// *************************************************************************** *
// *                                                                           *
// *                      Mentor Graphics Corporation                          *
// *                          All rights reserved                              *
// *                                                                           *
// *************************************************************************** *
// *                                                                           *
// * Description:         Partial CANDB File (for BMS Node)                    *
// * Generated at:        2025-09-16 19:54                                     *
// * Node                 BMS                                                  *
// *                                                                           *
// *************************************************************************** *
// *                                                                           *
// *             THIS CONFIGURATION MIGHT CONTAIN SOME ERRORS                  *
// *              IF THE INPUT MODEL WAS NOT PROPERLY FORMED!                  *
// *                    Do Not Use this File directly!                         *
// *                                                                           *
// *************************************************************************** *
VERSION "BMS"

NS_ :

BS_ :

BU_ : BMS

BO_ 1021 BMS_PTCANFD_0x3FD : 32 BMS
 SG_ HvBattTempRSMS65 : 7|9@0+ (0.5,-40.0) [-40.0|215.5] "℃" Vector__XXX
 SG_ HvBattTempRSMS66 : 23|9@0+ (0.5,-40.0) [-40.0|215.5] "℃" Vector__XXX
 SG_ HvBattTempRSMS67 : 39|9@0+ (0.5,-40.0) [-40.0|215.5] "℃" Vector__XXX
 SG_ HvBattTempRSMS68 : 55|9@0+ (0.5,-40.0) [-40.0|215.5] "℃" Vector__XXX
 SG_ HvBattTempRSMS69 : 71|9@0+ (0.5,-40.0) [-40.0|215.5] "℃" Vector__XXX
 SG_ HvBattTempRSMS70 : 87|9@0+ (0.5,-40.0) [-40.0|215.5] "℃" Vector__XXX
 SG_ HvBattTempRSMS71 : 103|9@0+ (0.5,-40.0) [-40.0|215.5] "℃" Vector__XXX
 SG_ HvBattTempRSMS72 : 119|9@0+ (0.5,-40.0) [-40.0|215.5] "℃" Vector__XXX
 SG_ HvBattTempRSMS73 : 135|9@0+ (0.5,-40.0) [-40.0|215.5] "℃" Vector__XXX
 SG_ HvBattTempRSMS74 : 151|9@0+ (0.5,-40.0) [-40.0|215.5] "℃" Vector__XXX
 SG_ HvBattTempRSMS75 : 167|9@0+ (0.5,-40.0) [-40.0|215.5] "℃" Vector__XXX
 SG_ HvBattTempRSMS76 : 183|9@0+ (0.5,-40.0) [-40.0|215.5] "℃" Vector__XXX
 SG_ HvBattTempRSMS77 : 199|9@0+ (0.5,-40.0) [-40.0|215.5] "℃" Vector__XXX
 SG_ HvBattTempRSMS78 : 215|9@0+ (0.5,-40.0) [-40.0|215.5] "℃" Vector__XXX
 SG_ HvBattTempRSMS79 : 231|9@0+ (0.5,-40.0) [-40.0|215.5] "℃" Vector__XXX
 SG_ HvBattTempRSMS80 : 247|9@0+ (0.5,-40.0) [-40.0|215.5] "℃" Vector__XXX

BO_ 1022 BMS_PTCANFD_0x3FE : 32 BMS
 SG_ HvBattTempRSMS81 : 7|9@0+ (0.5,-40.0) [-40.0|215.5] "℃" Vector__XXX
 SG_ HvBattTempRSMS82 : 23|9@0+ (0.5,-40.0) [-40.0|215.5] "℃" Vector__XXX
 SG_ HvBattTempRSMS83 : 39|9@0+ (0.5,-40.0) [-40.0|215.5] "℃" Vector__XXX
 SG_ HvBattTempRSMS84 : 55|9@0+ (0.5,-40.0) [-40.0|215.5] "℃" Vector__XXX
 SG_ HvBattTempRSMS85 : 71|9@0+ (0.5,-40.0) [-40.0|215.5] "℃" Vector__XXX
 SG_ HvBattTempRSMS86 : 87|9@0+ (0.5,-40.0) [-40.0|215.5] "℃" Vector__XXX
 SG_ HvBattTempRSMS87 : 103|9@0+ (0.5,-40.0) [-40.0|215.5] "℃" Vector__XXX
 SG_ HvBattTempRSMS88 : 119|9@0+ (0.5,-40.0) [-40.0|215.5] "℃" Vector__XXX
 SG_ HvBattTempRSMS89 : 135|9@0+ (0.5,-40.0) [-40.0|215.5] "℃" Vector__XXX
 SG_ HvBattTempRSMS90 : 151|9@0+ (0.5,-40.0) [-40.0|215.5] "℃" Vector__XXX
 SG_ HvBattTempRSMS91 : 167|9@0+ (0.5,-40.0) [-40.0|215.5] "℃" Vector__XXX
 SG_ HvBattTempRSMS92 : 183|9@0+ (0.5,-40.0) [-40.0|215.5] "℃" Vector__XXX
 SG_ HvBattTempRSMS93 : 199|9@0+ (0.5,-40.0) [-40.0|215.5] "℃" Vector__XXX
 SG_ HvBattTempRSMS94 : 215|9@0+ (0.5,-40.0) [-40.0|215.5] "℃" Vector__XXX
 SG_ HvBattTempRSMS95 : 231|9@0+ (0.5,-40.0) [-40.0|215.5] "℃" Vector__XXX
 SG_ HvBattTempRSMS96 : 247|9@0+ (0.5,-40.0) [-40.0|215.5] "℃" Vector__XXX

BO_ 137 BMS_PTCANFD_0x89 : 8 BMS
 SG_ HvBattChargerNumber : 7|32@0+ (1.0,0.0) [0.0|268435455.0] "" Vector__XXX
 SG_ HvBattChargerRegionalCode : 39|24@0+ (1.0,0.0) [0.0|16777215.0] "" Vector__XXX

BO_ 145 BMS_PTCANFD_0x91 : 48 BMS
 SG_ BMSChrgrCntctSts : 191|3@0+ (1,0) [0|7] "" Vector__XXX
 SG_ BoostChrgnOutpCurReq : 271|14@0+ (0.1,0.0) [0.0|1000.0] "A" Vector__XXX
 SG_ BoostChrgnOutpReqSigGrpChks : 255|8@0+ (1.0,0.0) [0.0|255.0] "" Vector__XXX
 SG_ BoostChrgnOutpReqSigGrpCntr : 259|4@0+ (1.0,0.0) [0.0|15.0] "" Vector__XXX
 SG_ BoostChrgnOutpUReq : 287|14@0+ (0.1,0.0) [0.0|1638.3000000000002] "V" Vector__XXX
 SG_ ChrgnNotAvlForFault : 143|2@0+ (1,0) [0|3] "" Vector__XXX
 SG_ ChrgnNotAvlForT : 132|2@0+ (1,0) [0|3] "" Vector__XXX
 SG_ DCChrgrConnectnSts : 135|3@0+ (1,0) [0|7] "" Vector__XXX
 SG_ DCChrgrSigGrpChks : 119|8@0+ (1,0) [0|255] "" Vector__XXX
 SG_ DCChrgrSigGrpCntr : 123|4@0+ (1,0) [0|15] "" Vector__XXX
 SG_ DchaNotAvlForFlt : 129|2@0+ (1,0) [0|3] "" Vector__XXX
 SG_ HvBattActBusU : 71|14@0+ (0.1,0.0) [0.0|1638.2] "V" Vector__XXX
 SG_ HvBattActCur : 87|16@0+ (0.1,-3276.7) [-3276.7|3276.7000000000007] "A" Vector__XXX
 SG_ HvBattActPackU : 47|14@0+ (0.1,0.0) [0.0|1638.2] "V" Vector__XXX
 SG_ HvBattActPwr : 159|13@0+ (0.25,-1000.0) [-1000.0|1047.75] "Kw" Vector__XXX
 SG_ HvBattaftcoolgReq : 243|1@0+ (1,0) [0|1] "" Vector__XXX
 SG_ HvBattBkdheatgReq : 245|1@0+ (1,0) [0|1] "" Vector__XXX
 SG_ HvBattDrtSts : 247|1@0+ (1,0) [0|1] "" Vector__XXX
 SG_ HvBattFltLvlIndcn : 63|3@0+ (1,0) [0|7] "" Vector__XXX
 SG_ HvBattMaxPwrChrgn : 27|12@0+ (0.25,0.0) [0.0|1000.0] "kW" Vector__XXX
 SG_ HvBattMaxPwrDchrgn : 103|13@0+ (0.25,0.0) [0.0|2047.75] "kW" Vector__XXX
 SG_ HvBattMaxPwrDchrgnContns : 175|12@0+ (0.25,0.0) [0.0|1000.0] "kW" Vector__XXX
 SG_ HvBattModSts : 147|4@0+ (1,0) [0|15] "" Vector__XXX
 SG_ HvBattOverHeatWarn : 73|1@0+ (1,0) [0|1] "" Vector__XXX
 SG_ HvBattSigGrpChks : 7|8@0+ (1,0) [0|255] "" Vector__XXX
 SG_ HvBattSigGrpCntr : 11|4@0+ (1,0) [0|15] "" Vector__XXX
 SG_ HvBattThermModReq : 151|4@0+ (1,0) [0|15] "" Vector__XXX
 SG_ HvBattUkl30LowWarn : 244|1@0+ (1,0) [0|1] "" Vector__XXX
 SG_ HvBattWrmgReq : 246|1@0+ (1,0) [0|1] "" Vector__XXX
 SG_ HVOffReq : 49|2@0+ (1,0) [0|3] "" Vector__XXX
 SG_ MainCntctCtrlFlg : 223|1@0+ (1,0) [0|1] "" Vector__XXX
 SG_ MainCntctInhbn : 161|1@0+ (1,0) [0|1] "" Vector__XXX
 SG_ MainCntctSts : 222|2@0+ (1,0) [0|3] "" Vector__XXX
 SG_ MainCntctStsSigGrpChks : 207|8@0+ (1,0) [0|255] "" Vector__XXX
 SG_ MainCntctStsSigGrpCntr : 211|4@0+ (1,0) [0|15] "" Vector__XXX
 SG_ MainNegCntctSts : 15|2@0+ (1,0) [0|3] "" Vector__XXX
 SG_ MainPosCntctSts : 13|2@0+ (1,0) [0|3] "" Vector__XXX
 SG_ OverChargeCurrFatalFault : 179|1@0+ (1,0) [0|1] "" Vector__XXX
 SG_ OverDischargeCurrFatalFault : 178|1@0+ (1,0) [0|1] "" Vector__XXX
 SG_ PrechrgnCntctSts : 242|2@0+ (1,0) [0|3] "" Vector__XXX

BO_ 148 BMS_PTCANFD_0x94 : 48 BMS
 SG_ CrsPwmSts : 255|2@0+ (1,0) [0|3] "" Vector__XXX
 SG_ GaCMDAfeComErrFault : 22|1@0+ (1,0) [0|1] "" Vector__XXX
 SG_ GaCMDCellVoltOpenWireLv1F : 41|1@0+ (1,0) [0|1] "" Vector__XXX
 SG_ GaCMDCellVoltOpenWireLv2F : 83|1@0+ (1,0) [0|1] "" Vector__XXX
 SG_ GaCMDCellVoltSamplingChipFault : 19|1@0+ (1,0) [0|1] "" Vector__XXX
 SG_ GaCMDModltempOpenWireLv1F : 20|1@0+ (1,0) [0|1] "" Vector__XXX
 SG_ GaCMDModltempOpenWireLv2F : 82|1@0+ (1,0) [0|1] "" Vector__XXX
 SG_ GaCMDModlTempSamplingChipFault : 43|1@0+ (1,0) [0|1] "" Vector__XXX
 SG_ GaCVTAfeCellVoltOORFault : 64|1@0+ (1,0) [0|1] "" Vector__XXX
 SG_ GeBCVBatteryOverVoltageFault : 12|1@0+ (1,0) [0|1] "" Vector__XXX
 SG_ GeBCVBatteryUnderVoltageFault : 79|1@0+ (1,0) [0|1] "" Vector__XXX
 SG_ GeBCVBatteryVoltageOoRFault : 5|1@0+ (1,0) [0|1] "" Vector__XXX
 SG_ GeBCVDCFuseOLFault : 34|1@0+ (1,0) [0|1] "" Vector__XXX
 SG_ GeBCVDCFuseOoRFault : 33|1@0+ (1,0) [0|1] "" Vector__XXX
 SG_ GeBCVHVADCComDiagFault : 78|1@0+ (1,0) [0|1] "" Vector__XXX
 SG_ GeBCVMainDriveFuseOLFault : 77|1@0+ (1,0) [0|1] "" Vector__XXX
 SG_ GeBCVMainDriveFuseOoRFault : 6|1@0+ (1,0) [0|1] "" Vector__XXX
 SG_ GeBCVPackVoltageMismatchFault : 32|1@0+ (1,0) [0|1] "" Vector__XXX
 SG_ GeBCVShuntADCSpiComFault : 76|1@0+ (1,0) [0|1] "" Vector__XXX
 SG_ GeBCVShunttempHighFault : 75|1@0+ (1,0) [0|1] "" Vector__XXX
 SG_ GeBCVShunttempLowFault : 74|1@0+ (1,0) [0|1] "" Vector__XXX
 SG_ GeBCVVdncGpknOoRFault : 73|1@0+ (1,0) [0|1] "" Vector__XXX
 SG_ GeBCVVdpcGpknOoRFault : 47|1@0+ (1,0) [0|1] "" Vector__XXX
 SG_ GeBCVVmncGpknOoRFault : 7|1@0+ (1,0) [0|1] "" Vector__XXX
 SG_ GeBCVVmpcGpknOoRFault : 72|1@0+ (1,0) [0|1] "" Vector__XXX
 SG_ GeBMMKL30CLowVoltageFault : 87|1@0+ (1,0) [0|1] "" Vector__XXX
 SG_ GeBMMKL30CUnderVoltageFault : 8|1@0+ (1,0) [0|1] "" Vector__XXX
 SG_ GeBMMKL30CVoltSrcMaxFault : 9|1@0+ (1,0) [0|1] "" Vector__XXX
 SG_ GeBMMKL30CVoltSrcMinFault : 10|1@0+ (1,0) [0|1] "" Vector__XXX
 SG_ GeBMMKL30VoltSrcMaxFault : 11|1@0+ (1,0) [0|1] "" Vector__XXX
 SG_ GeBMMKL30VoltSrcMinFault : 86|1@0+ (1,0) [0|1] "" Vector__XXX
 SG_ GeCMDAfeDietempMsgCheckFailFault : 85|1@0+ (1,0) [0|1] "" Vector__XXX
 SG_ GeCMDAfeDietempMsgTimeoutFault : 84|1@0+ (1,0) [0|1] "" Vector__XXX
 SG_ GeCMDCellBaltempMsgCheckFailF : 40|1@0+ (1,0) [0|1] "" Vector__XXX
 SG_ GeCMDDaisyChainComSuspendFault : 3|1@0+ (1,0) [0|1] "" Vector__XXX
 SG_ GeCRSVehicleCrashFault : 80|1@0+ (1,0) [0|1] "" Vector__XXX
 SG_ GeCTDDCFuseBlownFault : 2|1@0+ (1,0) [0|1] "" Vector__XXX
 SG_ GeCTDDNCStuckcloseFault : 95|1@0+ (1,0) [0|1] "" Vector__XXX
 SG_ GeCTDDNCStuckopenFault : 55|1@0+ (1,0) [0|1] "" Vector__XXX
 SG_ GeCTDDPCStuckcloseFault : 13|1@0+ (1,0) [0|1] "" Vector__XXX
 SG_ GeCTDDPCStuckopenFault : 54|1@0+ (1,0) [0|1] "" Vector__XXX
 SG_ GeCTDMDFuseBlownFault : 53|1@0+ (1,0) [0|1] "" Vector__XXX
 SG_ GeCTDMNCStuckcloseFault : 94|1@0+ (1,0) [0|1] "" Vector__XXX
 SG_ GeCTDMNCStuckopenFault : 52|1@0+ (1,0) [0|1] "" Vector__XXX
 SG_ GeCTDMPCStuckcloseFault : 93|1@0+ (1,0) [0|1] "" Vector__XXX
 SG_ GeCTDMPCStuckopenFault : 92|1@0+ (1,0) [0|1] "" Vector__XXX
 SG_ GeCTDMPRStuckopenFault : 14|1@0+ (1,0) [0|1] "" Vector__XXX
 SG_ GeCTDPrechargeBusShortFault : 51|1@0+ (1,0) [0|1] "" Vector__XXX
 SG_ GeCTDPrechargeTimeoutFault : 50|1@0+ (1,0) [0|1] "" Vector__XXX
 SG_ GeCTSPrechargeOverTimesFault : 49|1@0+ (1,0) [0|1] "" Vector__XXX
 SG_ GeCVTCellOverVoltL1Fault : 15|1@0+ (1,0) [0|1] "" Vector__XXX
 SG_ GeCVTCellOverVoltL2Fault : 91|1@0+ (1,0) [0|1] "" Vector__XXX
 SG_ GeCVTCellOverVoltL3Fault : 48|1@0+ (1,0) [0|1] "" Vector__XXX
 SG_ GeCVTCellOverVoltL4Fault : 16|1@0+ (1,0) [0|1] "" Vector__XXX
 SG_ GeCVTCellUnderVoltL1Fault : 90|1@0+ (1,0) [0|1] "" Vector__XXX
 SG_ GeCVTCellUnderVoltL2Fault : 63|1@0+ (1,0) [0|1] "" Vector__XXX
 SG_ GeCVTCellUnderVoltL3Fault : 89|1@0+ (1,0) [0|1] "" Vector__XXX
 SG_ GeCVTCellUnderVoltL4Fault : 88|1@0+ (1,0) [0|1] "" Vector__XXX
 SG_ GeCVTCellVoltOverDeviationL1F : 62|1@0+ (1,0) [0|1] "" Vector__XXX
 SG_ GeCVTCellVoltOverDeviationL2F : 61|1@0+ (1,0) [0|1] "" Vector__XXX
 SG_ GeDCCAPlusVoltageOoRFault : 60|1@0+ (1,0) [0|1] "" Vector__XXX
 SG_ GeDCCCC2VoltageAbnormalFault : 103|1@0+ (1,0) [0|1] "" Vector__XXX
 SG_ GeDCCConnectortempHighFault : 101|1@0+ (1,0) [0|1] "" Vector__XXX
 SG_ GeDCCConnectortempHighWarningF : 100|1@0+ (1,0) [0|1] "" Vector__XXX
 SG_ GeHVILVIL2CircuitOpenFault : 58|1@0+ (1,0) [0|1] "" Vector__XXX
 SG_ GePFCPyroFuseCloseFault : 57|1@0+ (1,0) [0|1] "" Vector__XXX
 SG_ GePFCPyroFuseOpenFault : 56|1@0+ (1,0) [0|1] "" Vector__XXX
 SG_ GePRXPrivateCANBusOffFault : 99|1@0+ (1.0,0.0) [0.0|1.0] "" Vector__XXX
 SG_ GeSOFDischargeOverCurrentLv1F : 17|1@0+ (1,0) [0|1] "" Vector__XXX
 SG_ GeSOFDischargeOverCurrentLv2F : 18|1@0+ (1,0) [0|1] "" Vector__XXX
 SG_ GeSOFDischargeOverCurrentLv3F : 46|1@0+ (1,0) [0|1] "" Vector__XXX
 SG_ GeSOFDischargeOverCurrentLv4F : 45|1@0+ (1,0) [0|1] "" Vector__XXX
 SG_ GeSOFDischargeOverCurrentLv5F : 44|1@0+ (1,0) [0|1] "" Vector__XXX
 SG_ GeSOFRegenChargeOverCurrentLv1F : 71|1@0+ (1,0) [0|1] "" Vector__XXX
 SG_ GeSOFRegenChargeOverCurrentLv2F : 70|1@0+ (1,0) [0|1] "" Vector__XXX
 SG_ GeSOFRegenChargeOverCurrentLv3F : 21|1@0+ (1,0) [0|1] "" Vector__XXX
 SG_ GeSOFRegenChargeOverCurrentLv4F : 81|1@0+ (1,0) [0|1] "" Vector__XXX
 SG_ GeSOFRegenChargeOverCurrentLv5F : 42|1@0+ (1,0) [0|1] "" Vector__XXX
 SG_ GeTHMCoolFlowMismatchFault : 69|1@0+ (1,0) [0|1] "" Vector__XXX
 SG_ GeTHMCoolSysFault : 68|1@0+ (1,0) [0|1] "" Vector__XXX
 SG_ GeTHMHeatFlowMismatchFault : 67|1@0+ (1,0) [0|1] "" Vector__XXX
 SG_ GeTHMInlettempHighFault : 98|1@0+ (1,0) [0|1] "" Vector__XXX
 SG_ GeTHMInlettempLowFault : 66|1@0+ (1,0) [0|1] "" Vector__XXX
 SG_ GeTHRThermalRunAwayFault : 97|1@0+ (1,0) [0|1] "" Vector__XXX
 SG_ GeVRXPTCANBusOffFault : 65|1@0+ (1,0) [0|1] "" Vector__XXX
 SG_ GeVRXVCCD090TimeOutFault : 96|1@0+ (1,0) [0|1] "" Vector__XXX
 SG_ GeVRXVCCD271TimeOutFault : 111|1@0+ (1,0) [0|1] "" Vector__XXX
 SG_ HvBattCntctCtrlSt : 183|8@0+ (1.0,0.0) [0.0|255.0] "" Vector__XXX
 SG_ HvbattCrsPwmStsSigGrpChks : 239|8@0+ (1.0,0.0) [0.0|255.0] "" Vector__XXX
 SG_ HvbattCrsPwmStsSigGrpCntr : 243|4@0+ (1.0,0.0) [0.0|15.0] "" Vector__XXX
 SG_ HvBattCurLimMax : 135|16@0+ (1.0,-32767.0) [-32767.0|32768.0] "A" Vector__XXX
 SG_ HvBattCurLimMin : 151|16@0+ (1.0,-32767.0) [-32767.0|32768.0] "A" Vector__XXX
 SG_ HvBattDevmtGrp01 : 263|32@0+ (1.0,0.0) [0.0|0.0] "" Vector__XXX
 SG_ HvBattDevmtGrp02 : 295|32@0+ (1.0,0.0) [0.0|0.0] "" Vector__XXX
 SG_ HvBattDevmtGrp03 : 327|32@0+ (1.0,0.0) [0.0|0.0] "" Vector__XXX
 SG_ HvBattDevmtGrp04 : 359|32@0+ (1.0,0.0) [0.0|0.0] "" Vector__XXX
 SG_ HvBattDNCHSDEna : 173|1@0+ (1,0) [0|1] "" Vector__XXX
 SG_ HvBattDNCLSDEna : 172|1@0+ (1,0) [0|1] "" Vector__XXX
 SG_ HvBattDPCHSDEna : 171|1@0+ (1,0) [0|1] "" Vector__XXX
 SG_ HvBattDPCLSDEna : 169|1@0+ (1,0) [0|1] "" Vector__XXX
 SG_ HvBattInsulGndSwtSt : 168|1@0+ (1,0) [0|1] "" Vector__XXX
 SG_ HvBattInsulNegSwtSt : 167|1@0+ (1,0) [0|1] "" Vector__XXX
 SG_ HvBattInsulPosSwtSt : 166|1@0+ (1,0) [0|1] "" Vector__XXX
 SG_ HvBattMNCHSDEna : 165|1@0+ (1,0) [0|1] "" Vector__XXX
 SG_ HvBattMNCLSDEna : 164|1@0+ (1,0) [0|1] "" Vector__XXX
 SG_ HvBattMPCHSDEna : 163|1@0+ (1,0) [0|1] "" Vector__XXX
 SG_ HvBattMPCLSDEna : 162|1@0+ (1,0) [0|1] "" Vector__XXX
 SG_ HvBattMPRHSDEna : 161|1@0+ (1,0) [0|1] "" Vector__XXX
 SG_ HvBattMPRLSDEna : 160|1@0+ (1,0) [0|1] "" Vector__XXX
 SG_ HvBattUkl30 : 119|9@0+ (0.1,0.0) [0.0|51.1] "V" Vector__XXX
 SG_ HvBattWorkSts : 191|8@0+ (1.0,0.0) [0.0|255.0] "" Vector__XXX
 SG_ HVISOMeasState : 37|3@0+ (1.0,0.0) [0.0|7.0] "" Vector__XXX
 SG_ HVIsoNegVolt : 199|15@0+ (0.1,-1638.4) [-1638.4|1638.3000000000002] "" Vector__XXX
 SG_ HVIsoPosVolt : 215|15@0+ (0.1,-1638.4) [-1638.4|1638.3000000000002] "" Vector__XXX
 SG_ IsoGndMosDiagVolt : 31|8@0+ (0.1,0.0) [0.0|25.5] "V" Vector__XXX
 SG_ PyroFuseSts : 1|1@0+ (1,0) [0|1] "" Vector__XXX

BO_ 159 BMS_PTCANFD_0x9F : 16 BMS
 SG_ HvBattCSR21 : 7|32@0+ (1,0) [0|4294967295] "" Vector__XXX
 SG_ HvBattCSR22 : 39|32@0+ (1,0) [0|4294967295] "" Vector__XXX
 SG_ HvBattCSR23 : 71|32@0+ (1,0) [0|4294967295] "" Vector__XXX
 SG_ HvBattCSR24 : 103|32@0+ (1,0) [0|4294967295] "" Vector__XXX

BO_ 1305 BMSPtCanfdNMFr : 8 BMS
 SG_ BMSPtCanfdActiveWakeup : 12|1@0+ (1,0) [0|1] "" Vector__XXX
 SG_ BMSPtCanfdNodeAddress : 7|8@0+ (1.0,0.0) [0.0|255.0] "" Vector__XXX
 SG_ BMSPtCanfdRepeatMsgReq : 8|1@0+ (1,0) [0|1] "" Vector__XXX
 SG_ BMSPtCanfdRepeatMsgSt : 16|1@0+ (1,0) [0|1] "" Vector__XXX
 SG_ NMKeepAwkRsnBMS : 48|9@0+ (1.0,0.0) [0.0|511.0] "" Vector__XXX
 SG_ PNC55BMS : 55|1@0+ (1,0) [0|1] "" Vector__XXX
 SG_ UDB17BMS : 17|1@0+ (1,0) [0|1] "" Vector__XXX
 SG_ UDB18BMS : 18|1@0+ (1,0) [0|1] "" Vector__XXX
 SG_ UDB19BMS : 19|1@0+ (1,0) [0|1] "" Vector__XXX
 SG_ UDB20BMS : 20|1@0+ (1,0) [0|1] "" Vector__XXX
 SG_ UDB21BMS : 21|1@0+ (1,0) [0|1] "" Vector__XXX
 SG_ UDB22BMS : 22|1@0+ (1,0) [0|1] "" Vector__XXX
 SG_ UDB23BMS : 23|1@0+ (1,0) [0|1] "" Vector__XXX
 SG_ UDB24BMS : 24|1@0+ (1,0) [0|1] "" Vector__XXX
 SG_ UDB25BMS : 25|1@0+ (1,0) [0|1] "" Vector__XXX
 SG_ UDB26BMS : 26|1@0+ (1,0) [0|1] "" Vector__XXX
 SG_ UDB27BMS : 27|1@0+ (1,0) [0|1] "" Vector__XXX
 SG_ UDB28BMS : 28|1@0+ (1,0) [0|1] "" Vector__XXX
 SG_ UDB29BMS : 29|1@0+ (1,0) [0|1] "" Vector__XXX
 SG_ UDB30BMS : 30|1@0+ (1,0) [0|1] "" Vector__XXX
 SG_ UDB31BMS : 31|1@0+ (1,0) [0|1] "" Vector__XXX
 SG_ UDB32BMS : 32|1@0+ (1,0) [0|1] "" Vector__XXX
 SG_ UDB33BMS : 33|1@0+ (1,0) [0|1] "" Vector__XXX
 SG_ UDB34BMS : 34|1@0+ (1,0) [0|1] "" Vector__XXX
 SG_ UDB35BMS : 35|1@0+ (1,0) [0|1] "" Vector__XXX
 SG_ UDB36BMS : 36|1@0+ (1,0) [0|1] "" Vector__XXX
 SG_ UDB37BMS : 37|1@0+ (1,0) [0|1] "" Vector__XXX
 SG_ UDB38BMS : 38|1@0+ (1,0) [0|1] "" Vector__XXX
 SG_ UDB39BMS : 39|1@0+ (1,0) [0|1] "" Vector__XXX
 SG_ UDB40BMS : 40|1@0+ (1.0,0.0) [0.0|1.0] "" Vector__XXX
 SG_ UDB41BMS : 41|1@0+ (1,0) [0|1] "" Vector__XXX
 SG_ UDB42BMS : 42|1@0+ (1,0) [0|1] "" Vector__XXX
 SG_ UDB43BMS : 43|1@0+ (1,0) [0|1] "" Vector__XXX
 SG_ UDB44BMS : 44|1@0+ (1,0) [0|1] "" Vector__XXX
 SG_ UDB45BMS : 45|1@0+ (1,0) [0|1] "" Vector__XXX
 SG_ UDB46BMS : 46|1@0+ (1,0) [0|1] "" Vector__XXX
 SG_ UDB47BMS : 47|1@0+ (1.0,0.0) [0.0|1.0] "" Vector__XXX

BO_ 1588 BMSToXCDPtDiagRespFr : 64 BMS
 SG_ BMSToVCCDDiagResp : 7|512@0+ (1,0) [0|0] "" Vector__XXX

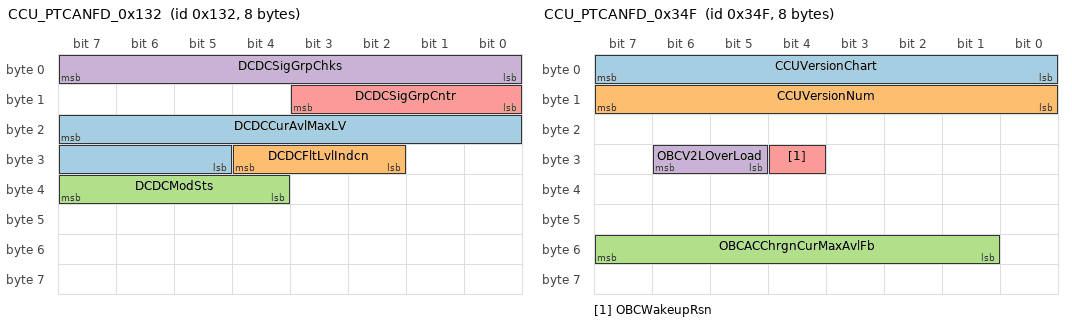
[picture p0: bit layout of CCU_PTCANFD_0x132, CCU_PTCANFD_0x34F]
BO_ 306 CCU_PTCANFD_0x132 : 8 BMS
 SG_ DCDCCurAvlMaxLV : 23|11@0+ (0.5,0.0) [0.0|1023.0] "A" Vector__XXX
 SG_ DCDCFltLvlIndcn : 28|3@0+ (1,0) [0|7] "" Vector__XXX
 SG_ DCDCModSts : 39|4@0+ (1,0) [0|15] "" Vector__XXX
 SG_ DCDCSigGrpChks : 7|8@0+ (1.0,0.0) [0.0|255.0] "" Vector__XXX
 SG_ DCDCSigGrpCntr : 11|4@0+ (1.0,0.0) [0.0|15.0] "" Vector__XXX

BO_ 320 CCU_PTCANFD_0x140 : 48 BMS
 SG_ CCUSensKL30U : 279|9@0+ (0.1,0.0) [0.0|51.1] "V" Vector__XXX
 SG_ DCDCPrechrgLvUVPFstVal : 343|9@0+ (0.1,0.0) [0.0|51.1] "V" Vector__XXX
 SG_ OBCAcCurActL1 : 138|11@0+ (0.1,-102.4) [-102.4|102.20000000000002] "A" Vector__XXX
 SG_ OBCAcCurActL2 : 162|11@0+ (0.1,-102.4) [-102.4|102.20000000000002] "A" Vector__XXX
 SG_ OBCAcCurActL3 : 186|11@0+ (0.1,-102.4) [-102.4|102.20000000000002] "A" Vector__XXX
 SG_ OBCAcU1Frq : 222|7@0+ (1.0,0.0) [0.0|127.0] "Hz" Vector__XXX
 SG_ OBCAcU2Frq : 134|7@0+ (1.0,0.0) [0.0|127.0] "Hz" Vector__XXX
 SG_ OBCAcU3Frq : 255|7@0+ (1.0,0.0) [0.0|127.0] "Hz" Vector__XXX
 SG_ OBCAcUActL1 : 159|10@0+ (1.0,0.0) [0.0|1022.0] "V" Vector__XXX
 SG_ OBCAcUActL2 : 183|10@0+ (1.0,0.0) [0.0|1022.0] "V" Vector__XXX
 SG_ OBCAcUActL3 : 207|10@0+ (1.0,0.0) [0.0|1022.0] "V" Vector__XXX
 SG_ OBCCcConnectnSts : 14|3@0+ (1,0) [0|7] "" Vector__XXX
 SG_ OBCCcR : 105|10@0+ (10.0,0.0) [0.0|10220.0] "Ω" Vector__XXX
 SG_ OBCChrgnPwrMax : 71|8@0+ (50.0,0.0) [0.0|12750.0] "W" Vector__XXX
 SG_ OBCCpDutyCyc : 263|10@0+ (0.1,0.0) [0.0|100.0] "%" Vector__XXX
 SG_ OBCCpDutyFrq : 31|14@0+ (0.1,0.0) [0.0|1638.3000000000002] "Hz" Vector__XXX
 SG_ OBCCpSts : 23|1@0+ (1,0) [0|1] "" Vector__XXX
 SG_ OBCCpU : 22|7@0+ (0.1,0.0) [0.0|12.600000000000001] "V" Vector__XXX
 SG_ OBCElockDrvU : 127|9@0+ (0.1,-25.5) [-25.5|25.5] "V" Vector__XXX
 SG_ OBCELockSts : 33|2@0+ (1,0) [0|3] "" Vector__XXX
 SG_ OBCFltLvlIndcn : 47|3@0+ (1,0) [0|7] "" Vector__XXX
 SG_ OBCHeatgStrtCmplFlg : 106|1@0+ (1,0) [0|1] "" Vector__XXX
 SG_ OBCHvDcCurAct : 79|11@0+ (0.1,-102.4) [-102.4|102.20000000000002] "A" Vector__XXX
 SG_ OBCHvDcSigGrpChks : 55|8@0+ (1,0) [0|255] "" Vector__XXX
 SG_ OBCHvDcSigGrpCntr : 59|4@0+ (1,0) [0|15] "" Vector__XXX
 SG_ OBCHvDcUAct : 81|10@0+ (1.0,0.0) [0.0|1022.0] "V" Vector__XXX
 SG_ OBCModSts : 110|3@0+ (1,0) [0|7] "" Vector__XXX
 SG_ OBCPFCoutCurAct : 231|11@0+ (0.1,-102.4) [-102.4|102.20000000000002] "A" Vector__XXX
 SG_ OBCPFCoutVoltAct : 233|10@0+ (1.0,0.0) [0.0|1022.0] "V" Vector__XXX
 SG_ OBCS2Sts : 15|1@0+ (1,0) [0|1] "" Vector__XXX
 SG_ OBCSigGrpChks : 7|8@0+ (1,0) [0|255] "" Vector__XXX
 SG_ OBCSigGrpCntr : 11|4@0+ (1,0) [0|15] "" Vector__XXX
 SG_ OBCV2xCurAvl : 103|9@0+ (0.1,0.0) [0.0|51.1] "A" Vector__XXX
 SG_ OBCV2xS1Sts : 286|1@0+ (1,0) [0|1] "" Vector__XXX
 SG_ OBCV2xS4Sts : 285|1@0+ (1,0) [0|1] "" Vector__XXX
 SG_ OBCWakeupU : 335|8@0+ (0.1,0.0) [0.0|25.5] "V" Vector__XXX

BO_ 655 CCU_PTCANFD_0x28F : 32 BMS
 SG_ CCUCooltFlowReq : 47|6@0+ (0.25,0.0) [0.0|15.75] "L/min" Vector__XXX
 SG_ CCUTCooltInlet : 55|8@0+ (1.0,-40.0) [-40.0|214.0] "℃" Vector__XXX
 SG_ DCDCActHVSigGrpChks : 63|8@0+ (1.0,0.0) [0.0|255.0] "" Vector__XXX
 SG_ DCDCActHVSigGrpCntr : 67|4@0+ (1.0,0.0) [0.0|15.0] "" Vector__XXX
 SG_ DCDCActT : 103|8@0+ (1.0,-40.0) [-40.0|214.0] "℃" Vector__XXX
 SG_ DCDCCurActHV : 79|9@0+ (0.1,-20.0) [-20.0|31.0] "A" Vector__XXX
 SG_ DCDCCurActLV : 111|12@0+ (0.5,-1000.0) [-1000.0|1047.0] "A" Vector__XXX
 SG_ DCDCDrtSts : 40|1@0+ (1,0) [0|1] "" Vector__XXX
 SG_ DCDCFltFlg : 31|1@0+ (1,0) [0|1] "" Vector__XXX
 SG_ DCDCFltQntyRSMS : 115|4@0+ (1.0,0.0) [0.0|15.0] "" Vector__XXX
 SG_ DCDCModFltRSMS : 1|2@0+ (1,0) [0|3] "" Vector__XXX
 SG_ DCDCSRMosT : 127|8@0+ (1.0,-40.0) [-40.0|214.0] "℃" Vector__XXX
 SG_ DCDCTOverFltRSMS : 3|2@0+ (1,0) [0|3] "" Vector__XXX
 SG_ DCDCUActHV : 83|12@0+ (0.25,0.0) [0.0|1023.5] "V" Vector__XXX
 SG_ DCDCUActLV : 135|15@0+ (0.001,0.0) [0.0|32.767] "V" Vector__XXX
 SG_ FltDCDCCTSampleWarn : 239|1@0+ (1,0) [0|1] "" Vector__XXX
 SG_ FltDCDCFSFlipFlopSlfChkErr : 238|1@0+ (1,0) [0|1] "" Vector__XXX
 SG_ FltDCDCFSOringLockSlfChkErr : 237|1@0+ (1,0) [0|1] "" Vector__XXX
 SG_ FltDCDCFSOringSlfChkErr : 236|1@0+ (1,0) [0|1] "" Vector__XXX
 SG_ FltDCDCFSOVPCircuitSlfChkErr : 11|1@0+ (1,0) [0|1] "" Vector__XXX
 SG_ FltDCDCHvdcUSelfChkErr : 18|1@0+ (1,0) [0|1] "" Vector__XXX
 SG_ FltDCDCLvCurSelfChkErr : 20|1@0+ (1,0) [0|1] "" Vector__XXX
 SG_ OBCActT : 151|8@0+ (1.0,-40.0) [-40.0|214.0] "℃" Vector__XXX
 SG_ OBCACVoltSts : 14|3@0+ (1,0) [0|7] "" Vector__XXX
 SG_ OBCChrgnPortSigGrpChks : 191|8@0+ (1,0) [0|255] "" Vector__XXX
 SG_ OBCChrgnPortSigGrpCntr : 195|4@0+ (1,0) [0|15] "" Vector__XXX
 SG_ OBCChrgnPortTL1 : 207|8@0+ (1.0,-40.0) [-40.0|214.0] "℃" Vector__XXX
 SG_ OBCChrgnPortTL2 : 215|8@0+ (1.0,-40.0) [-40.0|214.0] "℃" Vector__XXX
 SG_ OBCChrgnPortTL3 : 223|8@0+ (1.0,-40.0) [-40.0|214.0] "℃" Vector__XXX
 SG_ OBCChrgnPortTN : 231|8@0+ (1.0,-40.0) [-40.0|214.0] "℃" Vector__XXX
 SG_ OBCDrtSts : 32|1@0+ (1,0) [0|1] "" Vector__XXX
 SG_ OBCInsulR : 235|20@0+ (1.0,0.0) [0.0|1048575.0] "" Vector__XXX
 SG_ OBCMagMaxT : 159|8@0+ (1.0,-40.0) [-40.0|214.0] "℃" Vector__XXX
 SG_ OBCMaxAvlDchrgnPwr : 167|14@0+ (0.001,0.0) [0.0|16.383] "kW" Vector__XXX
 SG_ OBCPFCMosT : 183|8@0+ (1.0,-40.0) [-40.0|214.0] "℃" Vector__XXX

BO_ 677 CCU_PTCANFD_0x2A5 : 16 BMS
 SG_ CCUReserved1 : 63|8@0+ (1.0,0.0) [0.0|255.0] "" Vector__XXX
 SG_ CCUReserved2 : 79|8@0+ (1.0,0.0) [0.0|255.0] "" Vector__XXX
 SG_ CCUReserved3 : 87|8@0+ (1.0,0.0) [0.0|255.0] "" Vector__XXX
 SG_ CCUReserved4 : 103|8@0+ (1.0,0.0) [0.0|255.0] "" Vector__XXX
 SG_ CCUtype : 51|4@0+ (1.0,0.0) [0.0|15.0] "" Vector__XXX
 SG_ DCDCFaultCode : 23|8@0+ (1.0,0.0) [0.0|1.0] "" Vector__XXX
 SG_ EVSEFltFlg : 7|1@0+ (1,0) [0|1] "" Vector__XXX
 SG_ FltEVSECpDutyAbnorm : 15|1@0+ (1,0) [0|1] "" Vector__XXX
 SG_ FltOBCRealTiSelfChkAcAglLockErr : 33|1@0+ (1,0) [0|1] "" Vector__XXX
 SG_ FltOBCRealTiSelfChkAcCurErr : 34|1@0+ (1,0) [0|1] "" Vector__XXX
 SG_ FltOBCRealTiSelfChkAcUCurBiasErr : 36|1@0+ (1,0) [0|1] "" Vector__XXX
 SG_ FltOBCRealTiSelfChkAcUErr : 37|1@0+ (1,0) [0|1] "" Vector__XXX
 SG_ FltOBCRealTiSelfChkDcCurErr : 38|1@0+ (1,0) [0|1] "" Vector__XXX
 SG_ FltOBCRealTiSelfChkDcUErr : 39|1@0+ (1,0) [0|1] "" Vector__XXX
 SG_ FltOBCRealTiSelfChkLcCurBiasErr : 64|1@0+ (1,0) [0|1] "" Vector__XXX
 SG_ FltOBCRealTiSelfChkLcUErr : 92|1@0+ (1,0) [0|1] "" Vector__XXX
 SG_ FltOBCRealTiSelfChkPfcDrvErr : 91|1@0+ (1,0) [0|1] "" Vector__XXX
 SG_ FltOBCRealTiSelfChkV2LAcUErr : 40|1@0+ (1,0) [0|1] "" Vector__XXX
 SG_ FltOBCRealTiSelfChkV2LDcUErr : 41|1@0+ (1,0) [0|1] "" Vector__XXX
 SG_ OBCFaultCode : 31|8@0+ (1.0,0.0) [0.0|1.0] "" Vector__XXX
 SG_ OBCFltFlg : 52|1@0+ (1,0) [0|1] "" Vector__XXX

BO_ 847 CCU_PTCANFD_0x34F : 8 BMS
 SG_ CCUVersionChart : 7|8@0+ (1.0,0.0) [0.0|255.0] "" Vector__XXX
 SG_ CCUVersionNum : 15|8@0+ (1.0,0.0) [0.0|255.0] "" Vector__XXX
 SG_ OBCACChrgnCurMaxAvlFb : 55|7@0+ (1.0,0.0) [0.0|100.0] "A" Vector__XXX
 SG_ OBCV2LOverLoad : 30|2@0+ (1,0) [0|3] "" Vector__XXX
 SG_ OBCWakeupRsn : 28|1@0+ (1,0) [0|1] "" Vector__XXX

BO_ 943 CCU_PTCANFD_0x3AF : 16 BMS
 SG_ DrtDCDCCooltAbnorm : 7|1@0+ (1,0) [0|1] "" Vector__XXX
 SG_ DrtDCDCHvdcAbnorm : 6|1@0+ (1,0) [0|1] "" Vector__XXX
 SG_ DrtElockUnlck : 5|1@0+ (1,0) [0|1] "" Vector__XXX
 SG_ DrtEVSEAcPhaLoss : 4|1@0+ (1,0) [0|1] "" Vector__XXX
 SG_ DrtEVSEAcUAbnorm : 3|1@0+ (1,0) [0|1] "" Vector__XXX
 SG_ DrtInletOverT : 2|1@0+ (1,0) [0|1] "" Vector__XXX
 SG_ DrtInletSnsrErr : 1|1@0+ (1,0) [0|1] "" Vector__XXX
 SG_ DrtOBCCooltTAbnorm : 0|1@0+ (1,0) [0|1] "" Vector__XXX
 SG_ DrtOBCHvdcUAbnorm : 15|1@0+ (1,0) [0|1] "" Vector__XXX
 SG_ FltActvDchaTiOut : 14|1@0+ (1,0) [0|1] "" Vector__XXX
 SG_ FltBattSocRawCrcChkFail : 13|1@0+ (1,0) [0|1] "" Vector__XXX
 SG_ FltBattSocRawRolCntChkFail : 12|1@0+ (1,0) [0|1] "" Vector__XXX
 SG_ FltBattURawCrcChkFail : 11|1@0+ (1,0) [0|1] "" Vector__XXX
 SG_ FltBattURawRolCntChkFail : 10|1@0+ (1,0) [0|1] "" Vector__XXX
 SG_ FltCCUMcuErr : 9|1@0+ (1,0) [0|1] "" Vector__XXX
 SG_ FltCrashFail : 8|1@0+ (1,0) [0|1] "" Vector__XXX
 SG_ FltDCChrgrCrcChkFail : 23|1@0+ (1,0) [0|1] "" Vector__XXX
 SG_ FltDCChrgrRolCntChkFail : 22|1@0+ (1,0) [0|1] "" Vector__XXX
 SG_ FltDCDCAmbTAbnorm : 21|1@0+ (1,0) [0|1] "" Vector__XXX
 SG_ FltDCDCBoostCurAbnorm : 20|1@0+ (1,0) [0|1] "" Vector__XXX
 SG_ fltDCDCCooltAbnorm : 19|1@0+ (1,0) [0|1] "" Vector__XXX
 SG_ FltDCDCDspErr : 18|1@0+ (1,0) [0|1] "" Vector__XXX
 SG_ fltDCDCEcapError : 17|1@0+ (1,0) [0|1] "" Vector__XXX
 SG_ FltDCDCHvdcCurAbnorm : 16|1@0+ (1,0) [0|1] "" Vector__XXX
 SG_ FltDCDCHvdcOVP : 31|1@0+ (1,0) [0|1] "" Vector__XXX
 SG_ FltDCDCHvdcUVP : 30|1@0+ (1,0) [0|1] "" Vector__XXX
 SG_ FltDCDCInnerCANAbnorm : 29|1@0+ (1,0) [0|1] "" Vector__XXX
 SG_ FltDCDCLvccOVP : 28|1@0+ (1,0) [0|1] "" Vector__XXX
 SG_ FltDCDCLvccUVP : 27|1@0+ (1,0) [0|1] "" Vector__XXX
 SG_ FltDCDCLvCurReverse : 26|1@0+ (1,0) [0|1] "" Vector__XXX
 SG_ FltDCDCLvdcCurAbnorm : 25|1@0+ (1,0) [0|1] "" Vector__XXX
 SG_ FltDCDCLvdcOVP : 24|1@0+ (1,0) [0|1] "" Vector__XXX
 SG_ FltDCDCLvdcShort : 39|1@0+ (1,0) [0|1] "" Vector__XXX
 SG_ FltDCDCLvdcSrMosTAbnorm : 38|1@0+ (1,0) [0|1] "" Vector__XXX
 SG_ FltDCDCLvdcUoverHW : 37|1@0+ (1,0) [0|1] "" Vector__XXX
 SG_ FltDCDCLvdcUVP : 36|1@0+ (1,0) [0|1] "" Vector__XXX
 SG_ fltDCDCLvTerminalOpen : 35|1@0+ (1,0) [0|1] "" Vector__XXX
 SG_ FltDCDCLvUSelfChkErr : 34|1@0+ (1,0) [0|1] "" Vector__XXX
 SG_ FltDCDCOringMosTAbnorm : 33|1@0+ (1,0) [0|1] "" Vector__XXX
 SG_ FltDCDCPrechrgFail : 32|1@0+ (1,0) [0|1] "" Vector__XXX
 SG_ FltDCDCSigReqCrcChkFail : 47|1@0+ (1,0) [0|1] "" Vector__XXX
 SG_ FltDCDCSigReqRolCntChkFail : 46|1@0+ (1,0) [0|1] "" Vector__XXX
 SG_ FltDCDCStartFail : 45|1@0+ (1,0) [0|1] "" Vector__XXX
 SG_ FltElockDrvErr : 44|1@0+ (1,0) [0|1] "" Vector__XXX
 SG_ FltElockFbErr : 43|1@0+ (1,0) [0|1] "" Vector__XXX
 SG_ FltEVSEAcCurAbnorm : 42|1@0+ (1,0) [0|1] "" Vector__XXX
 SG_ FltEVSEAcFrqAbnorm : 41|1@0+ (1,0) [0|1] "" Vector__XXX
 SG_ FltEVSEAcOverU : 40|1@0+ (1,0) [0|1] "" Vector__XXX
 SG_ FltEVSEAcPhaAglUnbal : 55|1@0+ (1,0) [0|1] "" Vector__XXX
 SG_ FltEVSEAcPhaUUnbal : 54|1@0+ (1,0) [0|1] "" Vector__XXX
 SG_ FltEVSEAcUnderU : 53|1@0+ (1,0) [0|1] "" Vector__XXX
 SG_ FltEVSECpFrqAbnorm : 52|1@0+ (1,0) [0|1] "" Vector__XXX
 SG_ FltEVSECpUAbnorm : 51|1@0+ (1,0) [0|1] "" Vector__XXX
 SG_ FltEVSEUkwnCcR : 50|1@0+ (1,0) [0|1] "" Vector__XXX
 SG_ FltinletOverT : 49|1@0+ (1,0) [0|1] "" Vector__XXX
 SG_ FltLcMosTAbnorm : 48|1@0+ (1,0) [0|1] "" Vector__XXX
 SG_ FltMainCntctStsCrcChkFail : 63|1@0+ (1,0) [0|1] "" Vector__XXX
 SG_ FltMainCntctStsRolCntChkFail : 62|1@0+ (1,0) [0|1] "" Vector__XXX
 SG_ FltOBCCooltAbnorm : 61|1@0+ (1,0) [0|1] "" Vector__XXX
 SG_ FltOBCCooltSensAbnorm : 60|1@0+ (1,0) [0|1] "" Vector__XXX
 SG_ FltOBCDrivSupOVP : 59|1@0+ (1,0) [0|1] "" Vector__XXX
 SG_ FltOBCDrivSupUVP : 58|1@0+ (1,0) [0|1] "" Vector__XXX
 SG_ FltOBCDspErr : 57|1@0+ (1,0) [0|1] "" Vector__XXX
 SG_ FltOBCHvdcCurAbnorm : 56|1@0+ (1,0) [0|1] "" Vector__XXX
 SG_ FltOBCHvdcEcapComErr : 71|1@0+ (1,0) [0|1] "" Vector__XXX
 SG_ FltOBCHvdcOVP : 70|1@0+ (1,0) [0|1] "" Vector__XXX
 SG_ FltOBCHvdcShoCirc : 69|1@0+ (1,0) [0|1] "" Vector__XXX
 SG_ FltOBCHvdcUVP : 68|1@0+ (1,0) [0|1] "" Vector__XXX
 SG_ FltOBCInnerCanLos : 67|1@0+ (1,0) [0|1] "" Vector__XXX
 SG_ FltOBCKL30Ovp : 66|1@0+ (1,0) [0|1] "" Vector__XXX
 SG_ FltOBCKL30Uvp : 65|1@0+ (1,0) [0|1] "" Vector__XXX
 SG_ FltOBCLcDrvErr : 64|1@0+ (1,0) [0|1] "" Vector__XXX
 SG_ FltOBCLcOverCur : 79|1@0+ (1,0) [0|1] "" Vector__XXX
 SG_ FltOBCModRespTiOut : 78|1@0+ (1,0) [0|1] "" Vector__XXX
 SG_ FltOBCMosTsensErr : 77|1@0+ (1,0) [0|1] "" Vector__XXX
 SG_ FltOBCPcbTAbnorm : 76|1@0+ (1,0) [0|1] "" Vector__XXX
 SG_ FltOBCPfcBusPreChrgFaild : 75|1@0+ (1,0) [0|1] "" Vector__XXX
 SG_ FltOBCPfcHwErr : 74|1@0+ (1,0) [0|1] "" Vector__XXX
 SG_ FltOBCPfcOVP : 73|1@0+ (1,0) [0|1] "" Vector__XXX
 SG_ FltOBCPfcUVP : 72|1@0+ (1,0) [0|1] "" Vector__XXX
 SG_ FltOBCPtCanAcuLos : 87|1@0+ (1,0) [0|1] "" Vector__XXX
 SG_ FltOBCPtCanBcsLos : 86|1@0+ (1,0) [0|1] "" Vector__XXX
 SG_ FltOBCPtCanBmdmLos : 85|1@0+ (1,0) [0|1] "" Vector__XXX
 SG_ FltOBCPtCanBmsLos : 84|1@0+ (1,0) [0|1] "" Vector__XXX
 SG_ FltOBCPtCanBusOff : 83|1@0+ (1,0) [0|1] "" Vector__XXX
 SG_ FltOBCPtCanTboxLos : 82|1@0+ (1,0) [0|1] "" Vector__XXX
 SG_ FltOBCPtCanTDcdLos : 81|1@0+ (1,0) [0|1] "" Vector__XXX
 SG_ FltOBCPtCanVcuLos : 80|1@0+ (1,0) [0|1] "" Vector__XXX
 SG_ FltOBCPvccOVP : 95|1@0+ (1,0) [0|1] "" Vector__XXX
 SG_ FltOBCPvccUVP : 94|1@0+ (1,0) [0|1] "" Vector__XXX
 SG_ FltOBCRealTiSelfChkAcFrqErr : 93|1@0+ (1,0) [0|1] "" Vector__XXX
 SG_ FltOBCSigAcuCrcChkFail : 92|1@0+ (1,0) [0|1] "" Vector__XXX
 SG_ FltOBCSigAcuRolCntChkFail : 91|1@0+ (1,0) [0|1] "" Vector__XXX
 SG_ FltOBCSigChrgnCrcChkFail : 90|1@0+ (1,0) [0|1] "" Vector__XXX
 SG_ FltOBCSigChrgnRolCntChkFail : 89|1@0+ (1,0) [0|1] "" Vector__XXX
 SG_ FltOBCSigReqCrcChkFail : 88|1@0+ (1,0) [0|1] "" Vector__XXX
 SG_ FltOBCSigReqRolCntChkFail : 103|1@0+ (1,0) [0|1] "" Vector__XXX
 SG_ FltOBCSvccOVP : 102|1@0+ (1,0) [0|1] "" Vector__XXX
 SG_ FltOBCSvccUVP : 101|1@0+ (1,0) [0|1] "" Vector__XXX
 SG_ FltOBCV2xCpoutAbnorm : 100|1@0+ (1,0) [0|1] "" Vector__XXX
 SG_ FltOBCV2xHwErrOutpNoResp : 99|1@0+ (1,0) [0|1] "" Vector__XXX
 SG_ FltOBCV2xInpCurAbnorm : 98|1@0+ (1,0) [0|1] "" Vector__XXX
 SG_ FltOBCV2xInpOVP : 97|1@0+ (1,0) [0|1] "" Vector__XXX
 SG_ FltOBCV2xInpUVP : 96|1@0+ (1,0) [0|1] "" Vector__XXX
 SG_ FltOBCV2xOutpCurAbnorm : 111|1@0+ (1,0) [0|1] "" Vector__XXX
 SG_ FltOBCV2xOutpFrqAbnorm : 110|1@0+ (1,0) [0|1] "" Vector__XXX
 SG_ FltOBCV2xOutpIsolnErr : 109|1@0+ (1,0) [0|1] "" Vector__XXX
 SG_ FltOBCV2xOutpOVP : 108|1@0+ (1,0) [0|1] "" Vector__XXX
 SG_ FltOBCV2xOutpShrCirc : 107|1@0+ (1,0) [0|1] "" Vector__XXX
 SG_ FltOBCV2xOutpUVP : 106|1@0+ (1,0) [0|1] "" Vector__XXX
 SG_ FltOBCV2xPfcBusUnderU : 105|1@0+ (1,0) [0|1] "" Vector__XXX
 SG_ FltPfcMosTAbnorm : 104|1@0+ (1,0) [0|1] "" Vector__XXX
 SG_ FltPwrModCrcChkFail : 119|1@0+ (1,0) [0|1] "" Vector__XXX
 SG_ FltPwrModRolCntChkFail : 118|1@0+ (1,0) [0|1] "" Vector__XXX
 SG_ FltS2RespFail : 117|1@0+ (1,0) [0|1] "" Vector__XXX
 SG_ FltVCUActGearCrcChkFail : 116|1@0+ (1,0) [0|1] "" Vector__XXX
 SG_ FltVCUActGearRolCntChkFail : 115|1@0+ (1,0) [0|1] "" Vector__XXX
 SG_ FltWhlStsCrcChkFail : 114|1@0+ (1,0) [0|1] "" Vector__XXX
 SG_ FltWhlStsRolCntChkFail : 113|1@0+ (1,0) [0|1] "" Vector__XXX

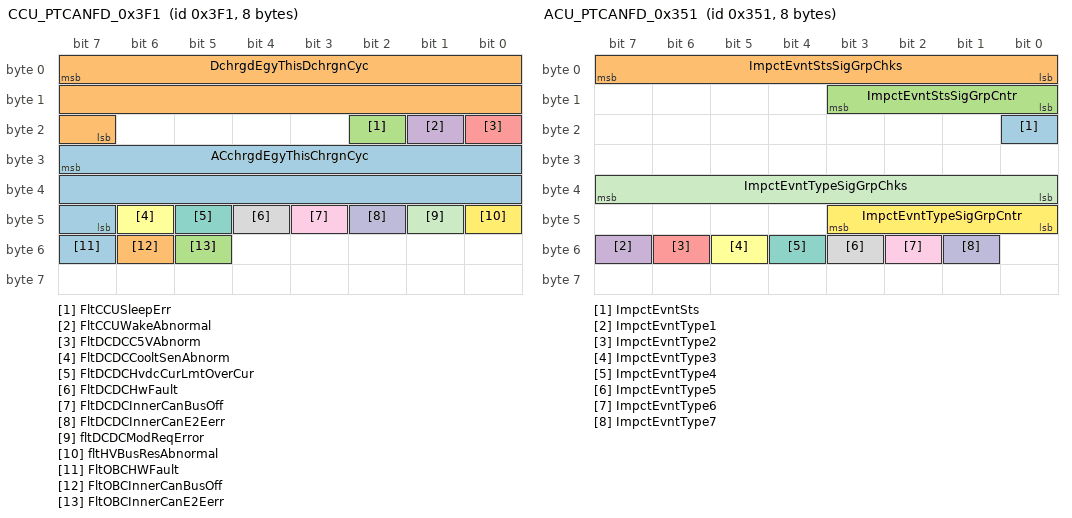
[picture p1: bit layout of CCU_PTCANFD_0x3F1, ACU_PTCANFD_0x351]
BO_ 1009 CCU_PTCANFD_0x3F1 : 8 BMS
 SG_ ACchrgdEgyThisChrgnCyc : 31|17@0+ (1.0,0.0) [0.0|131071.0] "wh" Vector__XXX
 SG_ DchrgdEgyThisDchrgnCyc : 7|17@0+ (1.0,0.0) [0.0|131071.0] "wh" Vector__XXX
 SG_ FltCCUSleepErr : 18|1@0+ (1.0,0.0) [0.0|1.0] "" Vector__XXX
 SG_ FltCCUWakeAbnormal : 17|1@0+ (1.0,0.0) [0.0|1.0] "" Vector__XXX
 SG_ FltDCDCC5VAbnorm : 16|1@0+ (1.0,0.0) [0.0|1.0] "" Vector__XXX
 SG_ FltDCDCCooltSenAbnorm : 46|1@0+ (1.0,0.0) [0.0|1.0] "" Vector__XXX
 SG_ FltDCDCHvdcCurLmtOverCur : 45|1@0+ (1.0,0.0) [0.0|1.0] "" Vector__XXX
 SG_ FltDCDCHwFault : 44|1@0+ (1.0,0.0) [0.0|1.0] "" Vector__XXX
 SG_ FltDCDCInnerCanBusOff : 43|1@0+ (1.0,0.0) [0.0|1.0] "" Vector__XXX
 SG_ FltDCDCInnerCanE2Eerr : 42|1@0+ (1.0,0.0) [0.0|1.0] "" Vector__XXX
 SG_ fltDCDCModReqError : 41|1@0+ (1.0,0.0) [0.0|1.0] "" Vector__XXX
 SG_ fltHVBusResAbnormal : 40|1@0+ (1.0,0.0) [0.0|1.0] "" Vector__XXX
 SG_ FltOBCHWFault : 55|1@0+ (1.0,0.0) [0.0|1.0] "" Vector__XXX
 SG_ FltOBCInnerCanBusOff : 54|1@0+ (1.0,0.0) [0.0|1.0] "" Vector__XXX
 SG_ FltOBCInnerCanE2Eerr : 53|1@0+ (1.0,0.0) [0.0|1.0] "" Vector__XXX

BO_ 849 ACU_PTCANFD_0x351 : 8 Vector__XXX
 SG_ ImpctEvntSts : 16|1@0+ (1,0) [0|1] "" BMS
 SG_ ImpctEvntStsSigGrpChks : 7|8@0+ (1,0) [0|255] "" BMS
 SG_ ImpctEvntStsSigGrpCntr : 11|4@0+ (1,0) [0|15] "" BMS
 SG_ ImpctEvntType1 : 55|1@0+ (1,0) [0|1] "" BMS
 SG_ ImpctEvntType2 : 54|1@0+ (1,0) [0|1] "" BMS
 SG_ ImpctEvntType3 : 53|1@0+ (1,0) [0|1] "" BMS
 SG_ ImpctEvntType4 : 52|1@0+ (1,0) [0|1] "" BMS
 SG_ ImpctEvntType5 : 51|1@0+ (1,0) [0|1] "" BMS
 SG_ ImpctEvntType6 : 50|1@0+ (1,0) [0|1] "" BMS
 SG_ ImpctEvntType7 : 49|1@0+ (1,0) [0|1] "" BMS
 SG_ ImpctEvntTypeSigGrpChks : 39|8@0+ (1.0,0.0) [0.0|255.0] "" BMS
 SG_ ImpctEvntTypeSigGrpCntr : 43|4@0+ (1.0,0.0) [0.0|15.0] "" BMS

BO_ 179 BCS_PTCANFD_0xB3 : 32 Vector__XXX
 SG_ VehSpd : 87|16@0+ (0.05625,0.0) [0.0|360.0] "kph" BMS
 SG_ VehSpdVld : 103|1@0+ (1,0) [0|1] "" BMS
 SG_ WhlDirFrntLe : 101|2@0+ (1,0) [0|3] "" BMS
 SG_ WhlDirFrntLeVld : 102|1@0+ (1,0) [0|1] "" BMS
 SG_ WhlDirFrntRi : 97|2@0+ (1,0) [0|3] "" BMS
 SG_ WhlDirFrntRiVld : 98|1@0+ (1,0) [0|1] "" BMS
 SG_ WhlDirReLe : 117|2@0+ (1,0) [0|3] "" BMS
 SG_ WhlDirReLeVld : 118|1@0+ (1,0) [0|1] "" BMS
 SG_ WhlDirReRi : 113|2@0+ (1,0) [0|3] "" BMS
 SG_ WhlDirReRiVld : 114|1@0+ (1,0) [0|1] "" BMS
 SG_ WhlDstTiStampFrntLe : 159|16@0+ (1.0,0.0) [0.0|65535.0] "ms" BMS
 SG_ WhlDstTiStampFrntRi : 175|16@0+ (1.0,0.0) [0.0|65535.0] "ms" BMS
 SG_ WhlDstTiStampReLe : 191|16@0+ (1.0,0.0) [0.0|65535.0] "ms" BMS
 SG_ WhlDstTiStampReRi : 207|16@0+ (1.0,0.0) [0.0|65535.0] "ms" BMS
 SG_ WhlSpdEdgeFrntLe : 111|8@0+ (1.0,0.0) [0.0|255.0] "" BMS
 SG_ WhlSpdEdgeFrntLeVld : 99|1@0+ (1,0) [0|1] "" BMS
 SG_ WhlSpdEdgeFrntRi : 127|8@0+ (1.0,0.0) [0.0|255.0] "" BMS
 SG_ WhlSpdEdgeFrntRiVld : 119|1@0+ (1,0) [0|1] "" BMS
 SG_ WhlSpdEdgeReLe : 135|8@0+ (1.0,0.0) [0.0|255.0] "" BMS
 SG_ WhlSpdEdgeReLeVld : 115|1@0+ (1,0) [0|1] "" BMS
 SG_ WhlSpdEdgeReRi : 151|8@0+ (1.0,0.0) [0.0|255.0] "" BMS
 SG_ WhlSpdEdgeReRiVld : 143|1@0+ (1,0) [0|1] "" BMS
 SG_ WhlSpdFrntLe : 23|16@0+ (0.05625,0.0) [0.0|360.0] "kph" BMS
 SG_ WhlSpdFrntLeVld : 15|1@0+ (1,0) [0|1] "" BMS
 SG_ WhlSpdFrntRi : 39|16@0+ (0.05625,0.0) [0.0|360.0] "kph" BMS
 SG_ WhlSpdFrntRiVld : 14|1@0+ (1,0) [0|1] "" BMS
 SG_ WhlSpdReLe : 55|16@0+ (0.05625,0.0) [0.0|360.0] "kph" BMS
 SG_ WhlSpdReLeVld : 13|1@0+ (1,0) [0|1] "" BMS
 SG_ WhlSpdReRi : 71|16@0+ (0.05625,0.0) [0.0|360.0] "kph" BMS
 SG_ WhlSpdReRiVld : 12|1@0+ (1,0) [0|1] "" BMS
 SG_ WhlStsSigGrpChks : 7|8@0+ (1,0) [0|255] "" BMS
 SG_ WhlStsSigGrpCntr : 11|4@0+ (1,0) [0|15] "" BMS

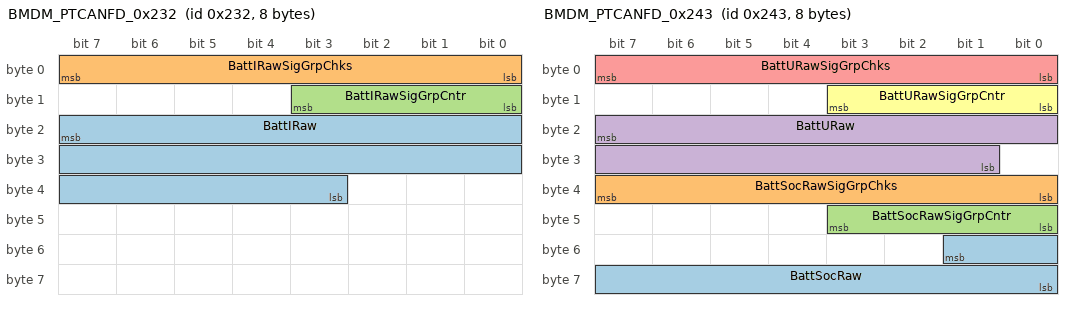
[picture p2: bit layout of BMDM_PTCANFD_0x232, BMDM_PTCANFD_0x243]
BO_ 562 BMDM_PTCANFD_0x232 : 8 Vector__XXX
 SG_ BattIRaw : 23|21@0+ (0.001,-1000.0) [-1000.0|520.0] "A" BMS
 SG_ BattIRawSigGrpChks : 7|8@0+ (1,0) [0|255] "" BMS
 SG_ BattIRawSigGrpCntr : 11|4@0+ (1,0) [0|15] "" BMS

BO_ 579 BMDM_PTCANFD_0x243 : 8 Vector__XXX
 SG_ BattSocRaw : 49|10@0+ (0.1,0.0) [0.0|102.30000000000001] "%" BMS
 SG_ BattSocRawSigGrpChks : 39|8@0+ (1.0,0.0) [0.0|255.0] "" BMS
 SG_ BattSocRawSigGrpCntr : 43|4@0+ (1.0,0.0) [0.0|15.0] "" BMS
 SG_ BattURaw : 23|15@0+ (0.001,0.0) [0.0|18.0] "V" BMS
 SG_ BattURawSigGrpChks : 7|8@0+ (1,0) [0|255] "" BMS
 SG_ BattURawSigGrpCntr : 11|4@0+ (1,0) [0|15] "" BMS

BO_ 464 FEDS_PTCANFD_0x1D0 : 8 Vector__XXX
 SG_ FrntMotIndHeatgActPwr : 7|8@0+ (50.0,0.0) [0.0|12750.0] "W" BMS

BO_ 641 FEDS_PTCANFD_0x281 : 24 Vector__XXX
 SG_ FrntMotIndHeatgSts : 8|1@0+ (1,0) [0|1] "" BMS

BO_ 115 FEDS_PTCANFD_0x73 : 32 Vector__XXX
 SG_ FrntMotActCurBkp : 103|14@0+ (0.1,-819.1) [-819.1|819.2000000000002] "A" BMS

BO_ 287 FZCU_PTCANFD_0x11F : 32 Vector__XXX
 SG_ VCUBoosterCntctReq : 95|1@0+ (1,0) [0|1] "" BMS
 SG_ VCUBoosterCntctReqSigGrpChks : 79|8@0+ (1,0) [0|255] "" BMS
 SG_ VCUBoosterCntctReqSigGrpCntr : 83|4@0+ (1,0) [0|15] "" BMS
 SG_ VCUBoosterOutpCntctReq : 111|1@0+ (1,0) [0|1] "" BMS
 SG_ VCUStrtSecForLoSoc : 110|1@0+ (1,0) [0|1] "" BMS

BO_ 304 FZCU_PTCANFD_0x130 : 32 Vector__XXX
 SG_ VCUChrgnPauseReq : 2|2@0+ (1,0) [0|3] "" BMS
 SG_ VCUChrgnPauseReqFV : 215|16@0+ (1.0,0.0) [0.0|65535.0] "" BMS
 SG_ VCUChrgnPauseReqMAC : 231|32@0+ (1.0,0.0) [0.0|4294967295.0] "" BMS
 SG_ VCUDischrgnProcFlg : 3|1@0+ (1,0) [0|1] "" BMS

BO_ 325 FZCU_PTCANFD_0x145 : 64 Vector__XXX
 SG_ VCUVSR11 : 7|32@0+ (1.0,0.0) [0.0|16777215.0] "" BMS
 SG_ VCUVSR12 : 39|32@0+ (1.0,0.0) [0.0|16777215.0] "" BMS
 SG_ VCUVSR13 : 71|32@0+ (1.0,0.0) [0.0|16777215.0] "" BMS
 SG_ VCUVSR14 : 103|32@0+ (1.0,0.0) [0.0|16777215.0] "" BMS
 SG_ VCUVSR15 : 135|32@0+ (1.0,0.0) [0.0|16777215.0] "" BMS
 SG_ VCUVSR16 : 167|32@0+ (1.0,0.0) [0.0|16777215.0] "" BMS
 SG_ VCUVSR17 : 199|32@0+ (1.0,0.0) [0.0|16777215.0] "" BMS
 SG_ VCUVSR18 : 231|32@0+ (1.0,0.0) [0.0|16777215.0] "" BMS
 SG_ VCUVSR19 : 263|32@0+ (1.0,0.0) [0.0|16777215.0] "" BMS

BO_ 327 FZCU_PTCANFD_0x147 : 64 Vector__XXX
 SG_ VCUVSR21 : 7|32@0+ (1.0,0.0) [0.0|16777215.0] "" BMS
 SG_ VCUVSR22 : 39|32@0+ (1.0,0.0) [0.0|16777215.0] "" BMS
 SG_ VCUVSR23 : 71|32@0+ (1.0,0.0) [0.0|16777215.0] "" BMS
 SG_ VCUVSR24 : 103|32@0+ (1.0,0.0) [0.0|16777215.0] "" BMS
 SG_ VCUVSR25 : 135|32@0+ (1.0,0.0) [0.0|16777215.0] "" BMS
 SG_ VCUVSR26 : 167|32@0+ (1.0,0.0) [0.0|16777215.0] "" BMS
 SG_ VCUVSR27 : 199|32@0+ (1.0,0.0) [0.0|16777215.0] "" BMS
 SG_ VCUVSR28 : 231|32@0+ (1.0,0.0) [0.0|16777215.0] "" BMS
 SG_ VCUVSR29 : 263|32@0+ (1.0,0.0) [0.0|16777215.0] "" BMS

BO_ 448 FZCU_PTCANFD_0x1C0 : 32 Vector__XXX
 SG_ AmbTEstimd : 111|16@0+ (0.01,-80.0) [-80.0|175.0] "degC" BMS
 SG_ AmbTEstimdVld : 127|1@0+ (1,0) [0|1] "" BMS
 SG_ CooltTankLvlLo : 126|1@0+ (1,0) [0|1] "" BMS
 SG_ CooltTankLvlLoVld : 125|1@0+ (1,0) [0|1] "" BMS
 SG_ FrntIncarTEstimd : 135|16@0+ (0.01,-80.0) [-80.0|175.0] "degC" BMS
 SG_ FrntIncarTEstimdVld : 124|1@0+ (1,0) [0|1] "" BMS
 SG_ HvBattCoolgMaxPwrCp : 25|10@0+ (20.0,0.0) [0.0|20460.0] "W" BMS
 SG_ HvBattCooltCircFlowEstimd : 185|10@0+ (0.05,0.0) [0.0|51.150000000000006] "L/min" BMS
 SG_ HvBattHeatgMaxPwrCp : 247|10@0+ (20.0,0.0) [0.0|20460.0] "W" BMS
 SG_ HvBattInletCooltT : 151|16@0+ (0.01,-80.0) [-80.0|175.0] "degC" BMS
 SG_ HvBattOutletCooltT : 167|16@0+ (0.01,-80.0) [-80.0|175.0] "degC" BMS
 SG_ HvBattThermPwrCns : 41|10@0+ (20.0,0.0) [0.0|20460.0] "W" BMS
 SG_ HvBattThermReqFb : 189|4@0+ (1,0) [0|15] "" BMS
 SG_ VCUHvBattbkdHeatgEna : 42|1@0+ (1,0) [0|1] "" BMS

BO_ 560 FZCU_PTCANFD_0x230 : 16 Vector__XXX
 SG_ VCUAuxChrgnModSts : 39|2@0+ (1,0) [0|3] "" BMS
 SG_ VCUCalcdActAuxPwr : 23|11@0+ (20.0,0.0) [0.0|40940.0] "W" BMS
 SG_ VCUCalcdActAuxPwrSigGrpChks : 7|8@0+ (1,0) [0|255] "" BMS
 SG_ VCUCalcdActAuxPwrSigGrpCntr : 11|4@0+ (1,0) [0|15] "" BMS

BO_ 631 FZCU_PTCANFD_0x277 : 64 Vector__XXX
 SG_ CCUCooltCircFlowEstimd : 55|10@0+ (0.05,0.0) [0.0|51.150000000000006] "L/min" BMS
 SG_ CmprPwrCnsAct : 111|16@0+ (1.0,0.0) [0.0|65535.0] "W" BMS
 SG_ CmprSt : 127|8@0+ (1,0) [0|255] "" BMS
 SG_ HvchPwrCns : 135|16@0+ (1.0,0.0) [0.0|65535.0] "W" BMS
 SG_ HvchSt : 151|8@0+ (1,0) [0|255] "" BMS
 SG_ VCUbkHeatEgySrcEna : 98|2@0+ (1,0) [0|3] "" BMS
 SG_ VCUChrgnScenSts : 61|4@0+ (1.0,0.0) [0.0|15.0] "" BMS
 SG_ VCUCrsRngForAkm : 71|11@0+ (1.0,0.0) [0.0|2047.0] "" BMS
 SG_ VCUHVExtPortConnectnTypInfo : 103|4@0+ (1,0) [0|15] "" BMS
 SG_ VCUOBCChrgnCurReq : 23|10@0+ (0.1,0.0) [0.0|102.2] "A" BMS
 SG_ VCUOBCChrgnReqSigGrpChks : 7|8@0+ (1,0) [0|255] "" BMS
 SG_ VCUOBCChrgnReqSigGrpCntr : 11|4@0+ (1,0) [0|15] "" BMS
 SG_ VCUOBCChrgnUReq : 39|14@0+ (0.1,0.0) [0.0|1638.3000000000002] "V" BMS

BO_ 644 FZCU_PTCANFD_0x284 : 64 Vector__XXX
 SG_ AmbTRaw : 367|16@0+ (0.01,-80.0) [-80.0|175.0] "degC" BMS
 SG_ AmbTRawVld : 268|1@0+ (1,0) [0|1] "" BMS
 SG_ VCUDCChrgnAdapSet : 490|1@0+ (1,0) [0|1] "" BMS

BO_ 739 FZCU_PTCANFD_0x2E3 : 32 Vector__XXX
 SG_ CooltTankLvlSnsrU : 31|16@0+ (0.1,0.0) [0.0|5000.0] "mV" BMS
 SG_ TmHvDirHeatReq : 178|1@0+ (1.0,0.0) [0.0|1.0] "" BMS
 SG_ VCUChrgnModSts : 47|4@0+ (1,0) [0|15] "" BMS
 SG_ VCUTrigChrgnRecordEvent : 18|1@0+ (1,0) [0|1] "" BMS

BO_ 841 FZCU_PTCANFD_0x349 : 16 Vector__XXX
 SG_ CanHvchActvDchaReq : 67|1@0+ (1,0) [0|1] "" BMS
 SG_ CanHvchEna : 23|1@0+ (1,0) [0|1] "" BMS
 SG_ CanHvchEnaSigGrpChks : 7|8@0+ (1,0) [0|255] "" BMS
 SG_ CanHvchEnaSigGrpCntr : 11|4@0+ (1,0) [0|15] "" BMS
 SG_ CanHvchPwrAllwd : 79|8@0+ (100.0,0.0) [0.0|25500.0] "W" BMS
 SG_ CanHvchSysMod : 43|2@0+ (1,0) [0|3] "" BMS

BO_ 883 FZCU_PTCANFD_0x373 : 64 Vector__XXX
 SG_ CmprHvCur : 41|10@0+ (0.05,0.0) [0.0|51.150000000000006] "A" BMS

BO_ 884 FZCU_PTCANFD_0x374 : 48 Vector__XXX
 SG_ HvchHvCur : 31|8@0+ (0.25,0.0) [0.0|63.75] "A" BMS
 SG_ HvchSts : 2|3@0+ (1,0) [0|7] "" BMS

BO_ 896 FZCU_PTCANFD_0x380 : 48 Vector__XXX
 SG_ VCUBookChrgnSts : 14|3@0+ (1,0) [0|7] "" BMS
 SG_ VCUBookChrgnStsSigGrpChks : 7|8@0+ (1,0) [0|255] "" BMS
 SG_ VCUBookChrgnStsSigGrpCntr : 11|4@0+ (1,0) [0|15] "" BMS

BO_ 144 FZCU_PTCANFD_0x90 : 24 Vector__XXX
 SG_ CarModSts : 126|3@0+ (1,0) [0|7] "" BMS
 SG_ PwrModSigGrpChks : 7|8@0+ (1,0) [0|255] "" BMS
 SG_ PwrModSigGrpCntr : 11|4@0+ (1,0) [0|15] "" BMS
 SG_ PwrModSts : 23|3@0+ (1,0) [0|7] "" BMS
 SG_ PwrModVld : 20|1@0+ (1,0) [0|1] "" BMS
 SG_ VCUAccrPedlRat : 87|15@0+ (0.004,0.0) [0.0|100.0] "pct" BMS
 SG_ VCUAccrPedlRatVld : 111|1@0+ (1,0) [0|1] "" BMS
 SG_ VCUActDrvMod : 123|4@0+ (1,0) [0|15] "" BMS
 SG_ VCUActGearLvr : 55|3@0+ (1,0) [0|7] "" BMS
 SG_ VCUActGearLvrVld : 52|1@0+ (1,0) [0|1] "" BMS
 SG_ VCUActGearSigGrpChks : 47|8@0+ (1,0) [0|255] "" BMS
 SG_ VCUActGearSigGrpCntr : 51|4@0+ (1,0) [0|15] "" BMS
 SG_ VCUDrvOffFcnLim : 119|1@0+ (1,0) [0|1] "" BMS
 SG_ VCUFrntEmTqRdy : 110|1@0+ (1,0) [0|1] "" BMS
 SG_ VCUGearLvrAvail : 118|1@0+ (1,0) [0|1] "" BMS
 SG_ VcuInpSigGrpChks : 63|8@0+ (1,0) [0|255] "" BMS
 SG_ VcuInpSigGrpCntr : 67|4@0+ (1,0) [0|15] "" BMS
 SG_ VCUPrkgBtnPsd : 88|1@0+ (1,0) [0|1] "" BMS
 SG_ VCUPtRdyFlg : 127|1@0+ (1,0) [0|1] "" BMS
 SG_ VCUReEmTqRdy : 109|1@0+ (1,0) [0|1] "" BMS
 SG_ VCURgnTqCorrnFac : 71|4@0+ (0.1,0.0) [0.0|1.0] "" BMS
 SG_ VCUShifterMoveFlg : 104|1@0+ (1.0,0.0) [0.0|1.0] "" BMS
 SG_ VCUStsModCst : 79|8@0+ (1,0) [0|255] "" BMS
 SG_ VCUTarGearLvr : 108|3@0+ (1,0) [0|7] "" BMS
 SG_ VCUTarGearLvrVld : 96|1@0+ (1,0) [0|1] "" BMS
 SG_ VCUVirtAccrPedl : 103|7@0+ (1.0,0.0) [0.0|100.0] "%" BMS
 SG_ VCUVirtAccrPedlVld : 105|1@0+ (1,0) [0|1] "" BMS

BO_ 151 FZCU_PTCANFD_0x97 : 48 Vector__XXX
 SG_ VCUChrgnModReqToHvBatt : 351|3@0+ (1,0) [0|7] "" BMS
 SG_ VCUDCDCHVCurLim : 280|9@0+ (0.1,0.0) [0.0|51.1] "A" BMS
 SG_ VCUDCDCLVCurLim : 303|11@0+ (0.5,0.0) [0.0|1023.0] "A" BMS
 SG_ VCUDCDCModReq : 308|3@0+ (1,0) [0|7] "" BMS
 SG_ VCUDCDCReqSigGrpChks : 263|8@0+ (1,0) [0|255] "" BMS
 SG_ VCUDCDCReqSigGrpCntr : 267|4@0+ (1,0) [0|15] "" BMS
 SG_ VCUDCDCUHVSp : 247|10@0+ (1.0,0.0) [0.0|1023.0] "V" BMS
 SG_ VCUDCDCULVSp : 279|14@0+ (0.001,0.0) [0.0|16.383] "V" BMS
 SG_ VCUHvOffKeyReq : 356|1@0+ (1,0) [0|1] "" BMS
 SG_ VCUModReqToHvBatt : 359|3@0+ (1,0) [0|7] "" BMS
 SG_ VCUOBCELockReq : 335|2@0+ (1,0) [0|3] "" BMS
 SG_ VCUOBCModReq : 327|3@0+ (1,0) [0|7] "" BMS
 SG_ VCUOBCReqSigGrpChks : 319|8@0+ (1,0) [0|255] "" BMS
 SG_ VCUOBCReqSigGrpCntr : 323|4@0+ (1,0) [0|15] "" BMS
 SG_ VCUOBCS2Req : 324|1@0+ (1,0) [0|1] "" BMS
 SG_ VCUReqToHvBattSigGrpChks : 343|8@0+ (1,0) [0|255] "" BMS
 SG_ VCUReqToHvBattSigGrpCntr : 347|4@0+ (1,0) [0|15] "" BMS

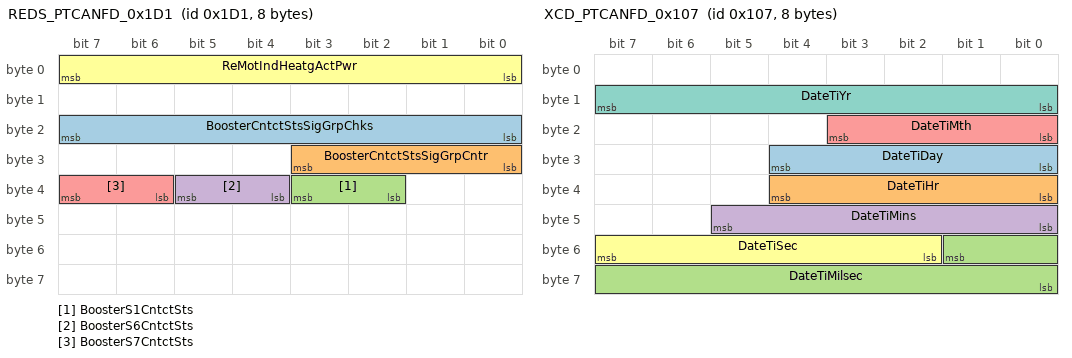
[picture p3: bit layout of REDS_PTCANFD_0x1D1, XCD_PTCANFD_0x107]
BO_ 465 REDS_PTCANFD_0x1D1 : 8 Vector__XXX
 SG_ BoosterCntctStsSigGrpChks : 23|8@0+ (1.0,0.0) [0.0|255.0] "" BMS
 SG_ BoosterCntctStsSigGrpCntr : 27|4@0+ (1.0,0.0) [0.0|15.0] "" BMS
 SG_ BoosterS1CntctSts : 35|2@0+ (1,0) [0|3] "" BMS
 SG_ BoosterS6CntctSts : 37|2@0+ (1,0) [0|3] "" BMS
 SG_ BoosterS7CntctSts : 39|2@0+ (1,0) [0|3] "" BMS
 SG_ ReMotIndHeatgActPwr : 7|8@0+ (50.0,0.0) [0.0|12750.0] "W" BMS

BO_ 643 REDS_PTCANFD_0x283 : 48 Vector__XXX
 SG_ BoostChrgnOutpCur : 143|14@0+ (0.1,0.0) [0.0|1000.0] "A" BMS
 SG_ BoostChrgnOutpSigGrpChks : 127|8@0+ (1.0,0.0) [0.0|255.0] "" BMS
 SG_ BoostChrgnOutpSigGrpCntr : 131|4@0+ (1.0,0.0) [0.0|15.0] "" BMS
 SG_ BoostChrgnOutpU : 159|14@0+ (0.1,0.0) [0.0|1000.0] "V" BMS
 SG_ BoosterS1CntctFlt : 71|2@0+ (1,0) [0|3] "" BMS
 SG_ ReMotIndHeatgSts : 62|1@0+ (1,0) [0|1] "" BMS

BO_ 166 REDS_PTCANFD_0xA6 : 48 Vector__XXX
 SG_ BoostChrgnInpCur : 119|14@0+ (0.1,0.0) [0.0|1000.0] "A" BMS
 SG_ BoostChrgnInpSigGrpChks : 103|8@0+ (1.0,0.0) [0.0|255.0] "" BMS
 SG_ BoostChrgnInpSigGrpCntr : 107|4@0+ (1.0,0.0) [0.0|15.0] "" BMS
 SG_ BoostChrgnInpU : 135|14@0+ (0.1,0.0) [0.0|1638.3000000000002] "V" BMS
 SG_ BoostChrgnOutpPwrMax : 151|11@0+ (0.1,0.0) [0.0|204.60000000000002] "KW" BMS
 SG_ ReMotActCurBkp : 7|14@0+ (0.1,-819.1) [-819.1|819.2000000000002] "A" BMS
 SG_ ReMotModStsBkp : 223|5@0+ (1,0) [0|31] "" BMS
 SG_ ReMotModStsBkpChks : 207|8@0+ (1.0,0.0) [0.0|255.0] "" BMS
 SG_ ReMotModStsBkpCntr : 211|4@0+ (1.0,0.0) [0.0|15.0] "" BMS

BO_ 182 SCU_PTCANFD_0xB6 : 32 Vector__XXX
 SG_ AccrSnsrAzFrntLe : 87|10@0+ (0.01,-1.6) [-1.6|1.6] "" BMS
 SG_ AccrSnsrAzFrntRi : 103|10@0+ (0.01,-1.6) [-1.6|1.6] "" BMS
 SG_ AccrSnsrAzRe : 119|10@0+ (0.01,-1.6) [-1.6|1.6] "" BMS
 SG_ SCUAccrSnsrChks : 71|8@0+ (1,0) [0|255] "" BMS
 SG_ SCUAccrSnsrCntr : 75|4@0+ (1,0) [0|15] "" BMS

BO_ 846 TMHIM_PTCANFD_0x34E : 32 Vector__XXX
 SG_ CanCmprHvCur : 31|10@0+ (0.05,0.0) [0.0|51.150000000000006] "A" BMS
 SG_ CanHvchHvCur : 161|10@0+ (0.05,0.0) [0.0|51.150000000000006] "A" BMS
 SG_ CanHvchPeakCur : 151|8@0+ (0.25,0.0) [0.0|63.75] "A" BMS
 SG_ CanHvchSts : 167|3@0+ (1,0) [0|7] "" BMS

BO_ 263 XCD_PTCANFD_0x107 : 8 Vector__XXX
 SG_ DateTiDay : 28|5@0+ (1,0) [0|31] "" BMS
 SG_ DateTiHr : 36|5@0+ (1.0,0.0) [0.0|24.0] "hour" BMS
 SG_ DateTiMilsec : 49|10@0+ (1.0,0.0) [0.0|1000.0] "Msec" BMS
 SG_ DateTiMins : 45|6@0+ (1.0,0.0) [0.0|59.0] "minute" BMS
 SG_ DateTiMth : 19|4@0+ (1.0,0.0) [0.0|12.0] "" BMS
 SG_ DateTiSec : 55|6@0+ (1.0,0.0) [0.0|59.0] "second" BMS
 SG_ DateTiYr : 15|8@0+ (1.0,2000.0) [2000.0|2254.0] "year" BMS

BO_ 529 XCD_PTCANFD_0x211 : 16 Vector__XXX
 SG_ SecOCMAC1 : 47|32@0+ (1.0,0.0) [0.0|4294967295.0] "" BMS
 SG_ SecOCMAC2 : 79|32@0+ (1.0,0.0) [0.0|4294967295.0] "" BMS
 SG_ SecOCMAC3 : 111|24@0+ (1.0,0.0) [0.0|16777215.0] "" BMS
 SG_ SecOCResetCnt : 31|16@0+ (1.0,0.0) [0.0|65535.0] "" BMS
 SG_ SecOCTripCnt : 7|24@0+ (1.0,0.0) [0.0|16777215.0] "" BMS

BO_ 624 XCD_PTCANFD_0x270 : 32 Vector__XXX
 SG_ DcChrgnCmptFlg : 33|1@0+ (1,0) [0|1] "" BMS
 SG_ DCDsentryModSts : 122|3@0+ (1,0) [0|7] "" BMS
 SG_ HvBattAlgCooltFlowReq : 95|8@0+ (0.2,0.0) [0.0|51.0] "L/min" BMS
 SG_ HvBattAlgCooltTReq : 103|8@0+ (1.0,-40.0) [-40.0|215.0] "degC" BMS
 SG_ HvBattAlgThermReqSts : 111|8@0+ (1.0,0.0) [0.0|255.0] "" BMS
 SG_ HvBattPheatgForChrgnEnb : 112|1@0+ (1.0,0.0) [0.0|1.0] "" BMS
 SG_ VCCDHvBattChrgnCurrVld : 32|1@0+ (1,0) [0|1] "" BMS
 SG_ VCCDHvBattCurMaxLimChrgn : 7|14@0+ (0.1,0.0) [0.0|1638.3000000000002] "A" BMS
 SG_ VCCDHvBattDchaEndSoC : 9|10@0+ (0.1,0.0) [0.0|100.0] "pct" BMS
 SG_ VCCDHvBattMaxPulseTiChrgCurr : 31|11@0+ (1.0,0.0) [0.0|2047.0] "A" BMS
 SG_ VCCDHvBattMaxPulseTiDChaCurr : 58|11@0+ (1.0,0.0) [0.0|2047.0] "A" BMS
 SG_ VCCDHvBattModelVld : 36|1@0+ (1,0) [0|1] "" BMS
 SG_ VCCDHvBattPulseTiCurrVld : 35|1@0+ (1,0) [0|1] "" BMS
 SG_ VCCDHvBattSoCAct : 55|11@0+ (0.05,0.0) [0.0|100.0] "pct" BMS
 SG_ VCCDHvBattSOCRSMS : 247|11@0+ (0.05,0.0) [0.0|100.0] "pct" BMS
 SG_ VCCDHvBattSOCRSMSCode : 231|8@0+ (1.0,0.0) [1.0|255.0] "" BMS
 SG_ VCCDHvBattSOCVldRSMS : 239|1@0+ (1,0) [0|1] "" BMS
 SG_ VCUACChrgnCurMaxSetFb : 238|7@0+ (1.0,0.0) [0.0|100.0] "A" BMS
 SG_ VCUBookchrgnStopHourSts : 127|5@0+ (1.0,0.0) [0.0|23.0] "h" BMS
 SG_ VCUBookchrgnStoptMinSts : 135|6@0+ (1.0,0.0) [0.0|59.0] "min" BMS
 SG_ VCUBookchrgnStrtHourSts : 143|5@0+ (1.0,0.0) [0.0|23.0] "h" BMS
 SG_ VCUBookchrgnStrtMinSts : 151|6@0+ (1.0,0.0) [0.0|59.0] "min" BMS
 SG_ VCUBookDefdTiChrgnSts : 145|2@0+ (1,0) [0|3] "" BMS
 SG_ VCUBookDepartrHeatgSts : 153|2@0+ (1,0) [0|3] "" BMS
 SG_ VCUBookDepartrHourSts : 252|5@0+ (1.0,0.0) [0.0|23.0] "h" BMS
 SG_ VCUBookDepartrMinSts : 223|6@0+ (1.0,0.0) [0.0|59.0] "min" BMS
 SG_ VCUBookDepartrRepTypSts : 197|3@0+ (1,0) [0|7] "" BMS
 SG_ VCUBookPassHeatgEna : 34|1@0+ (1,0) [0|1] "" BMS
 SG_ VCUChrgnSoCLimSp : 207|7@0+ (1.0,0.0) [0.0|100.0] "%" BMS
 SG_ VCUDchrgnSoCLimSp : 215|7@0+ (1.0,0.0) [0.0|100.0] "%" BMS
 SG_ VCUPwrForbkTiPred : 79|15@0+ (1.0,0.0) [0.0|32767.0] "W" BMS
 SG_ VCUSOCToChrgnStat : 175|7@0+ (1.0,0.0) [0.0|101.0] "%" BMS
 SG_ VCUThermalStorageReq : 129|2@0+ (1.0,0.0) [0.0|3.0] "" BMS
 SG_ VCUTiToChrgnStat : 183|12@0+ (1.0,0.0) [0.0|4095.0] "min" BMS
 SG_ XCDFBSplyFlg : 80|1@0+ (1.0,0.0) [0.0|1.0] "" BMS

BO_ 722 XCD_PTCANFD_0x2D2 : 16 Vector__XXX
 SG_ SentrymodeLVPwrCtrlSts : 8|1@0+ (1.0,0.0) [0.0|1.0] "" BMS
 SG_ SetMgrVCUActDrvMod : 23|4@0+ (1,0) [0|15] "" BMS

BO_ 914 XCD_PTCANFD_0x392 : 8 Vector__XXX
 SG_ TotOdoAcrt : 7|24@0+ (0.1,0.0) [0.0|1677721.5] "km" BMS

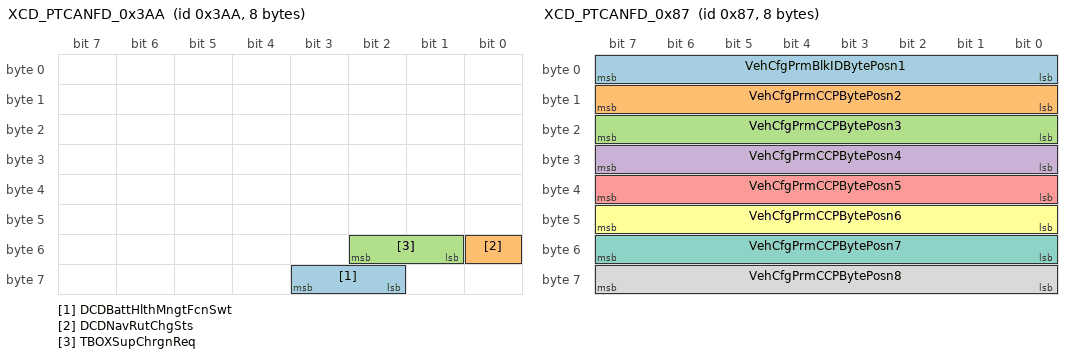
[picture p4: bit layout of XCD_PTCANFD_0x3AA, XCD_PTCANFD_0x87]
BO_ 938 XCD_PTCANFD_0x3AA : 8 Vector__XXX
 SG_ DCDBattHlthMngtFcnSwt : 59|2@0+ (1,0) [0|3] "" BMS
 SG_ DCDNavRutChgSts : 48|1@0+ (1,0) [0|1] "" BMS
 SG_ TBOXSupChrgnReq : 50|2@0+ (1,0) [0|3] "" BMS

BO_ 993 XCD_PTCANFD_0x3E1 : 32 Vector__XXX
 SG_ HvBattAlgRemaChrgnTiFcn1 : 7|16@0+ (1.0,0.0) [0.0|65535.0] "" BMS
 SG_ HvBattAlgRemaChrgnTiFcn2 : 23|16@0+ (1.0,0.0) [0.0|65535.0] "" BMS
 SG_ HvBattAlgRemaChrgnTiFcn3 : 39|16@0+ (1.0,0.0) [0.0|65535.0] "" BMS
 SG_ HvBattAlgRemaChrgnTiFcn4 : 55|16@0+ (1.0,0.0) [0.0|65535.0] "" BMS
 SG_ HvBattAlgRemaChrgnTiFcn5 : 71|16@0+ (1.0,0.0) [0.0|65535.0] "" BMS
 SG_ HvBattAlgRemaChrgnTiFcn6 : 87|16@0+ (1.0,0.0) [0.0|65535.0] "" BMS
 SG_ HvBattAlgRemaChrgnTiFcn7 : 103|16@0+ (1.0,0.0) [0.0|65535.0] "" BMS
 SG_ HvBattAlgRemaChrgnTiFcn8 : 119|16@0+ (1.0,0.0) [0.0|65535.0] "" BMS
 SG_ HvBattAlgRutPheatgFcn1 : 135|16@0+ (1.0,0.0) [0.0|65535.0] "" BMS
 SG_ HvBattAlgRutPheatgFcn2 : 151|16@0+ (1.0,0.0) [0.0|65535.0] "" BMS
 SG_ HvBattAlgRutPheatgFcn3 : 167|16@0+ (1.0,0.0) [0.0|65535.0] "" BMS
 SG_ HvBattAlgRutPheatgFcn4 : 183|16@0+ (1.0,0.0) [0.0|65535.0] "" BMS
 SG_ HvBattAlgRutPheatgFcn5 : 199|16@0+ (1.0,0.0) [0.0|65535.0] "" BMS
 SG_ HvBattAlgRutPheatgFcn6 : 215|16@0+ (1.0,0.0) [0.0|65535.0] "" BMS
 SG_ HvBattAlgRutPheatgFcn7 : 231|16@0+ (1.0,0.0) [0.0|65535.0] "" BMS
 SG_ HvBattAlgRutPheatgFcn8 : 247|16@0+ (1.0,0.0) [0.0|65535.0] "" BMS

BO_ 1008 XCD_PTCANFD_0x3F0 : 24 Vector__XXX
 SG_ HigtAmbTAfTomwSoa : 87|8@0+ (1.0,-80.0) [-80.0|99.0] "°C" BMS
 SG_ HigtAmbTAfTomwValSoa : 111|1@0+ (1,0) [0|1] "" BMS
 SG_ HigtAmbTTomwSoa : 95|8@0+ (1.0,-80.0) [-80.0|99.0] "°C" BMS
 SG_ HigtAmbTTomwValSoa : 110|1@0+ (1,0) [0|1] "" BMS
 SG_ HvBattPheatgForChrgnTarT : 21|6@0+ (1.0,0.0) [0.0|63.0] "°C" BMS
 SG_ LowtAmbTAfTomwSoa : 103|8@0+ (1.0,-80.0) [-80.0|99.0] "°C" BMS
 SG_ LowtAmbTAfTomwValSoa : 109|1@0+ (1,0) [0|1] "" BMS
 SG_ VCCDHvBattCapRSMS : 7|8@0+ (0.5,0.0) [0.0|100.0] "pct" BMS
 SG_ VCCDHvBattCapVldRSMS : 55|1@0+ (1,0) [0|1] "" BMS
 SG_ VCCDHvBattDchaEndTempRSMS : 71|9@0+ (0.5,-40.0) [-40.0|215.5] "℃" BMS
 SG_ VCCDHvBattNextPeriodTempRSMS : 15|9@0+ (0.5,-40.0) [-40.0|215.5] "℃" BMS
 SG_ VCCDHvBattResRSMS : 31|16@0+ (0.01,0.0) [0.0|655.35] "mΩ" BMS
 SG_ VCCDHvBattResVldRSMS : 22|1@0+ (1,0) [0|1] "" BMS
 SG_ VCCDHvBattSOHRSMSCode : 63|8@0+ (1.0,0.0) [1.0|255.0] "" BMS
 SG_ VCCDHvBattTempRSMSCode : 47|8@0+ (1.0,0.0) [1.0|255.0] "" BMS
 SG_ VCCDHvBattTempVldRSMS : 54|1@0+ (1,0) [0|1] "" BMS

BO_ 135 XCD_PTCANFD_0x87 : 8 Vector__XXX
 SG_ VehCfgPrmBlkIDBytePosn1 : 7|8@0+ (1.0,0.0) [0.0|150.0] "" BMS
 SG_ VehCfgPrmCCPBytePosn2 : 15|8@0+ (1.0,0.0) [0.0|255.0] "" BMS
 SG_ VehCfgPrmCCPBytePosn3 : 23|8@0+ (1.0,0.0) [0.0|255.0] "" BMS
 SG_ VehCfgPrmCCPBytePosn4 : 31|8@0+ (1.0,0.0) [0.0|255.0] "" BMS
 SG_ VehCfgPrmCCPBytePosn5 : 39|8@0+ (1.0,0.0) [0.0|255.0] "" BMS
 SG_ VehCfgPrmCCPBytePosn6 : 47|8@0+ (1.0,0.0) [0.0|255.0] "" BMS
 SG_ VehCfgPrmCCPBytePosn7 : 55|8@0+ (1.0,0.0) [0.0|255.0] "" BMS
 SG_ VehCfgPrmCCPBytePosn8 : 63|8@0+ (1.0,0.0) [0.0|255.0] "" BMS

BO_ 664 XCD_PTCANFD_RT_0x298 : 16 Vector__XXX
 SG_ BattSoh : 63|10@0+ (0.1,0.0) [0.0|102.30000000000001] "%" BMS
 SG_ BattSohSigGrpChks : 47|8@0+ (1.0,0.0) [0.0|255.0] "" BMS
 SG_ BattSohSigGrpCntr : 51|4@0+ (1.0,0.0) [0.0|15.0] "" BMS
 SG_ BattTRaw : 31|9@0+ (0.5,-128.0) [-128.0|127.5] "degC" BMS
 SG_ BattTRawSigGrpChks : 15|8@0+ (1,0) [0|255] "" BMS
 SG_ BattTRawSigGrpCntr : 19|4@0+ (1,0) [0|15] "" BMS
 SG_ IVFWModSts : 5|2@0+ (1,0) [0|3] "" BMS
 SG_ LockgCenLockSts : 7|2@0+ (1,0) [0|3] "" BMS

BO_ 1296 XCDPtCanfdNMFr : 8 Vector__XXX
 SG_ NMKeepAwkRsnVCCD : 48|9@0+ (1.0,0.0) [0.0|511.0] "" BMS
 SG_ PNC55XCD : 55|1@0+ (1,0) [0|1] "" BMS
 SG_ UDB17VCCD : 17|1@0+ (1.0,0.0) [0.0|1.0] "" BMS
 SG_ UDB18VCCD : 18|1@0+ (1.0,0.0) [0.0|1.0] "" BMS
 SG_ UDB19VCCD : 19|1@0+ (1.0,0.0) [0.0|1.0] "" BMS
 SG_ UDB20VCCD : 20|1@0+ (1.0,0.0) [0.0|1.0] "" BMS
 SG_ UDB21VCCD : 21|1@0+ (1.0,0.0) [0.0|1.0] "" BMS
 SG_ UDB22VCCD : 22|1@0+ (1.0,0.0) [0.0|1.0] "" BMS
 SG_ UDB23VCCD : 23|1@0+ (1.0,0.0) [0.0|1.0] "" BMS
 SG_ UDB24VCCD : 24|1@0+ (1.0,0.0) [0.0|1.0] "" BMS
 SG_ UDB25VCCD : 25|1@0+ (1.0,0.0) [0.0|1.0] "" BMS
 SG_ UDB26VCCD : 26|1@0+ (1.0,0.0) [0.0|1.0] "" BMS
 SG_ UDB27VCCD : 27|1@0+ (1.0,0.0) [0.0|1.0] "" BMS
 SG_ UDB28VCCD : 28|1@0+ (1.0,0.0) [0.0|1.0] "" BMS
 SG_ UDB29VCCD : 29|1@0+ (1.0,0.0) [0.0|1.0] "" BMS
 SG_ UDB30VCCD : 30|1@0+ (1.0,0.0) [0.0|1.0] "" BMS
 SG_ UDB31VCCD : 31|1@0+ (1.0,0.0) [0.0|1.0] "" BMS
 SG_ UDB32VCCD : 32|1@0+ (1.0,0.0) [0.0|1.0] "" BMS
 SG_ UDB33VCCD : 33|1@0+ (1.0,0.0) [0.0|1.0] "" BMS
 SG_ UDB34VCCD : 34|1@0+ (1.0,0.0) [0.0|1.0] "" BMS
 SG_ UDB35VCCD : 35|1@0+ (1.0,0.0) [0.0|1.0] "" BMS
 SG_ UDB36VCCD : 36|1@0+ (1.0,0.0) [0.0|1.0] "" BMS
 SG_ UDB37VCCD : 37|1@0+ (1.0,0.0) [0.0|1.0] "" BMS
 SG_ UDB38VCCD : 38|1@0+ (1.0,0.0) [0.0|1.0] "" BMS
 SG_ UDB39VCCD : 39|1@0+ (1.0,0.0) [0.0|1.0] "" BMS
 SG_ UDB40VCCD : 40|1@0+ (1.0,0.0) [0.0|1.0] "" BMS
 SG_ UDB41VCCD : 41|1@0+ (1.0,0.0) [0.0|1.0] "" BMS
 SG_ UDB42VCCD : 42|1@0+ (1.0,0.0) [0.0|1.0] "" BMS
 SG_ UDB43VCCD : 43|1@0+ (1.0,0.0) [0.0|1.0] "" BMS
 SG_ UDB44VCCD : 44|1@0+ (1.0,0.0) [0.0|1.0] "" BMS
 SG_ UDB45VCCD : 45|1@0+ (1.0,0.0) [0.0|1.0] "" BMS
 SG_ UDB46VCCD : 46|1@0+ (1.0,0.0) [0.0|1.0] "" BMS
 SG_ UDB47VCCD : 47|1@0+ (1.0,0.0) [0.0|1.0] "" BMS
 SG_ UDB49VCCD : 49|1@0+ (1.0,0.0) [0.0|1.0] "" BMS
 SG_ UDB50VCCD : 50|1@0+ (1.0,0.0) [0.0|1.0] "" BMS
 SG_ UDB51VCCD : 51|1@0+ (1.0,0.0) [0.0|1.0] "" BMS
 SG_ UDB52VCCD : 52|1@0+ (1.0,0.0) [0.0|1.0] "" BMS
 SG_ UDB53VCCD : 53|1@0+ (1.0,0.0) [0.0|1.0] "" BMS
 SG_ VCCDPtCanfdActiveWakeup : 12|1@0+ (1,0) [0|1] "" BMS
 SG_ VCCDPtCanfdNodeAddress : 7|8@0+ (1.0,0.0) [0.0|255.0] "" BMS
 SG_ VCCDPtCanfdRepeatMsgReq : 8|1@0+ (1,0) [0|1] "" BMS
 SG_ VCCDPtCanfdRepeatMsgSt : 16|1@0+ (1,0) [0|1] "" BMS

BO_ 2047 XCDPtFuncDiagReqFr : 8 Vector__XXX
 SG_ VCCDPtFuncDiagReq : 7|64@0+ (1,0) [0|18446744073709551615] "" BMS

BO_ 1844 XCDToBMSPtDiagReqFr : 64 Vector__XXX
 SG_ VCCDToBMSDiagReq : 7|512@0+ (1,0) [0|0] "" BMS

CM_ SG_ 1021 HvBattTempRSMS65 "BattTemp RSMS Signal Group  Detail temperature of probes in HV battery";
CM_ SG_ 1021 HvBattTempRSMS66 "BattTemp RSMS Signal Group  Detail temperature of probes in HV battery";
CM_ SG_ 1021 HvBattTempRSMS67 "BattTemp RSMS Signal Group  Detail temperature of probes in HV battery";
CM_ SG_ 1021 HvBattTempRSMS68 "BattTemp RSMS Signal Group  Detail temperature of probes in HV battery";
CM_ SG_ 1021 HvBattTempRSMS69 "BattTemp RSMS Signal Group  Detail temperature of probes in HV battery";
CM_ SG_ 1021 HvBattTempRSMS70 "BattTemp RSMS Signal Group  Detail temperature of probes in HV battery";
CM_ SG_ 1021 HvBattTempRSMS71 "BattTemp RSMS Signal Group  Detail temperature of probes in HV battery";
CM_ SG_ 1021 HvBattTempRSMS72 "BattTemp RSMS Signal Group  Detail temperature of probes in HV battery";
CM_ SG_ 1021 HvBattTempRSMS73 "BattTemp RSMS Signal Group  Detail temperature of probes in HV battery";
CM_ SG_ 1021 HvBattTempRSMS74 "BattTemp RSMS Signal Group  Detail temperature of probes in HV battery";
CM_ SG_ 1021 HvBattTempRSMS75 "BattTemp RSMS Signal Group  Detail temperature of probes in HV battery";
CM_ SG_ 1021 HvBattTempRSMS76 "BattTemp RSMS Signal Group  Detail temperature of probes in HV battery";
CM_ SG_ 1021 HvBattTempRSMS77 "BattTemp RSMS Signal Group  Detail temperature of probes in HV battery";
CM_ SG_ 1021 HvBattTempRSMS78 "BattTemp RSMS Signal Group  Detail temperature of probes in HV battery";
CM_ SG_ 1021 HvBattTempRSMS79 "BattTemp RSMS Signal Group  Detail temperature of probes in HV battery";
CM_ SG_ 1021 HvBattTempRSMS80 "BattTemp RSMS Signal Group  Detail temperature of probes in HV battery";
CM_ SG_ 1022 HvBattTempRSMS81 "BattTemp RSMS Signal Group  Detail temperature of probes in HV battery";
CM_ SG_ 1022 HvBattTempRSMS82 "BattTemp RSMS Signal Group  Detail temperature of probes in HV battery";
CM_ SG_ 1022 HvBattTempRSMS83 "BattTemp RSMS Signal Group  Detail temperature of probes in HV battery";
CM_ SG_ 1022 HvBattTempRSMS84 "BattTemp RSMS Signal Group  Detail temperature of probes in HV battery";
CM_ SG_ 1022 HvBattTempRSMS85 "BattTemp RSMS Signal Group  Detail temperature of probes in HV battery";
CM_ SG_ 1022 HvBattTempRSMS86 "BattTemp RSMS Signal Group  Detail temperature of probes in HV battery";
CM_ SG_ 1022 HvBattTempRSMS87 "BattTemp RSMS Signal Group  Detail temperature of probes in HV battery";
CM_ SG_ 1022 HvBattTempRSMS88 "BattTemp RSMS Signal Group  Detail temperature of probes in HV battery";
CM_ SG_ 1022 HvBattTempRSMS89 "BattTemp RSMS Signal Group  Detail temperature of probes in HV battery";
CM_ SG_ 1022 HvBattTempRSMS90 "BattTemp RSMS Signal Group  Detail temperature of probes in HV battery";
CM_ SG_ 1022 HvBattTempRSMS91 "BattTemp RSMS Signal Group  Detail temperature of probes in HV battery";
CM_ SG_ 1022 HvBattTempRSMS92 "BattTemp RSMS Signal Group  Detail temperature of probes in HV battery";
CM_ SG_ 1022 HvBattTempRSMS93 "BattTemp RSMS Signal Group  Detail temperature of probes in HV battery";
CM_ SG_ 1022 HvBattTempRSMS94 "BattTemp RSMS Signal Group  Detail temperature of probes in HV battery";
CM_ SG_ 1022 HvBattTempRSMS95 "BattTemp RSMS Signal Group  Detail temperature of probes in HV battery";
CM_ SG_ 1022 HvBattTempRSMS96 "BattTemp RSMS Signal Group  Detail temperature of probes in HV battery";
CM_ SG_ 137 HvBattChargerNumber "DC充电桩序列号";
CM_ SG_ 137 HvBattChargerRegionalCode "DC充电桩邮编";
CM_ SG_ 145 BMSChrgrCntctSts "2015+桩继电器状态";
CM_ SG_ 145 BoostChrgnOutpCurReq "Boost charging output current request
Boost电流请求";
CM_ SG_ 145 BoostChrgnOutpUReq "Boost charging output voltage request
boost输出电压";
CM_ SG_ 145 ChrgnNotAvlForFault "Charging not available for Fault";
CM_ SG_ 145 ChrgnNotAvlForT "Charging not available for temperature";
CM_ SG_ 145 DCChrgrConnectnSts "DC charger connection status.";
CM_ SG_ 145 DchaNotAvlForFlt "DisCharging not available for Fault";
CM_ SG_ 145 HvBattActBusU "High voltage battery actual pack voltage measured after main contactor";
CM_ SG_ 145 HvBattActCur "HV battery actual current  Discharging battery  positive  charging battery  negative .";
CM_ SG_ 145 HvBattActPackU "High voltage battery actual pack voltage measured before main contactor";
CM_ SG_ 145 HvBattActPwr "Actual battery pack discharge/charge power
当前电池实际充放电功率";
CM_ SG_ 145 HvBattaftcoolgReq "Hv Battery after cooling request from HVOFF to HVON";
CM_ SG_ 145 HvBattBkdheatgReq "HV battery Booked heating request after booked charging setting";
CM_ SG_ 145 HvBattDrtSts "HV battery derating Status";
CM_ SG_ 145 HvBattFltLvlIndcn "HV battery fault level indication.";
CM_ SG_ 145 HvBattMaxPwrChrgn "HV battery maximum charging power.";
CM_ SG_ 145 HvBattMaxPwrDchrgn "HV battery maximum discharging power";
CM_ SG_ 145 HvBattMaxPwrDchrgnContns "HV battery maximum discharging Continuous power 30min";
CM_ SG_ 145 HvBattModSts "High voltage battery mode status";
CM_ SG_ 145 HvBattOverHeatWarn "HV battery over heat warn for HMI light and thermal management";
CM_ SG_ 145 HvBattThermModReq "HV battery thermal mode request";
CM_ SG_ 145 HvBattUkl30LowWarn "Hv Battery kl30 Voltage too Low warn";
CM_ SG_ 145 HvBattWrmgReq "HV battery warming request after charging finished";
CM_ SG_ 145 HVOffReq "HV Off Request From BMS Current circuit contactors will open in tbd s due to faults or safety reasons.";
CM_ SG_ 145 MainCntctCtrlFlg "Main contactor Control Flag";
CM_ SG_ 145 MainCntctInhbn "Main contactor inhibition Main contactors closing is inhibited due to Hv System fault or safety issue.";
CM_ SG_ 145 MainCntctSts "Main contactor status";
CM_ SG_ 145 MainNegCntctSts "Main negative contactor status";
CM_ SG_ 145 MainPosCntctSts "Main positive contactor status";
CM_ SG_ 145 OverChargeCurrFatalFault "Temporary Charging Over Current Fatal Fault";
CM_ SG_ 145 OverDischargeCurrFatalFault "Temporary Discharging Over Current Fatal Fault";
CM_ SG_ 145 PrechrgnCntctSts "Precharging contactor status";
CM_ SG_ 148 CrsPwmSts "碰撞硬线状态";
CM_ SG_ 148 GaCMDAfeComErrFault "BMS Fault information flag";
CM_ SG_ 148 GaCMDCellVoltOpenWireLv1F "BMS Fault information flag";
CM_ SG_ 148 GaCMDCellVoltOpenWireLv2F "BMS Fault information flag";
CM_ SG_ 148 GaCMDCellVoltSamplingChipFault "BMS Fault information flag";
CM_ SG_ 148 GaCMDModltempOpenWireLv1F "BMS Fault information flag";
CM_ SG_ 148 GaCMDModltempOpenWireLv2F "BMS Fault information flag";
CM_ SG_ 148 GaCMDModlTempSamplingChipFault "BMS Fault information flag";
CM_ SG_ 148 GaCVTAfeCellVoltOORFault "BMS Fault information flag";
CM_ SG_ 148 GeBCVBatteryOverVoltageFault "BMS Fault information flag";
CM_ SG_ 148 GeBCVBatteryUnderVoltageFault "BMS Fault information flag";
CM_ SG_ 148 GeBCVBatteryVoltageOoRFault "BMS Fault information flag";
CM_ SG_ 148 GeBCVDCFuseOLFault "BMS Fault information flag";
CM_ SG_ 148 GeBCVDCFuseOoRFault "BMS Fault information flag";
CM_ SG_ 148 GeBCVHVADCComDiagFault "BMS Fault information flag";
CM_ SG_ 148 GeBCVMainDriveFuseOLFault "BMS Fault information flag";
CM_ SG_ 148 GeBCVMainDriveFuseOoRFault "BMS Fault information flag";
CM_ SG_ 148 GeBCVPackVoltageMismatchFault "BMS Fault information flag";
CM_ SG_ 148 GeBCVShuntADCSpiComFault "BMS Fault information flag";
CM_ SG_ 148 GeBCVShunttempHighFault "BMS Fault information flag";
CM_ SG_ 148 GeBCVShunttempLowFault "BMS Fault information flag";
CM_ SG_ 148 GeBCVVdncGpknOoRFault "BMS Fault information flag";
CM_ SG_ 148 GeBCVVdpcGpknOoRFault "BMS Fault information flag";
CM_ SG_ 148 GeBCVVmncGpknOoRFault "BMS Fault information flag";
CM_ SG_ 148 GeBCVVmpcGpknOoRFault "BMS Fault information flag";
CM_ SG_ 148 GeBMMKL30CLowVoltageFault "BMS Fault information flag";
CM_ SG_ 148 GeBMMKL30CUnderVoltageFault "BMS Fault information flag";
CM_ SG_ 148 GeBMMKL30CVoltSrcMaxFault "BMS Fault information flag";
CM_ SG_ 148 GeBMMKL30CVoltSrcMinFault "BMS Fault information flag";
CM_ SG_ 148 GeBMMKL30VoltSrcMaxFault "BMS Fault information flag";
CM_ SG_ 148 GeBMMKL30VoltSrcMinFault "BMS Fault information flag";
CM_ SG_ 148 GeCMDAfeDietempMsgCheckFailFault "BMS Fault information flag";
CM_ SG_ 148 GeCMDAfeDietempMsgTimeoutFault "BMS Fault information flag";
CM_ SG_ 148 GeCMDCellBaltempMsgCheckFailF "BMS Fault information flag";
CM_ SG_ 148 GeCMDDaisyChainComSuspendFault "BMS Fault information flag";
CM_ SG_ 148 GeCRSVehicleCrashFault "BMS Fault information flag";
CM_ SG_ 148 GeCTDDCFuseBlownFault "BMS Fault information flag";
CM_ SG_ 148 GeCTDDNCStuckcloseFault "BMS Fault information flag";
CM_ SG_ 148 GeCTDDNCStuckopenFault "BMS Fault information flag";
CM_ SG_ 148 GeCTDDPCStuckcloseFault "BMS Fault information flag";
CM_ SG_ 148 GeCTDDPCStuckopenFault "BMS Fault information flag";
CM_ SG_ 148 GeCTDMDFuseBlownFault "BMS Fault information flag";
CM_ SG_ 148 GeCTDMNCStuckcloseFault "BMS Fault information flag";
CM_ SG_ 148 GeCTDMNCStuckopenFault "BMS Fault information flag";
CM_ SG_ 148 GeCTDMPCStuckcloseFault "BMS Fault information flag";
CM_ SG_ 148 GeCTDMPCStuckopenFault "BMS Fault information flag";
CM_ SG_ 148 GeCTDMPRStuckopenFault "BMS Fault information flag";
CM_ SG_ 148 GeCTDPrechargeBusShortFault "BMS Fault information flag";
CM_ SG_ 148 GeCTDPrechargeTimeoutFault "BMS Fault information flag";
CM_ SG_ 148 GeCTSPrechargeOverTimesFault "BMS Fault information flag";
CM_ SG_ 148 GeCVTCellOverVoltL1Fault "BMS Fault information flag";
CM_ SG_ 148 GeCVTCellOverVoltL2Fault "BMS Fault information flag";
CM_ SG_ 148 GeCVTCellOverVoltL3Fault "BMS Fault information flag";
CM_ SG_ 148 GeCVTCellOverVoltL4Fault "BMS Fault information flag";
CM_ SG_ 148 GeCVTCellUnderVoltL1Fault "BMS Fault information flag";
CM_ SG_ 148 GeCVTCellUnderVoltL2Fault "BMS Fault information flag";
CM_ SG_ 148 GeCVTCellUnderVoltL3Fault "BMS Fault information flag";
CM_ SG_ 148 GeCVTCellUnderVoltL4Fault "BMS Fault information flag";
CM_ SG_ 148 GeCVTCellVoltOverDeviationL1F "BMS Fault information flag";
CM_ SG_ 148 GeCVTCellVoltOverDeviationL2F "BMS Fault information flag";
CM_ SG_ 148 GeDCCAPlusVoltageOoRFault "BMS Fault information flag";
CM_ SG_ 148 GeDCCCC2VoltageAbnormalFault "BMS Fault information flag";
CM_ SG_ 148 GeDCCConnectortempHighFault "BMS Fault information flag";
CM_ SG_ 148 GeDCCConnectortempHighWarningF "BMS Fault information flag";
CM_ SG_ 148 GeHVILVIL2CircuitOpenFault "BMS Fault information flag";
CM_ SG_ 148 GePFCPyroFuseCloseFault "BMS Fault information flag";
CM_ SG_ 148 GePFCPyroFuseOpenFault "BMS Fault information flag";
CM_ SG_ 148 GePRXPrivateCANBusOffFault "内CAN BusOff故障";
CM_ SG_ 148 GeSOFDischargeOverCurrentLv1F "BMS Fault information flag";
CM_ SG_ 148 GeSOFDischargeOverCurrentLv2F "BMS Fault information flag";
CM_ SG_ 148 GeSOFDischargeOverCurrentLv3F "BMS Fault information flag";
CM_ SG_ 148 GeSOFDischargeOverCurrentLv4F "BMS Fault information flag";
CM_ SG_ 148 GeSOFDischargeOverCurrentLv5F "BMS Fault information flag";
CM_ SG_ 148 GeSOFRegenChargeOverCurrentLv1F "BMS Fault information flag";
CM_ SG_ 148 GeSOFRegenChargeOverCurrentLv2F "BMS Fault information flag";
CM_ SG_ 148 GeSOFRegenChargeOverCurrentLv3F "BMS Fault information flag";
CM_ SG_ 148 GeSOFRegenChargeOverCurrentLv4F "BMS Fault information flag";
CM_ SG_ 148 GeSOFRegenChargeOverCurrentLv5F "BMS Fault information flag";
CM_ SG_ 148 GeTHMCoolFlowMismatchFault "BMS Fault information flag";
CM_ SG_ 148 GeTHMCoolSysFault "BMS Fault information flag";
CM_ SG_ 148 GeTHMHeatFlowMismatchFault "BMS Fault information flag";
CM_ SG_ 148 GeTHMInlettempHighFault "BMS Fault information flag";
CM_ SG_ 148 GeTHMInlettempLowFault "BMS Fault information flag";
CM_ SG_ 148 GeTHRThermalRunAwayFault "BMS Fault information flag";
CM_ SG_ 148 GeVRXPTCANBusOffFault "BMS Fault information flag";
CM_ SG_ 148 GeVRXVCCD090TimeOutFault "BMS Fault information flag";
CM_ SG_ 148 GeVRXVCCD271TimeOutFault "BMS Fault information flag";
CM_ SG_ 148 HvBattCntctCtrlSt "继电器时序状态";
CM_ SG_ 148 HvBattCurLimMax "HV battery max current
瞬时电流最大值";
CM_ SG_ 148 HvBattCurLimMin "HV battery min current
瞬时电流最小值";
CM_ SG_ 148 HvBattDevmtGrp01 "High voltage battery development group BMS开发帧01";
CM_ SG_ 148 HvBattDevmtGrp02 "High voltage battery development group BMS开发帧02";
CM_ SG_ 148 HvBattDevmtGrp03 "High voltage battery development group BMS开发帧03";
CM_ SG_ 148 HvBattDevmtGrp04 "High voltage battery development group BMS开发帧04";
CM_ SG_ 148 HvBattDNCHSDEna "DC负高边";
CM_ SG_ 148 HvBattDNCLSDEna "DC负低边";
CM_ SG_ 148 HvBattDPCHSDEna "DC正高边";
CM_ SG_ 148 HvBattDPCLSDEna "DC正低边";
CM_ SG_ 148 HvBattInsulGndSwtSt "绝缘Pos开关控制指令";
CM_ SG_ 148 HvBattInsulNegSwtSt "绝缘GND开关控制指令";
CM_ SG_ 148 HvBattInsulPosSwtSt "绝缘Neg开关控制指令";
CM_ SG_ 148 HvBattMNCHSDEna "主负高边";
CM_ SG_ 148 HvBattMNCLSDEna "主负低边";
CM_ SG_ 148 HvBattMPCHSDEna "主正高边";
CM_ SG_ 148 HvBattMPCLSDEna "主正低边";
CM_ SG_ 148 HvBattMPRHSDEna "预充高边";
CM_ SG_ 148 HvBattMPRLSDEna "预充低边";
CM_ SG_ 148 HvBattUkl30 "Hv battery KL30 voltage Voltage supplied in the pack from vehicle low voltage system";
CM_ SG_ 148 HvBattWorkSts "BMM电池包当前状态";
CM_ SG_ 148 HVISOMeasState "绝缘采样状态";
CM_ SG_ 148 HVIsoNegVolt "绝缘负对地电压";
CM_ SG_ 148 HVIsoPosVolt "绝缘正对地电压";
CM_ SG_ 148 IsoGndMosDiagVolt "绝缘S3驱动电压";
CM_ SG_ 148 PyroFuseSts "PyroFuse status";
CM_ SG_ 159 HvBattCSR21 "私有报文
BMS";
CM_ SG_ 159 HvBattCSR22 "私有报文
BMS";
CM_ SG_ 159 HvBattCSR23 "私有报文
BMS";
CM_ SG_ 159 HvBattCSR24 "私有报文
BMS";
CM_ SG_ 1305 BMSPtCanfdActiveWakeup "Active Wakeup Bit";
CM_ SG_ 1305 BMSPtCanfdNodeAddress "Node source address";
CM_ SG_ 1305 BMSPtCanfdRepeatMsgReq "Repeat Message Request Bit";
CM_ SG_ 1305 BMSPtCanfdRepeatMsgSt "Repeat Message State indication";
CM_ SG_ 1588 BMSToVCCDDiagResp "BMSToVCCDPtCanfdDiagRespNpdu";
CM_ SG_ 306 DCDCCurAvlMaxLV "available maximal current at DCDC Lv side considering DCDC status  positive means current flows from DCDC to LV";
CM_ SG_ 306 DCDCFltLvlIndcn "DCDC fault level indication.";
CM_ SG_ 306 DCDCModSts "DCDC mode status.";
CM_ SG_ 320 CCUSensKL30U "CCU sense KL30 voltage";
CM_ SG_ 320 DCDCPrechrgLvUVPFstVal "UVP threshold voltage during precharge";
CM_ SG_ 320 OBCAcCurActL1 "OBC AC side actual current  positive means current flows from station to OBC.";
CM_ SG_ 320 OBCAcCurActL2 "OBC AC side actual current   positive means current flows from station to OBC.";
CM_ SG_ 320 OBCAcCurActL3 "OBC AC side actual current   positive means current flows from station to OBC.";
CM_ SG_ 320 OBCAcU1Frq "OBC AC side voltage frequency of phase1";
CM_ SG_ 320 OBCAcU2Frq "OBC AC side voltage frequency of phase2";
CM_ SG_ 320 OBCAcU3Frq "OBC AC side voltage frequency of phase3";
CM_ SG_ 320 OBCAcUActL1 "OBC AC side actual voltage.";
CM_ SG_ 320 OBCAcUActL2 "OBC AC side actual voltage.";
CM_ SG_ 320 OBCAcUActL3 "OBC AC side actual voltage.";
CM_ SG_ 320 OBCCcConnectnSts "OBC Cc connection status.";
CM_ SG_ 320 OBCCcR "OBC Cc resistance";
CM_ SG_ 320 OBCChrgnPwrMax "OBC charging power max OBC available charging power considering derating  cable  charger";
CM_ SG_ 320 OBCCpDutyCyc "OBC Cp detected duty cycle.";
CM_ SG_ 320 OBCCpDutyFrq "OBC Cp detected Frequency";
CM_ SG_ 320 OBCCpSts "OBC Cp detected status.";
CM_ SG_ 320 OBCCpU "OBC Cp detected high level voltage.";
CM_ SG_ 320 OBCElockDrvU "OBC E-lock drive voltage  充电机电子锁驱动电压";
CM_ SG_ 320 OBCELockSts "OBC E lock status.";
CM_ SG_ 320 OBCFltLvlIndcn "OBC fault level indication.";
CM_ SG_ 320 OBCHeatgStrtCmplFlg "OBC Start up completion flag under heating mode";
CM_ SG_ 320 OBCHvDcCurAct "OBC HV DC side actual current  positive means current flows from OBC to HV bus.";
CM_ SG_ 320 OBCHvDcUAct "OBC HV DC side actual voltage.";
CM_ SG_ 320 OBCModSts "Mode status of OBC.";
CM_ SG_ 320 OBCPFCoutCurAct "OBC PFC out current actual 售后故障排查";
CM_ SG_ 320 OBCPFCoutVoltAct "OBC PFC out voltage actual 售后故障排查";
CM_ SG_ 320 OBCS2Sts "OBC S2 status";
CM_ SG_ 320 OBCV2xCurAvl "AC discharging available current used for V2x.  AC current positive 无论双相还是三相 都指一个相下的电流";
CM_ SG_ 320 OBCV2xS1Sts "OBC S1 status under discharg mode";
CM_ SG_ 320 OBCV2xS4Sts "OBC S4 status";
CM_ SG_ 320 OBCWakeupU "OBC wakeup line Voltage";
CM_ SG_ 655 CCUCooltFlowReq "CCU coolant flow request";
CM_ SG_ 655 CCUTCooltInlet "Temperature of CCU coolant at inlet.";
CM_ SG_ 655 DCDCActT "Actual temperature of DCDC  if several sensors are used  max temperature shall be sent.";
CM_ SG_ 655 DCDCCurActHV "Actual current measured at DCDC HV side  negative means current flows from DCDC to HV.";
CM_ SG_ 655 DCDCCurActLV "Actual current measured at DCDC LV side  positive means current flows from DCDC to LV";
CM_ SG_ 655 DCDCDrtSts "DCDC derating Status";
CM_ SG_ 655 DCDCFltFlg "DCDC fault indication";
CM_ SG_ 655 DCDCFltQntyRSMS "Quantity of faults in DCDC";
CM_ SG_ 655 DCDCModFltRSMS "DCDC mode fault information";
CM_ SG_ 655 DCDCSRMosT "DCDC SR mosfet temperature";
CM_ SG_ 655 DCDCTOverFltRSMS "DCDC over temperature fault information";
CM_ SG_ 655 DCDCUActHV "Actual voltage measured at DCDC HV side.";
CM_ SG_ 655 DCDCUActLV "Actual voltage measured at DCDC LV side.";
CM_ SG_ 655 FltDCDCCTSampleWarn "Fault LV0 DCDC CT sample warning";
CM_ SG_ 655 FltDCDCFSFlipFlopSlfChkErr "Fault LV1 DCDC FlipFlop self check error";
CM_ SG_ 655 FltDCDCFSOringLockSlfChkErr "Fault LV1 DCDC Oring Lock self check error";
CM_ SG_ 655 FltDCDCFSOringSlfChkErr "Fault LV1 DCDC Oring self check error";
CM_ SG_ 655 FltDCDCFSOVPCircuitSlfChkErr "Fault LV1 DCDC OVP Circuit self check error";
CM_ SG_ 655 FltDCDCHvdcUSelfChkErr "Fault LV1 DCDC HVDC voltage self check error";
CM_ SG_ 655 FltDCDCLvCurSelfChkErr "Fault LV1 DCDC LV current self check error";
CM_ SG_ 655 OBCActT "Actual temperature of OBC if several sensors are used  max temperature shall be sent.";
CM_ SG_ 655 OBCACVoltSts "OBC AC charging voltage status";
CM_ SG_ 655 OBCChrgnPortTL1 "Actual temperature of AC charging port.";
CM_ SG_ 655 OBCChrgnPortTL2 "Actual temperature of AC charging port.";
CM_ SG_ 655 OBCChrgnPortTL3 "Actual temperature of AC charging port.";
CM_ SG_ 655 OBCChrgnPortTN "Actual temperature of AC charging port.";
CM_ SG_ 655 OBCDrtSts "OBC derating Status OBC降额信息";
CM_ SG_ 655 OBCInsulR "OBC V2X insulation resistance value";
CM_ SG_ 655 OBCMagMaxT "OBC magnet max temperature";
CM_ SG_ 655 OBCMaxAvlDchrgnPwr "maximum avaliable discharging power";
CM_ SG_ 655 OBCPFCMosT "OBC PFC mosfet temperature";
CM_ SG_ 677 CCUReserved1 "CCU debug reserve";
CM_ SG_ 677 CCUReserved2 "CCU debug reserve";
CM_ SG_ 677 CCUReserved3 "CCU debug reserve";
CM_ SG_ 677 CCUReserved4 "CCU debug reserve";
CM_ SG_ 677 CCUtype "CCU type";
CM_ SG_ 677 DCDCFaultCode "detail DCDC fault reason";
CM_ SG_ 677 EVSEFltFlg "EVSE fault indication";
CM_ SG_ 677 FltEVSECpDutyAbnorm "Fault LV1 EVSE CP duty abnormal";
CM_ SG_ 677 FltOBCRealTiSelfChkAcAglLockErr "Fault LV1 OBC real time self check AC angle lock error";
CM_ SG_ 677 FltOBCRealTiSelfChkAcCurErr "Fault LV1 OBC real timeself check AC current error";
CM_ SG_ 677 FltOBCRealTiSelfChkAcUCurBiasErr "Fault LV1 OBC real timeself check AC voltage and current Bias error";
CM_ SG_ 677 FltOBCRealTiSelfChkAcUErr "Fault LV1 OBC real time self check AC voltage error";
CM_ SG_ 677 FltOBCRealTiSelfChkDcCurErr "Fault LV1 OBC real timeself check DC current error";
CM_ SG_ 677 FltOBCRealTiSelfChkDcUErr "Fault LV1 OBC real timeself check DC voltage error";
CM_ SG_ 677 FltOBCRealTiSelfChkLcCurBiasErr "Fault LV1 OBC real-time self-check output current Bias error";
CM_ SG_ 677 FltOBCRealTiSelfChkLcUErr "Fault LV1 OBC real timeself check bulk voltage error";
CM_ SG_ 677 FltOBCRealTiSelfChkPfcDrvErr "PFC driver power supply self check";
CM_ SG_ 677 FltOBCRealTiSelfChkV2LAcUErr "Fault LV1 OBC real time self check V2L AC voltage error";
CM_ SG_ 677 FltOBCRealTiSelfChkV2LDcUErr "Fault LV1 OBC real time self check V2L DC voltage error";
CM_ SG_ 677 OBCFaultCode "detail OBC fault reason";
CM_ SG_ 677 OBCFltFlg "OBC fault indication";
CM_ SG_ 847 CCUVersionChart "CCU version chart";
CM_ SG_ 847 CCUVersionNum "CCU version number";
CM_ SG_ 847 OBCACChrgnCurMaxAvlFb "AC charging current max value avaliable feedback";
CM_ SG_ 847 OBCV2LOverLoad "AC V2L over load flag";
CM_ SG_ 847 OBCWakeupRsn "CCU wakeup reason report";
CM_ SG_ 943 DrtDCDCCooltAbnorm "DCDC output derating due to coolant over temperature";
CM_ SG_ 943 DrtDCDCHvdcAbnorm "DCDC output derating due to HVDC voltage";
CM_ SG_ 943 DrtElockUnlck "Dreating LV0 OBC Elock unlocked during charging/heating/discharging";
CM_ SG_ 943 DrtEVSEAcPhaLoss "Derating LV0 EVSE AC phase loss";
CM_ SG_ 943 DrtEVSEAcUAbnorm "Derating LV0 OBC AC voltage abnormal";
CM_ SG_ 943 DrtInletOverT "OBC output derating due to socket over temperature";
CM_ SG_ 943 DrtInletSnsrErr "OBC output derating due to socket sensor abnormal";
CM_ SG_ 943 DrtOBCCooltTAbnorm "OBC output derating due to coolant over temperature";
CM_ SG_ 943 DrtOBCHvdcUAbnorm "OBC output derating due to HVDC voltage";
CM_ SG_ 943 FltActvDchaTiOut "Fault DCDC active discharge time out";
CM_ SG_ 943 FltBattSocRawCrcChkFail "BattSocRawSigGrp CRC check fail";
CM_ SG_ 943 FltBattSocRawRolCntChkFail "BattSocRawSigGrp Rollingcount check fail";
CM_ SG_ 943 FltBattURawCrcChkFail "BattURawSigGrp CRC check fail";
CM_ SG_ 943 FltBattURawRolCntChkFail "BattURawSigGrp Rollingcount check fail";
CM_ SG_ 943 FltCCUMcuErr "Fault LV1 CCU MCU error";
CM_ SG_ 943 FltCrashFail "CCU receive crash signal from VCU";
CM_ SG_ 943 FltDCChrgrCrcChkFail "DCChrgrSigGrp CRC check fail";
CM_ SG_ 943 FltDCChrgrRolCntChkFail "DCChrgrSigGrp Rollingcount check fail";
CM_ SG_ 943 FltDCDCAmbTAbnorm "DCDC ambiant Temperature abnormal";
CM_ SG_ 943 FltDCDCBoostCurAbnorm "DCDC boost current abnormal";
CM_ SG_ 943 fltDCDCCooltAbnorm "DCDC Coolant abnormal Fault";
CM_ SG_ 943 FltDCDCDspErr "Fault LV1 DCDC DSP error";
CM_ SG_ 943 fltDCDCEcapError "DCDC Ecap fault";
CM_ SG_ 943 FltDCDCHvdcCurAbnorm "Fault LV1 DCDC HVDC current abnormal";
CM_ SG_ 943 FltDCDCHvdcOVP "Fault LV1 DCDC HVDC voltage abnormal";
CM_ SG_ 943 FltDCDCHvdcUVP "Fault DCDC HVDC under voltage";
CM_ SG_ 943 FltDCDCInnerCANAbnorm "DCDC inner CAN abnormal";
CM_ SG_ 943 FltDCDCLvccOVP "Fault LV1 DCDC LVCC voltage abnormal";
CM_ SG_ 943 FltDCDCLvccUVP "Fault DCDC LVCC under voltage";
CM_ SG_ 943 FltDCDCLvCurReverse "DCDC LV current reverse fault";
CM_ SG_ 943 FltDCDCLvdcCurAbnorm "Fault LV1 DCDC LVDC current abnormal";
CM_ SG_ 943 FltDCDCLvdcOVP "Fault LV1 DCDC LVDC voltage abnormal";
CM_ SG_ 943 FltDCDCLvdcShort "Fault LV2 DCDC LVDC short";
CM_ SG_ 943 FltDCDCLvdcSrMosTAbnorm "Fault LV1 DCDC SR Mosfet Temp abnormal";
CM_ SG_ 943 FltDCDCLvdcUoverHW "DCDC LV HW overvoltage fault";
CM_ SG_ 943 FltDCDCLvdcUVP "Fault DCDC LVDC under voltage";
CM_ SG_ 943 fltDCDCLvTerminalOpen "DCDC LV Terminal Open Fault";
CM_ SG_ 943 FltDCDCLvUSelfChkErr "Fault LV1 DCDC LV voltage self check error";
CM_ SG_ 943 FltDCDCOringMosTAbnorm "DCDC Oring Mosfet temperature abnormal";
CM_ SG_ 943 FltDCDCPrechrgFail "DCDC precharge fail indication";
CM_ SG_ 943 FltDCDCSigReqCrcChkFail "Fault LV1 VCUDCDCReqSigGrp CRC check fail";
CM_ SG_ 943 FltDCDCSigReqRolCntChkFail "Fault LV1 VCUDCDCReqSigGrp Rollingcount check fail";
CM_ SG_ 943 FltDCDCStartFail "DCDC start fail fault";
CM_ SG_ 943 FltElockDrvErr "OBC output derating due to ELOCK drive voltage";
CM_ SG_ 943 FltElockFbErr "OBC output derating due to ELOCK status";
CM_ SG_ 943 FltEVSEAcCurAbnorm "Fault LV1 EVSE AC current abnormal";
CM_ SG_ 943 FltEVSEAcFrqAbnorm "Fault LV1 EVSE AC frequency abnormal";
CM_ SG_ 943 FltEVSEAcOverU "Fault LV1 EVSE AC over voltage";
CM_ SG_ 943 FltEVSEAcPhaAglUnbal "Fault LV1 EVSE AC phase angle unbalanced";
CM_ SG_ 943 FltEVSEAcPhaUUnbal "Fault LV1 EVSE AC phase voltage unbalanced";
CM_ SG_ 943 FltEVSEAcUnderU "Fault LV1 EVSE AC under voltage";
CM_ SG_ 943 FltEVSECpFrqAbnorm "Fault LV1 EVSE CP frequency abnormal";
CM_ SG_ 943 FltEVSECpUAbnorm "Fault LV1 EVSE CP volage abnormal";
CM_ SG_ 943 FltEVSEUkwnCcR "Fault LV1 EVSE unknown CC resistance";
CM_ SG_ 943 FltinletOverT "Fault LV1 Inlet over temperature";
CM_ SG_ 943 FltLcMosTAbnorm "Fault LV1 OBC LC mos tempertature abnormal";
CM_ SG_ 943 FltMainCntctStsCrcChkFail "Fault LV1 MainCntctStsSigGrp CRC check fail";
CM_ SG_ 943 FltMainCntctStsRolCntChkFail "Fault LV1 MainCntctStsSigGrp Rollingcount check fail";
CM_ SG_ 943 FltOBCCooltAbnorm "Fault LV1 OBC Coolant abnormal";
CM_ SG_ 943 FltOBCCooltSensAbnorm "Fault LV1 OBC coolant temperature sensor abnormal";
CM_ SG_ 943 FltOBCDrivSupOVP "Fault LV1 OBC Driver voltage abnormal";
CM_ SG_ 943 FltOBCDrivSupUVP "Fault LV1 OBC Driver under voltage";
CM_ SG_ 943 FltOBCDspErr "Fault LV1 OBC DSP error";
CM_ SG_ 943 FltOBCHvdcCurAbnorm "Fault LV1 OBC HVDC current abnormal";
CM_ SG_ 943 FltOBCHvdcEcapComErr "Fault LV1 OBC HVDC Ecap Voltage and Current Sampleing communication error";
CM_ SG_ 943 FltOBCHvdcOVP "Fault LV1 OBC HVDC voltage abnormal";
CM_ SG_ 943 FltOBCHvdcShoCirc "Fault LV2 OBC HVDC short circuit";
CM_ SG_ 943 FltOBCHvdcUVP "Fault OBC HVDC under voltage";
CM_ SG_ 943 FltOBCInnerCanLos "Fault LV1 inner CAN no communication";
CM_ SG_ 943 FltOBCKL30Ovp "Fault LV1 CCU KL30 voltage abnormal";
CM_ SG_ 943 FltOBCKL30Uvp "Fault OBC KL30 under voltage";
CM_ SG_ 943 FltOBCLcDrvErr "Fault LV1 OBC LC drive error";
CM_ SG_ 943 FltOBCLcOverCur "Fault LV1 OBC LC over current";
CM_ SG_ 943 FltOBCModRespTiOut "OBC mode response timeout Fault";
CM_ SG_ 943 FltOBCMosTsensErr "Fault LV1 OBC MOSFET temperature sensor abnormal";
CM_ SG_ 943 FltOBCPcbTAbnorm "Fault LV1 OBC internal tempertature abnormal";
CM_ SG_ 943 FltOBCPfcBusPreChrgFaild "Fault LV1 OBC PFC Buspre Charge Failed";
CM_ SG_ 943 FltOBCPfcHwErr "Fault LV2 OBC PFC hardware error";
CM_ SG_ 943 FltOBCPfcOVP "Fault LV1 OBC PFC Voltage abnormal";
CM_ SG_ 943 FltOBCPfcUVP "Fault OBC PFC under voltage";
CM_ SG_ 943 FltOBCPtCanAcuLos "Fault LV0 ACU No Com fail";
CM_ SG_ 943 FltOBCPtCanBcsLos "BCS frame no com";
CM_ SG_ 943 FltOBCPtCanBmdmLos "BMDM frame no com";
CM_ SG_ 943 FltOBCPtCanBmsLos "Fault LV1 BMS frame no communication of PTCAN";
CM_ SG_ 943 FltOBCPtCanBusOff "Fault LV1  outer CAN bus off";
CM_ SG_ 943 FltOBCPtCanTboxLos "Fault LV0 Tbox frame no communication";
CM_ SG_ 943 FltOBCPtCanTDcdLos "Fault LV0 DCD frame no com";
CM_ SG_ 943 FltOBCPtCanVcuLos "Fault LV1  OBC VCU frame no communication";
CM_ SG_ 943 FltOBCPvccOVP "Fault LV1 OBC PVCC volatge abnormal";
CM_ SG_ 943 FltOBCPvccUVP "Fault OBC PVCC under voltage";
CM_ SG_ 943 FltOBCRealTiSelfChkAcFrqErr "Fault LV1 OBC real timeself check AC frequency error";
CM_ SG_ 943 FltOBCSigAcuCrcChkFail "Fault LV0 ACU crc check fail";
CM_ SG_ 943 FltOBCSigAcuRolCntChkFail "Fault LV0 ACU Rollingcount check fail";
CM_ SG_ 943 FltOBCSigChrgnCrcChkFail "Fault LV1 VCUOBCChrgnSigGrp CRC check fail";
CM_ SG_ 943 FltOBCSigChrgnRolCntChkFail "Fault LV1 VCUOBCChrgnSigGrp Rollingcount check fail";
CM_ SG_ 943 FltOBCSigReqCrcChkFail "Fault LV1 VCUOBCReqSigGrp CRC check fail";
CM_ SG_ 943 FltOBCSigReqRolCntChkFail "Fault LV1 VCUOBCReqSigGrp Rollingcount check fail";
CM_ SG_ 943 FltOBCSvccOVP "Fault LV1 OBC SVCC voltage abnormal";
CM_ SG_ 943 FltOBCSvccUVP "Fault OBC SVCC under voltage";
CM_ SG_ 943 FltOBCV2xCpoutAbnorm "Fault CP output pausibility check abnormal under discharging mode";
CM_ SG_ 943 FltOBCV2xHwErrOutpNoResp "Fault LV2 OBC V2x HW error ouput no response";
CM_ SG_ 943 FltOBCV2xInpCurAbnorm "Fault LV1 OBC V2x input current abnormal";
CM_ SG_ 943 FltOBCV2xInpOVP "Fault LV1 OBC V2x input voltage abnormal";
CM_ SG_ 943 FltOBCV2xInpUVP "Fault OBC V2x input under voltage";
CM_ SG_ 943 FltOBCV2xOutpCurAbnorm "Fault LV1 OBC V2x output current abnormal";
CM_ SG_ 943 FltOBCV2xOutpFrqAbnorm "Fault LV1 OBC V2x output frequency abnormal";
CM_ SG_ 943 FltOBCV2xOutpIsolnErr "OBC V2X insulation detection fail indication";
CM_ SG_ 943 FltOBCV2xOutpOVP "Fault LV1 OBC V2x output voltage abnormal";
CM_ SG_ 943 FltOBCV2xOutpShrCirc "Fault LV2 OBC V2x output short circuit";
CM_ SG_ 943 FltOBCV2xOutpUVP "Fault OBC V2x output under voltage";
CM_ SG_ 943 FltOBCV2xPfcBusUnderU "Fault LV1 OBC V2x PFC Bus under voltage";
CM_ SG_ 943 FltPfcMosTAbnorm "Fault LV1 OBC PFC mos tempertature abnormal";
CM_ SG_ 943 FltPwrModCrcChkFail "VCUDCDCReqSigGrp Rollingcount check fail";
CM_ SG_ 943 FltPwrModRolCntChkFail "VCUOBCReqSigGrp CRC check fail";
CM_ SG_ 943 FltS2RespFail "S2 response fail indication";
CM_ SG_ 943 FltVCUActGearCrcChkFail "VCUOBCReqSigGrp Rollingcount check fail";
CM_ SG_ 943 FltVCUActGearRolCntChkFail "VCUOBCChrgnSigGrp CRC check fail";
CM_ SG_ 943 FltWhlStsCrcChkFail "WhlStsSigGrp CRC check fail";
CM_ SG_ 943 FltWhlStsRolCntChkFail "WhlStsSigGrp Rollingcount check fail";
CM_ SG_ 1009 ACchrgdEgyThisChrgnCyc "AC charged energy this charging cycle   AC charged energy .";
CM_ SG_ 1009 DchrgdEgyThisDchrgnCyc "Discharged energy this discharging cycle   V2X discharged energy .";
CM_ SG_ 1009 FltCCUSleepErr "Fault Lv0 CCU sleep error";
CM_ SG_ 1009 FltCCUWakeAbnormal "Fault Lv1 CCU wakeup abnormal";
CM_ SG_ 1009 FltDCDCC5VAbnorm "Fault Lv1 DCDC 5V supply Abnormal";
CM_ SG_ 1009 FltDCDCCooltSenAbnorm "Fault Lv0 DCDC Coolant sense abnormal";
CM_ SG_ 1009 FltDCDCHvdcCurLmtOverCur "Fault Lv0 DCDC HV DC current over limition";
CM_ SG_ 1009 FltDCDCHwFault "Fault Lv1 DCDC Hardware Failure";
CM_ SG_ 1009 FltDCDCInnerCanBusOff "Fault Lv0 DCDC Inner CAN Busoff";
CM_ SG_ 1009 FltDCDCInnerCanE2Eerr "Fault Lv0 DCDC Inner CAN E2E error";
CM_ SG_ 1009 fltDCDCModReqError "DCDC Mode Request Error
DCDC 模式请求错误";
CM_ SG_ 1009 fltHVBusResAbnormal "HV Bus Resistance abnormal
高压母线阻抗异常";
CM_ SG_ 1009 FltOBCHWFault "Fault Lv1 OBC Hardware Failure";
CM_ SG_ 1009 FltOBCInnerCanBusOff "Fault Lv1 OBC Inner CAN Busoff";
CM_ SG_ 1009 FltOBCInnerCanE2Eerr "Fault Lv1 OBC Inner CAN E2E error";
CM_ SG_ 849 ImpctEvntSts "Impact Event Status
 碰撞事件状态";
CM_ SG_ 849 ImpctEvntType1 "Impact Event Type
  碰撞事件类型";
CM_ SG_ 849 ImpctEvntType2 "Impact Event Type
  碰撞事件类型";
CM_ SG_ 849 ImpctEvntType3 "Impact Event Type
  碰撞事件类型";
CM_ SG_ 849 ImpctEvntType4 "Impact Event Type
  碰撞事件类型";
CM_ SG_ 849 ImpctEvntType5 "Impact Event Type
  碰撞事件类型";
CM_ SG_ 849 ImpctEvntType6 "Impact Event Type
  碰撞事件类型";
CM_ SG_ 849 ImpctEvntType7 "Impact Event Type
碰撞事件类型";
CM_ SG_ 179 VehSpd "Vehicle speed";
CM_ SG_ 179 VehSpdVld "Qualifier for vehicle speed signal";
CM_ SG_ 179 WhlDirFrntLe "Wheel moving direction front left";
CM_ SG_ 179 WhlDirFrntLeVld "Qualifier for wheel moving direction front left";
CM_ SG_ 179 WhlDirFrntRi "Wheel moving direction front right";
CM_ SG_ 179 WhlDirFrntRiVld "Qualifier for wheel moving direction front right";
CM_ SG_ 179 WhlDirReLe "Wheel moving direction rear left";
CM_ SG_ 179 WhlDirReLeVld "Qualifier for wheel moving direction rear left";
CM_ SG_ 179 WhlDirReRi "Wheel moving direction rear right";
CM_ SG_ 179 WhlDirReRiVld "Qualifier for wheel moving direction rear right";
CM_ SG_ 179 WhlDstTiStampFrntLe "Wheel distance time stamp for front left";
CM_ SG_ 179 WhlDstTiStampFrntRi "Wheel distance time stamp for front right";
CM_ SG_ 179 WhlDstTiStampReLe "Wheel distance time stamp for rear left";
CM_ SG_ 179 WhlDstTiStampReRi "Wheel distance time stamp for rear left";
CM_ SG_ 179 WhlSpdEdgeFrntLe "Wheel speed Edges front left";
CM_ SG_ 179 WhlSpdEdgeFrntLeVld "Qualifier for wheel speed Edges front left";
CM_ SG_ 179 WhlSpdEdgeFrntRi "Wheel speed Edges front right";
CM_ SG_ 179 WhlSpdEdgeFrntRiVld "Qualifier for wheel speed Edges front right";
CM_ SG_ 179 WhlSpdEdgeReLe "Wheel speed Edges rear left";
CM_ SG_ 179 WhlSpdEdgeReLeVld "Qualifier for wheel speed Edges rear left";
CM_ SG_ 179 WhlSpdEdgeReRi "Wheel speed Edges rear right";
CM_ SG_ 179 WhlSpdEdgeReRiVld "Qualifier for wheel speed Edges rear right";
CM_ SG_ 179 WhlSpdFrntLe "Wheel speed front left";
CM_ SG_ 179 WhlSpdFrntLeVld "Status of wheel speed front left";
CM_ SG_ 179 WhlSpdFrntRi "Wheel speed front right";
CM_ SG_ 179 WhlSpdFrntRiVld "Status of wheel speed front right";
CM_ SG_ 179 WhlSpdReLe "Wheel speed rear left";
CM_ SG_ 179 WhlSpdReLeVld "Status of wheel speed rear left";
CM_ SG_ 179 WhlSpdReRi "Wheel speed rear right";
CM_ SG_ 179 WhlSpdReRiVld "Status of wheel speed rear right";
CM_ SG_ 562 BattIRaw "Battery I raw
BMDM电池电流";
CM_ SG_ 579 BattSocRaw "Battery State of charge raw
电池SOC";
CM_ SG_ 579 BattURaw "Battery Voltage raw
电池电压";
CM_ SG_ 464 FrntMotIndHeatgActPwr "Front motor indirect heating actual power.";
CM_ SG_ 641 FrntMotIndHeatgSts "Front motor indirect heating status.";
CM_ SG_ 115 FrntMotActCurBkp "Front motor actual current on DC bus  backup
Negative means current flow from front motor to HV battery  positive means current flow from HV battery to front motor.";
CM_ SG_ 287 VCUBoosterCntctReq "Booster S7 Positive    S6 Negative    S1 contactor Request";
CM_ SG_ 287 VCUBoosterOutpCntctReq "Booster  S1  output contactor Request";
CM_ SG_ 287 VCUStrtSecForLoSoc "二次启动标志位";
CM_ SG_ 304 VCUChrgnPauseReq "充电暂停请求";
CM_ SG_ 304 VCUDischrgnProcFlg "AC Discharging control is set";
CM_ SG_ 325 VCUVSR11 "私有报文
VCU";
CM_ SG_ 325 VCUVSR12 "私有报文
VCU";
CM_ SG_ 325 VCUVSR13 "私有报文
VCU";
CM_ SG_ 325 VCUVSR14 "私有报文
VCU";
CM_ SG_ 325 VCUVSR15 "私有报文
VCU";
CM_ SG_ 325 VCUVSR16 "私有报文
VCU";
CM_ SG_ 325 VCUVSR17 "私有报文
VCU";
CM_ SG_ 325 VCUVSR18 "私有报文
VCU";
CM_ SG_ 325 VCUVSR19 "私有报文
VCU";
CM_ SG_ 327 VCUVSR21 "私有报文
VCU";
CM_ SG_ 327 VCUVSR22 "私有报文
VCU";
CM_ SG_ 327 VCUVSR23 "私有报文
VCU";
CM_ SG_ 327 VCUVSR24 "私有报文
VCU";
CM_ SG_ 327 VCUVSR25 "私有报文
VCU";
CM_ SG_ 327 VCUVSR26 "私有报文
VCU";
CM_ SG_ 327 VCUVSR27 "私有报文
VCU";
CM_ SG_ 327 VCUVSR28 "私有报文
VCU";
CM_ SG_ 327 VCUVSR29 "私有报文
VCU";
CM_ SG_ 448 AmbTEstimd "Estimated ambient temperature.";
CM_ SG_ 448 AmbTEstimdVld "Estimated ambient temperature valid value.";
CM_ SG_ 448 CooltTankLvlLo "Coolant tank level low";
CM_ SG_ 448 CooltTankLvlLoVld "Coolant tank level low valid value";
CM_ SG_ 448 FrntIncarTEstimd "Front In car estimated temperature.";
CM_ SG_ 448 FrntIncarTEstimdVld "Front In car estimated temperature valid value.";
CM_ SG_ 448 HvBattCoolgMaxPwrCp "High voltage battery cooling maximum power capacity.
高压电池最大冷却能力";
CM_ SG_ 448 HvBattCooltCircFlowEstimd "Estimated coolant flowrate for Battery coolant circuit.";
CM_ SG_ 448 HvBattHeatgMaxPwrCp "High voltage battery heating maximum power capacity.
高压电池最大加热能力";
CM_ SG_ 448 HvBattInletCooltT "Battery inlet coolant temperature";
CM_ SG_ 448 HvBattOutletCooltT "Battery outlet coolant temperature";
CM_ SG_ 448 HvBattThermPwrCns "High voltage battery thermal manage power consumption.";
CM_ SG_ 448 HvBattThermReqFb "Battery thermal request feedback.";
CM_ SG_ 448 VCUHvBattbkdHeatgEna "Hv battery book heating enable flag";
CM_ SG_ 560 VCUAuxChrgnModSts "辅件满充能量流状态";
CM_ SG_ 560 VCUCalcdActAuxPwr "VCU calculated actual HV auxiliary consumed power";
CM_ SG_ 631 CCUCooltCircFlowEstimd "Estimated coolant flowrate for CCU coolant circuit.";
CM_ SG_ 631 CmprPwrCnsAct "Compressor actual high voltage power consumption.";
CM_ SG_ 631 CmprSt "Compressor operation state";
CM_ SG_ 631 HvchPwrCns "Hvch actual high voltage power consumption.";
CM_ SG_ 631 HvchSt "Hvch operation state";
CM_ SG_ 631 VCUbkHeatEgySrcEna "Hv battery book heating using energy source enable definition";
CM_ SG_ 631 VCUChrgnScenSts "1";
CM_ SG_ 631 VCUCrsRngForAkm "Estimated range for A without Fitering
基于10km平均能耗预估续航里程无滤波 修正";
CM_ SG_ 631 VCUHVExtPortConnectnTypInfo "HV External Port Connection Type Information 重新定义 原来叫chrgnPortConnectnStsInfo 重新map";
CM_ SG_ 631 VCUOBCChrgnCurReq "HV battery AC Charging DC current request to OBC.  DC current negative";
CM_ SG_ 631 VCUOBCChrgnUReq "HV battery AC Charging HV side voltage request to OBC.";
CM_ SG_ 644 AmbTRaw "Raw ambient temperature";
CM_ SG_ 644 AmbTRawVld "Raw ambient temperature valid value";
CM_ SG_ 644 VCUDCChrgnAdapSet "DC充电兼容性开启开关";
CM_ SG_ 739 CooltTankLvlSnsrU "Coolant tank level sensor voltage";
CM_ SG_ 739 TmHvDirHeatReq "脉冲加热高压请求";
CM_ SG_ 739 VCUChrgnModSts "Charging Mode Status";
CM_ SG_ 739 VCUTrigChrgnRecordEvent "VCCD charging ordischarging data record event trigger flag";
CM_ SG_ 841 CanHvchActvDchaReq "Can Signal Used to request heating with purpose to speed-up the discharge of the HV net when disconnected from HV battery.";
CM_ SG_ 841 CanHvchEna "Can Signal ON / Off operation request.";
CM_ SG_ 841 CanHvchPwrAllwd "Can Signal Transmits the maximum power to be used for maintaining / achieving the Target temperature.";
CM_ SG_ 841 CanHvchSysMod "tell the Hvch system work mode";
CM_ SG_ 883 CmprHvCur "Compressor current";
CM_ SG_ 884 HvchHvCur "Actual calculated effective current consumed by the HVH";
CM_ SG_ 884 HvchSts "Operation Status of the HVH to the LIN Master";
CM_ SG_ 896 VCUBookChrgnSts "VCU indicate Book charging status";
CM_ SG_ 144 CarModSts "CarMode状态信号";
CM_ SG_ 144 PwrModSts "PowerMode Status";
CM_ SG_ 144 PwrModVld "PowerMode Validty";
CM_ SG_ 144 VCUAccrPedlRat "加速油门踏板开度";
CM_ SG_ 144 VCUAccrPedlRatVld "加速踏板有效性";
CM_ SG_ 144 VCUActDrvMod "VCU actual drive mode 
VCU实际驾驶模式";
CM_ SG_ 144 VCUActGearLvr "Actual gear level 车辆实际档位
P R N D挡位";
CM_ SG_ 144 VCUActGearLvrVld "车辆实际档位有效位";
CM_ SG_ 144 VCUDrvOffFcnLim "VCU send to BCS to identify whether vehcile can drive off or not as powertrain has fault and power limited.
VCU发送给BCS系统,用于判断整车动力系统是否存在故障动力受限不能起步的判断";
CM_ SG_ 144 VCUFrntEmTqRdy "The Front Motor  can be ready to response chassis torque request.
前电机可以响应扭矩请求.";
CM_ SG_ 144 VCUGearLvrAvail "Vehicle Gear Response is available for ADAS
给智驾反馈的挡位可用标志位";
CM_ SG_ 144 VCUPrkgBtnPsd "驾驶员按下P档";
CM_ SG_ 144 VCUPtRdyFlg "驾驶使能";
CM_ SG_ 144 VCUReEmTqRdy "Rear EM is ready to response chassis Torque Request
后电机是否处于Ready状态";
CM_ SG_ 144 VCURgnTqCorrnFac "Regeneration Torque Correction Factor";
CM_ SG_ 144 VCUShifterMoveFlg "驾驶员拨动了换挡杆的标志位";
CM_ SG_ 144 VCUStsModCst "energy recuperation end mode.
能量回收状态模式";
CM_ SG_ 144 VCUTarGearLvr "目标档位  P R N D挡位";
CM_ SG_ 144 VCUTarGearLvrVld "目标档位有效位";
CM_ SG_ 144 VCUVirtAccrPedl "虚拟油门开度 当前模式的pedal map反算";
CM_ SG_ 144 VCUVirtAccrPedlVld "虚拟油门开度有效位";
CM_ SG_ 151 VCUChrgnModReqToHvBatt "VCU Hv battery charging mode request";
CM_ SG_ 151 VCUDCDCHVCurLim "DCDC HV current limitation under buck mode too prevent HV battery energy too low";
CM_ SG_ 151 VCUDCDCLVCurLim "Current limitation request at DCDC Lv side. positive means current flows from LV to DCDC";
CM_ SG_ 151 VCUDCDCModReq "DCDC mode request from VCU";
CM_ SG_ 151 VCUDCDCUHVSp "DCDC conversion setpoint at DCDC HV side.";
CM_ SG_ 151 VCUDCDCULVSp "DCDC conversion setpoint at DCDC LV side.";
CM_ SG_ 151 VCUHvOffKeyReq "一键下高压激活标志";
CM_ SG_ 151 VCUModReqToHvBatt "VCU HV battery mode request";
CM_ SG_ 151 VCUOBCELockReq "request for E lock.";
CM_ SG_ 151 VCUOBCModReq "OBC mode request.";
CM_ SG_ 151 VCUOBCS2Req "Request for S2 switch.";
CM_ SG_ 465 BoosterCntctStsSigGrpChks "Signal group Checksum for E2E";
CM_ SG_ 465 BoosterCntctStsSigGrpCntr "Signal group Counter for E2E";
CM_ SG_ 465 BoosterS1CntctSts "booster (output) S1 contactor status";
CM_ SG_ 465 BoosterS6CntctSts "booster S6(negative) contactor status";
CM_ SG_ 465 BoosterS7CntctSts "booster S7(positive) contactor status";
CM_ SG_ 465 ReMotIndHeatgActPwr "Rear motor indirect heating actual power.";
CM_ SG_ 643 BoostChrgnOutpCur "Boost charging output current(电池端)
boost电池端电流";
CM_ SG_ 643 BoostChrgnOutpSigGrpChks "Signal group Checksum for E2E";
CM_ SG_ 643 BoostChrgnOutpSigGrpCntr "Signal group Counter for E2E";
CM_ SG_ 643 BoostChrgnOutpU "Boost charging output voltage(电池端)
boost电池端电压";
CM_ SG_ 643 BoosterS1CntctFlt "Booster S1 contactor fault";
CM_ SG_ 643 ReMotIndHeatgSts "Rear motor indirect heating status.";
CM_ SG_ 166 BoostChrgnInpCur "Boost Charging Input current";
CM_ SG_ 166 BoostChrgnInpSigGrpChks "Signal group Checksum for E2E";
CM_ SG_ 166 BoostChrgnInpSigGrpCntr "Signal group Counter for E2E";
CM_ SG_ 166 BoostChrgnInpU "Boost Charging Input voltage";
CM_ SG_ 166 BoostChrgnOutpPwrMax "Boost Charging output power max";
CM_ SG_ 166 ReMotActCurBkp "Rear motor actual current on DC bus  backup
Negative means current flow from rear motor to HV battery  positive means current flow from HV battery to rear motor.";
CM_ SG_ 166 ReMotModStsBkp "Rear motor mode status backup";
CM_ SG_ 182 AccrSnsrAzFrntLe "Front left sensor vertical acceleration";
CM_ SG_ 182 AccrSnsrAzFrntRi "Front right sensor vertical acceleration";
CM_ SG_ 182 AccrSnsrAzRe "Rear sensor vertical acceleration";
CM_ SG_ 846 CanCmprHvCur "Can Signal Compressor current";
CM_ SG_ 846 CanHvchHvCur "Can Signal Actual calculated effective current consumed by the HVCH";
CM_ SG_ 846 CanHvchPeakCur "Hvch peak current feedback on LIN line";
CM_ SG_ 846 CanHvchSts "Can Signal Operation Status of the HVH to the LIN-Master";
CM_ SG_ 263 DateTiDay "date time day";
CM_ SG_ 263 DateTiHr "date time hour";
CM_ SG_ 263 DateTiMilsec "date time millisecond";
CM_ SG_ 263 DateTiMins "date time minute";
CM_ SG_ 263 DateTiMth "date time month";
CM_ SG_ 263 DateTiSec "date time second";
CM_ SG_ 263 DateTiYr "date time year";
CM_ SG_ 529 SecOCMAC1 "消息认证码1";
CM_ SG_ 529 SecOCMAC2 "消息认证码2";
CM_ SG_ 529 SecOCMAC3 "消息认证码3";
CM_ SG_ 529 SecOCResetCnt "重置计数器";
CM_ SG_ 529 SecOCTripCnt "同步计数器";
CM_ SG_ 624 DcChrgnCmptFlg "National Grid DC EVSE boost charging compatibility indication flag based on navigation information";
CM_ SG_ 624 DCDsentryModSts "DCD sentry mode status";
CM_ SG_ 624 HvBattAlgCooltFlowReq "在途加热功能,热管理请求流量";
CM_ SG_ 624 HvBattAlgCooltTReq "在途加热功能,热管理请求温度";
CM_ SG_ 624 HvBattAlgThermReqSts "在途加热功能,热管理请求状态";
CM_ SG_ 624 HvBattPheatgForChrgnEnb "hvbattery preheating for charging enable
手动电池预热使能信号";
CM_ SG_ 624 VCCDHvBattChrgnCurrVld "VCCDMaxCharg CurrentEstValidflg";
CM_ SG_ 624 VCCDHvBattCurMaxLimChrgn "VCCDHV batteryMaximumcurrentallowedforbatterycharging";
CM_ SG_ 624 VCCDHvBattDchaEndSoC "VCCDHVbatteryDischarg EndSoCactual";
CM_ SG_ 624 VCCDHvBattMaxPulseTiChrgCurr "VCCDPulsecharge current";
CM_ SG_ 624 VCCDHvBattMaxPulseTiDChaCurr "VCCDPulseDischarge current.";
CM_ SG_ 624 VCCDHvBattModelVld "VCCDHVBatteryModelValidflg";
CM_ SG_ 624 VCCDHvBattPulseTiCurrVld "VCCDPuls CurrentEstValidflg";
CM_ SG_ 624 VCCDHvBattSoCAct "VCCDHVbatterySoCactual";
CM_ SG_ 624 VCCDHvBattSOCRSMS "VCCDBattSOCRSMSSignalGroupDetailSOC";
CM_ SG_ 624 VCCDHvBattSOCRSMSCode "VCCD BattSOCRSMSSignalGroupFirstSOCnumbeincurrentframe";
CM_ SG_ 624 VCCDHvBattSOCVldRSMS "VCCDBattSOCRSMSSignalGroupDetailSOCValid Flag";
CM_ SG_ 624 VCUACChrgnCurMaxSetFb "ACcharging current max value set feedback";
CM_ SG_ 624 VCUBookchrgnStopHourSts "book charging stop hour time state";
CM_ SG_ 624 VCUBookchrgnStoptMinSts "book charging stop min time state";
CM_ SG_ 624 VCUBookchrgnStrtHourSts "book charging start hour time state";
CM_ SG_ 624 VCUBookchrgnStrtMinSts "book charging start min time state";
CM_ SG_ 624 VCUBookDefdTiChrgnSts "Book defined time charging on off status";
CM_ SG_ 624 VCUBookDepartrHeatgSts "Book departure heating on off status";
CM_ SG_ 624 VCUBookDepartrHourSts "book departure hour time status";
CM_ SG_ 624 VCUBookDepartrMinSts "book departure min time status";
CM_ SG_ 624 VCUBookDepartrRepTypSts "book departure repeat type status";
CM_ SG_ 624 VCUBookPassHeatgEna "Passenger book heating enable flag";
CM_ SG_ 624 VCUChrgnSoCLimSp "Charging SOC limit setpoint  of HV battery.";
CM_ SG_ 624 VCUDchrgnSoCLimSp "Discharging SOC limit setpoint  of HV battery.";
CM_ SG_ 624 VCUPwrForbkTiPred "Charging power for BMS to predict the charging time under booked departure charging mode";
CM_ SG_ 624 VCUSOCToChrgnStat "Remaining SOC to Charging Station 
导航到有效充电站剩余SOC";
CM_ SG_ 624 VCUThermalStorageReq "Thermal Storage Request";
CM_ SG_ 624 VCUTiToChrgnStat "Driving Time to Charge Station
导航到有效充电桩时间";
CM_ SG_ 624 XCDFBSplyFlg "Flyback大功率配电标志位";
CM_ SG_ 722 SentrymodeLVPwrCtrlSts "仅哨兵模式场景低压功耗管控状态";
CM_ SG_ 722 SetMgrVCUActDrvMod "Setting Management VCU Driving Mode
个性化驾驶模式设置";
CM_ SG_ 914 TotOdoAcrt "ODO";
CM_ SG_ 938 DCDBattHlthMngtFcnSwt "DCD Battery Health Management Function Switch";
CM_ SG_ 938 DCDNavRutChgSts "Navigation route change or not";
CM_ SG_ 938 TBOXSupChrgnReq "Super Charge Request";
CM_ SG_ 993 HvBattAlgRemaChrgnTiFcn1 "剩余充电时间计算功能状态信号";
CM_ SG_ 993 HvBattAlgRemaChrgnTiFcn2 "剩余充电时间计算功能状态信号";
CM_ SG_ 993 HvBattAlgRemaChrgnTiFcn3 "剩余充电时间计算功能状态信号";
CM_ SG_ 993 HvBattAlgRemaChrgnTiFcn4 "剩余充电时间计算功能状态信号";
CM_ SG_ 993 HvBattAlgRemaChrgnTiFcn5 "剩余充电时间计算功能状态信号";
CM_ SG_ 993 HvBattAlgRemaChrgnTiFcn6 "剩余充电时间计算功能状态信号";
CM_ SG_ 993 HvBattAlgRemaChrgnTiFcn7 "剩余充电时间计算功能状态信号";
CM_ SG_ 993 HvBattAlgRemaChrgnTiFcn8 "剩余充电时间计算功能状态信号";
CM_ SG_ 993 HvBattAlgRutPheatgFcn1 "在途加热功能,热管理状态信号";
CM_ SG_ 993 HvBattAlgRutPheatgFcn2 "在途加热功能,热管理状态信号";
CM_ SG_ 993 HvBattAlgRutPheatgFcn3 "在途加热功能,热管理状态信号";
CM_ SG_ 993 HvBattAlgRutPheatgFcn4 "在途加热功能,热管理状态信号";
CM_ SG_ 993 HvBattAlgRutPheatgFcn5 "在途加热功能,热管理状态信号";
CM_ SG_ 993 HvBattAlgRutPheatgFcn6 "在途加热功能,热管理状态信号";
CM_ SG_ 993 HvBattAlgRutPheatgFcn7 "在途加热功能,热管理状态信号";
CM_ SG_ 993 HvBattAlgRutPheatgFcn8 "在途加热功能,热管理状态信号";
CM_ SG_ 1008 HigtAmbTAfTomwSoa "Highest ambient temperature from internet based on vehicle location  for the day after tomorrow
根据车辆位置从云端获取的后天环境最高温度";
CM_ SG_ 1008 HigtAmbTAfTomwValSoa "Validity of Highest ambient temperature from internet based on vehicle location  for the day after tomorrow
根据车辆位置从云端获取的后天环境最高温度可用性";
CM_ SG_ 1008 HigtAmbTTomwSoa "Highest ambient temperature from internet based on vehicle location  for tomorrow
根据车辆位置从云端获取的明天环境最高温度";
CM_ SG_ 1008 HigtAmbTTomwValSoa "Validity of  Highest ambient temperature from internet based on vehicle location  for tomorrow
根据车辆位置从云端获取的明天环境最高温度可用性";
CM_ SG_ 1008 HvBattPheatgForChrgnTarT "hvbattery preheating for charging target temperature
手动电池预热目标温度";
CM_ SG_ 1008 LowtAmbTAfTomwSoa "Lowest ambient temperature from internet based on vehicle location  for the day after tomorrow
根据车辆位置从云端获取的后天环境最低温度";
CM_ SG_ 1008 LowtAmbTAfTomwValSoa "Validity of Lowest ambient temperature from internet based on vehicle location  for the day after tomorrow
根据车辆位置从云端获取的后天环境最低温度可用性";
CM_ SG_ 1008 VCCDHvBattCapRSMS "VCCDBattSOHRSMSSignalGroupDetail Capacity";
CM_ SG_ 1008 VCCDHvBattCapVldRSMS "VCCDBattSOH RSMS Signal GroupDetail Capacity Valid Flag";
CM_ SG_ 1008 VCCDHvBattDchaEndTempRSMS "VCCDHvBattTempRSMS GroupDetail Discharge End Battery Temp";
CM_ SG_ 1008 VCCDHvBattNextPeriodTempRSMS "VCCDHvBattTempRSMS GroupDetail Next 10 Minute Battery Temp";
CM_ SG_ 1008 VCCDHvBattResRSMS "VCCDBattSOH RSMSSignalGroupDetail Resistance";
CM_ SG_ 1008 VCCDHvBattResVldRSMS "VCCDBattSOH RSMS ignalGroupDetail ResistanceValid Flag";
CM_ SG_ 1008 VCCDHvBattSOHRSMSCode "VCCDBattSOHRSMSSignalGroupFirst SOH number in current frame";
CM_ SG_ 1008 VCCDHvBattTempRSMSCode "VCCD BattTemp RSMS Signal GroupFirst Temp number in current frame";
CM_ SG_ 1008 VCCDHvBattTempVldRSMS "VCCDHvBattTempRSMS GroupDetail Temp Valid flg";
CM_ SG_ 135 VehCfgPrmBlkIDBytePosn1 "Block ID for specific Car Configuration parameter sequence";
CM_ SG_ 135 VehCfgPrmCCPBytePosn2 "1st position in specific CCP number sequence   Block ID dependant";
CM_ SG_ 135 VehCfgPrmCCPBytePosn3 "2nd position in specific CCP number sequence   Block ID dependant";
CM_ SG_ 135 VehCfgPrmCCPBytePosn4 "3rd position in specific CCP number sequence   Block ID dependant";
CM_ SG_ 135 VehCfgPrmCCPBytePosn5 "4th position in specific CCP number sequence   Block ID dependant";
CM_ SG_ 135 VehCfgPrmCCPBytePosn6 "5th position in specific CCP number sequence   Block ID dependant";
CM_ SG_ 135 VehCfgPrmCCPBytePosn7 "6th position in specific CCP number sequence   Block ID dependant";
CM_ SG_ 135 VehCfgPrmCCPBytePosn8 "7th position in specific CCP number sequence   Block ID dependant";
CM_ SG_ 664 BattSoh "Battery State of health
电池SOH";
CM_ SG_ 664 BattTRaw "Battery temperature raw
电池温度";
CM_ SG_ 664 IVFWModSts "Inside Vehicle Fridge Worf Mode Status";
CM_ SG_ 664 LockgCenLockSts "中控锁状态";
CM_ SG_ 1296 VCCDPtCanfdActiveWakeup "Active Wakeup Bit";
CM_ SG_ 1296 VCCDPtCanfdNodeAddress "Node source address";
CM_ SG_ 1296 VCCDPtCanfdRepeatMsgReq "Repeat Message Request Bit";
CM_ SG_ 1296 VCCDPtCanfdRepeatMsgSt "Repeat Message State indication";
CM_ SG_ 2047 VCCDPtFuncDiagReq "VCCDPtCanfdFuncDiagReqNpdu";
BA_DEF_ BO_ "CANFD_BRS" ENUM "0","1";
BA_DEF_ BO_ "GenMsgCycleTime" INT 0 30000; //
BA_DEF_ BO_ "GenMsgCycleTimeFast" INT 0 30000; //
BA_DEF_ BO_ "GenMsgDelayTime" INT 0 100000; //
BA_DEF_ BO_ "GenMsgNrOfRepetition" INT 0 100000;
BA_DEF_ BO_ "GenMsgSendType" ENUM "cyclic","spontaneous","cyclicIfActive","spontaneousWithDelay","cyclicAndSpontaneous","cyclicAndSpontaneousWithDelay","IfActive","NoMsgSendType"; // [us]
BA_DEF_ BO_ "GenMsgStartDelayTime" INT 0 100000; //
BA_DEF_ BO_ "NmAsrBaseAddress" HEX 0 536870911; //
BA_DEF_ BO_ "VFrameFormat" ENUM "StandardCAN","ExtendedCAN","reserved","J1939PG","reserved","reserved","reserved","reserved","reserved","reserved","reserved","reserved","reserved","reserved","StandardCAN_FD","ExtendedCAN_FD";
BA_DEF_ SG_ "GenSigSendType" ENUM "Cyclic","OnWrite","OnWriteWithRepetition","OnChange","OnChangeWithRepetition","IfActive","IfActiveWithRepetition","NoSigSendType";
BA_DEF_ SG_ "GenSigStartValue" FLOAT -1.7976931348623157E308 18446744073709551615;
BA_DEF_DEF_ "CANFD_BRS" "1";
BA_DEF_DEF_ "GenMsgCycleTime" 0;
BA_DEF_DEF_ "GenMsgCycleTimeFast" 0;
BA_DEF_DEF_ "GenMsgDelayTime" 0;
BA_DEF_DEF_ "GenMsgNrOfRepetition" 0;
BA_DEF_DEF_ "GenSigStartValue" 0;
BA_DEF_DEF_ "GenMsgStartDelayTime" 0;
BA_DEF_DEF_ "NmAsrBaseAddress" 1280;
BA_DEF_DEF_ "VFrameFormat" "J1939PG";
BA_DEF_DEF_ "GenSigSendType" "Cyclic";
// ECU: BMS
// Frame: ACU_PTCANFD_0x351
BA_ "GenMsgCycleTime" BO_ 849 200.000;
BA_ "GenMsgCycleTimeFast" BO_ 849 20.000;
BA_ "GenMsgNrOfRepetition" BO_ 849 20;
BA_ "GenMsgSendType" BO_ 849 4;
BA_ "VFrameFormat" BO_ 849 14;
// Frame: BCS_PTCANFD_0xB3
BA_ "GenMsgCycleTime" BO_ 179 10.000;
BA_ "GenMsgSendType" BO_ 179 0;
BA_ "VFrameFormat" BO_ 179 14;
// Frame: BMDM_PTCANFD_0x232
BA_ "GenMsgCycleTime" BO_ 562 50.000;
BA_ "GenMsgSendType" BO_ 562 0;
BA_ "VFrameFormat" BO_ 562 14;
// Frame: BMDM_PTCANFD_0x243
BA_ "GenMsgCycleTime" BO_ 579 50.000;
BA_ "GenMsgSendType" BO_ 579 0;
BA_ "VFrameFormat" BO_ 579 14;
// Frame: BMSPtCanfdNMFr
BA_ "GenMsgDelayTime" BO_ 1305 20.000;
BA_ "GenMsgSendType" BO_ 1305 1;
BA_ "VFrameFormat" BO_ 1305 0;
// Frame: BMSToXCDPtDiagRespFr
BA_ "GenMsgDelayTime" BO_ 1588 10.000;
BA_ "GenMsgSendType" BO_ 1588 1;
BA_ "VFrameFormat" BO_ 1588 14;
// Frame: BMS_PTCANFD_0x3FD
BA_ "GenMsgCycleTime" BO_ 1021 1000.000;
BA_ "GenMsgSendType" BO_ 1021 0;
BA_ "VFrameFormat" BO_ 1021 14;
// Frame: BMS_PTCANFD_0x3FE
BA_ "GenMsgCycleTime" BO_ 1022 1000.000;
BA_ "GenMsgSendType" BO_ 1022 0;
BA_ "VFrameFormat" BO_ 1022 14;
// Frame: BMS_PTCANFD_0x89
BA_ "GenMsgCycleTimeFast" BO_ 137 1000.000;
BA_ "GenMsgNrOfRepetition" BO_ 137 60;
BA_ "GenMsgSendType" BO_ 137 1;
BA_ "VFrameFormat" BO_ 137 14;
// Frame: BMS_PTCANFD_0x91
BA_ "GenMsgCycleTime" BO_ 145 10.000;
BA_ "GenMsgSendType" BO_ 145 0;
BA_ "VFrameFormat" BO_ 145 14;
// Frame: BMS_PTCANFD_0x94
BA_ "GenMsgCycleTime" BO_ 148 10.000;
BA_ "GenMsgSendType" BO_ 148 0;
BA_ "VFrameFormat" BO_ 148 14;
// Frame: BMS_PTCANFD_0x9F
BA_ "GenMsgCycleTimeFast" BO_ 159 10.000;
BA_ "GenMsgNrOfRepetition" BO_ 159 100;
BA_ "GenMsgSendType" BO_ 159 1;
BA_ "VFrameFormat" BO_ 159 14;
// Frame: CCU_PTCANFD_0x132
BA_ "GenMsgCycleTime" BO_ 306 20.000;
BA_ "GenMsgSendType" BO_ 306 0;
BA_ "VFrameFormat" BO_ 306 14;
// Frame: CCU_PTCANFD_0x140
BA_ "GenMsgCycleTime" BO_ 320 20.000;
BA_ "GenMsgSendType" BO_ 320 0;
BA_ "VFrameFormat" BO_ 320 14;
// Frame: CCU_PTCANFD_0x28F
BA_ "GenMsgCycleTime" BO_ 655 100.000;
BA_ "GenMsgSendType" BO_ 655 0;
BA_ "VFrameFormat" BO_ 655 14;
// Frame: CCU_PTCANFD_0x2A5
BA_ "GenMsgCycleTime" BO_ 677 100.000;
BA_ "GenMsgSendType" BO_ 677 0;
BA_ "VFrameFormat" BO_ 677 14;
// Frame: CCU_PTCANFD_0x34F
BA_ "GenMsgCycleTime" BO_ 847 200.000;
BA_ "GenMsgSendType" BO_ 847 0;
BA_ "VFrameFormat" BO_ 847 14;
// Frame: CCU_PTCANFD_0x3AF
BA_ "GenMsgCycleTime" BO_ 943 1000.000;
BA_ "GenMsgSendType" BO_ 943 0;
BA_ "VFrameFormat" BO_ 943 14;
// Frame: CCU_PTCANFD_0x3F1
BA_ "GenMsgCycleTime" BO_ 1009 1000.000;
BA_ "GenMsgSendType" BO_ 1009 0;
BA_ "VFrameFormat" BO_ 1009 14;
// Frame: FEDS_PTCANFD_0x1D0
BA_ "GenMsgCycleTime" BO_ 464 50.000;
BA_ "GenMsgSendType" BO_ 464 0;
BA_ "VFrameFormat" BO_ 464 14;
// Frame: FEDS_PTCANFD_0x281
BA_ "GenMsgCycleTime" BO_ 641 100.000;
BA_ "GenMsgSendType" BO_ 641 0;
BA_ "VFrameFormat" BO_ 641 14;
// Frame: FEDS_PTCANFD_0x73
BA_ "GenMsgCycleTime" BO_ 115 10.000;
BA_ "GenMsgSendType" BO_ 115 0;
BA_ "VFrameFormat" BO_ 115 14;
// Frame: FZCU_PTCANFD_0x11F
BA_ "GenMsgCycleTime" BO_ 287 10.000;
BA_ "GenMsgSendType" BO_ 287 0;
BA_ "VFrameFormat" BO_ 287 14;
// Frame: FZCU_PTCANFD_0x130
BA_ "GenMsgCycleTime" BO_ 304 20.000;
BA_ "GenMsgSendType" BO_ 304 0;
BA_ "VFrameFormat" BO_ 304 14;
// Frame: FZCU_PTCANFD_0x145
BA_ "GenMsgDelayTime" BO_ 325 10.000;
BA_ "GenMsgSendType" BO_ 325 1;
BA_ "VFrameFormat" BO_ 325 14;
// Frame: FZCU_PTCANFD_0x147
BA_ "GenMsgDelayTime" BO_ 327 10.000;
BA_ "GenMsgSendType" BO_ 327 1;
BA_ "VFrameFormat" BO_ 327 14;
// Frame: FZCU_PTCANFD_0x1C0
BA_ "GenMsgCycleTime" BO_ 448 100.000;
BA_ "GenMsgSendType" BO_ 448 0;
BA_ "VFrameFormat" BO_ 448 14;
// Frame: FZCU_PTCANFD_0x230
BA_ "GenMsgCycleTime" BO_ 560 50.000;
BA_ "GenMsgSendType" BO_ 560 0;
BA_ "VFrameFormat" BO_ 560 14;
// Frame: FZCU_PTCANFD_0x277
BA_ "GenMsgCycleTime" BO_ 631 100.000;
BA_ "GenMsgSendType" BO_ 631 0;
BA_ "VFrameFormat" BO_ 631 14;
// Frame: FZCU_PTCANFD_0x284
BA_ "GenMsgCycleTime" BO_ 644 100.000;
BA_ "GenMsgSendType" BO_ 644 0;
BA_ "VFrameFormat" BO_ 644 14;
// Frame: FZCU_PTCANFD_0x2E3
BA_ "GenMsgCycleTime" BO_ 739 100.000;
BA_ "GenMsgSendType" BO_ 739 0;
BA_ "VFrameFormat" BO_ 739 14;
// Frame: FZCU_PTCANFD_0x349
BA_ "GenMsgCycleTime" BO_ 841 200.000;
BA_ "GenMsgSendType" BO_ 841 0;
BA_ "VFrameFormat" BO_ 841 14;
// Frame: FZCU_PTCANFD_0x373
BA_ "GenMsgCycleTime" BO_ 883 200.000;
BA_ "GenMsgSendType" BO_ 883 0;
BA_ "VFrameFormat" BO_ 883 14;
// Frame: FZCU_PTCANFD_0x374
BA_ "GenMsgCycleTime" BO_ 884 200.000;
BA_ "GenMsgSendType" BO_ 884 0;
BA_ "VFrameFormat" BO_ 884 14;
// Frame: FZCU_PTCANFD_0x380
BA_ "GenMsgCycleTime" BO_ 896 500.000;
BA_ "GenMsgSendType" BO_ 896 0;
BA_ "VFrameFormat" BO_ 896 14;
// Frame: FZCU_PTCANFD_0x90
BA_ "GenMsgCycleTime" BO_ 144 10.000;
BA_ "GenMsgSendType" BO_ 144 0;
BA_ "VFrameFormat" BO_ 144 14;
// Frame: FZCU_PTCANFD_0x97
BA_ "GenMsgCycleTime" BO_ 151 10.000;
BA_ "GenMsgSendType" BO_ 151 0;
BA_ "VFrameFormat" BO_ 151 14;
// Frame: REDS_PTCANFD_0x1D1
BA_ "GenMsgCycleTime" BO_ 465 50.000;
BA_ "GenMsgSendType" BO_ 465 0;
BA_ "VFrameFormat" BO_ 465 14;
// Frame: REDS_PTCANFD_0x283
BA_ "GenMsgCycleTime" BO_ 643 100.000;
BA_ "GenMsgSendType" BO_ 643 0;
BA_ "VFrameFormat" BO_ 643 14;
// Frame: REDS_PTCANFD_0xA6
BA_ "GenMsgCycleTime" BO_ 166 10.000;
BA_ "GenMsgSendType" BO_ 166 0;
BA_ "VFrameFormat" BO_ 166 14;
// Frame: SCU_PTCANFD_0xB6
BA_ "GenMsgCycleTime" BO_ 182 10.000;
BA_ "GenMsgSendType" BO_ 182 0;
BA_ "VFrameFormat" BO_ 182 14;
// Frame: TMHIM_PTCANFD_0x34E
BA_ "GenMsgCycleTime" BO_ 846 200.000;
BA_ "GenMsgSendType" BO_ 846 0;
BA_ "VFrameFormat" BO_ 846 14;
// Frame: XCDPtCanfdNMFr
BA_ "GenMsgDelayTime" BO_ 1296 20.000;
BA_ "GenMsgSendType" BO_ 1296 1;
BA_ "VFrameFormat" BO_ 1296 0;
// Frame: XCDPtFuncDiagReqFr
BA_ "GenMsgDelayTime" BO_ 2047 2.000;
BA_ "GenMsgSendType" BO_ 2047 1;
BA_ "VFrameFormat" BO_ 2047 14;
// Frame: XCDToBMSPtDiagReqFr
BA_ "GenMsgDelayTime" BO_ 1844 2.000;
BA_ "GenMsgSendType" BO_ 1844 1;
BA_ "VFrameFormat" BO_ 1844 14;
// Frame: XCD_PTCANFD_0x107
BA_ "GenMsgCycleTime" BO_ 263 100.000;
BA_ "GenMsgSendType" BO_ 263 0;
BA_ "VFrameFormat" BO_ 263 14;
// Frame: XCD_PTCANFD_0x211
BA_ "GenMsgDelayTime" BO_ 529 2.000;
BA_ "GenMsgSendType" BO_ 529 1;
BA_ "VFrameFormat" BO_ 529 14;
// Frame: XCD_PTCANFD_0x270
BA_ "GenMsgCycleTime" BO_ 624 100.000;
BA_ "GenMsgSendType" BO_ 624 0;
BA_ "VFrameFormat" BO_ 624 14;
// Frame: XCD_PTCANFD_0x2D2
BA_ "GenMsgCycleTime" BO_ 722 50.000;
BA_ "GenMsgSendType" BO_ 722 0;
BA_ "VFrameFormat" BO_ 722 14;
// Frame: XCD_PTCANFD_0x392
BA_ "GenMsgCycleTime" BO_ 914 500.000;
BA_ "GenMsgSendType" BO_ 914 0;
BA_ "VFrameFormat" BO_ 914 14;
// Frame: XCD_PTCANFD_0x3AA
BA_ "GenMsgCycleTime" BO_ 938 1000.000;
BA_ "GenMsgCycleTimeFast" BO_ 938 40.000;
BA_ "GenMsgNrOfRepetition" BO_ 938 3;
BA_ "GenMsgSendType" BO_ 938 4;
BA_ "VFrameFormat" BO_ 938 14;
// Frame: XCD_PTCANFD_0x3E1
BA_ "GenMsgCycleTime" BO_ 993 1000.000;
BA_ "GenMsgSendType" BO_ 993 0;
BA_ "VFrameFormat" BO_ 993 14;
// Frame: XCD_PTCANFD_0x3F0
BA_ "GenMsgCycleTime" BO_ 1008 1000.000;
BA_ "GenMsgSendType" BO_ 1008 0;
BA_ "VFrameFormat" BO_ 1008 14;
// Frame: XCD_PTCANFD_0x87
BA_ "GenMsgDelayTime" BO_ 135 2.000;
BA_ "GenMsgSendType" BO_ 135 1;
BA_ "VFrameFormat" BO_ 135 14;
// Frame: XCD_PTCANFD_RT_0x298
BA_ "GenMsgCycleTime" BO_ 664 100.000;
BA_ "GenMsgSendType" BO_ 664 0;
BA_ "VFrameFormat" BO_ 664 14;
BA_ "GenSigStartValue" SG_ 182 AccrSnsrAzFrntLe 160;
BA_ "GenSigStartValue" SG_ 182 AccrSnsrAzFrntRi 160;
BA_ "GenSigStartValue" SG_ 182 AccrSnsrAzRe 160;
BA_ "GenSigSendType" SG_ 1305 BMSPtCanfdActiveWakeup 1;
BA_ "GenSigSendType" SG_ 1305 BMSPtCanfdNodeAddress 1;
BA_ "GenSigSendType" SG_ 1305 BMSPtCanfdRepeatMsgReq 1;
BA_ "GenSigSendType" SG_ 1305 BMSPtCanfdRepeatMsgSt 1;
BA_ "GenSigSendType" SG_ 1588 BMSToVCCDDiagResp 1;
BA_ "GenSigStartValue" SG_ 562 BattIRaw 1000000;
BA_ "GenSigStartValue" SG_ 579 BattSocRaw 800;
BA_ "GenSigStartValue" SG_ 664 BattSoh 900;
BA_ "GenSigStartValue" SG_ 664 BattTRaw 296;
BA_ "GenSigStartValue" SG_ 579 BattURaw 13200;
BA_ "GenSigSendType" SG_ 938 DCDBattHlthMngtFcnSwt 1;
BA_ "GenSigStartValue" SG_ 655 DCDCCurActHV 200;
BA_ "GenSigStartValue" SG_ 655 DCDCCurActLV 2000;
BA_ "GenSigSendType" SG_ 938 DCDNavRutChgSts 1;
BA_ "GenSigStartValue" SG_ 263 DateTiHr 24;
BA_ "GenSigStartValue" SG_ 263 DateTiMilsec 1000;
BA_ "GenSigStartValue" SG_ 263 DateTiMins 60;
BA_ "GenSigStartValue" SG_ 263 DateTiSec 60;
BA_ "GenSigStartValue" SG_ 115 FrntMotActCurBkp 8191;
BA_ "GenSigStartValue" SG_ 145 HvBattActPwr 4095;
BA_ "GenSigSendType" SG_ 159 HvBattCSR21 1;
BA_ "GenSigSendType" SG_ 159 HvBattCSR22 1;
BA_ "GenSigSendType" SG_ 159 HvBattCSR23 1;
BA_ "GenSigSendType" SG_ 159 HvBattCSR24 1;
BA_ "GenSigSendType" SG_ 137 HvBattChargerNumber 1;
BA_ "GenSigSendType" SG_ 137 HvBattChargerRegionalCode 1;
BA_ "GenSigSendType" SG_ 664 IVFWModSts 1;
BA_ "GenSigSendType" SG_ 849 ImpctEvntSts 1;
BA_ "GenSigSendType" SG_ 849 ImpctEvntStsSigGrpChks 1;
BA_ "GenSigSendType" SG_ 849 ImpctEvntStsSigGrpCntr 1;
BA_ "GenSigSendType" SG_ 849 ImpctEvntType1 1;
BA_ "GenSigSendType" SG_ 849 ImpctEvntType2 1;
BA_ "GenSigSendType" SG_ 849 ImpctEvntType3 1;
BA_ "GenSigSendType" SG_ 849 ImpctEvntType4 1;
BA_ "GenSigSendType" SG_ 849 ImpctEvntType5 1;
BA_ "GenSigSendType" SG_ 849 ImpctEvntType6 1;
BA_ "GenSigSendType" SG_ 849 ImpctEvntType7 1;
BA_ "GenSigSendType" SG_ 849 ImpctEvntTypeSigGrpChks 1;
BA_ "GenSigSendType" SG_ 849 ImpctEvntTypeSigGrpCntr 1;
BA_ "GenSigSendType" SG_ 1305 NMKeepAwkRsnBMS 1;
BA_ "GenSigSendType" SG_ 1296 NMKeepAwkRsnVCCD 1;
BA_ "GenSigStartValue" SG_ 320 OBCAcCurActL1 1024;
BA_ "GenSigStartValue" SG_ 320 OBCAcCurActL2 1024;
BA_ "GenSigStartValue" SG_ 320 OBCAcCurActL3 1024;
BA_ "GenSigStartValue" SG_ 320 OBCHvDcCurAct 1024;
BA_ "GenSigStartValue" SG_ 320 OBCPFCoutCurAct 1024;
BA_ "GenSigSendType" SG_ 1305 PNC55BMS 1;
BA_ "GenSigStartValue" SG_ 1305 PNC55BMS 1;
BA_ "GenSigSendType" SG_ 1296 PNC55XCD 1;
BA_ "GenSigStartValue" SG_ 1296 PNC55XCD 1;
BA_ "GenSigStartValue" SG_ 144 PwrModSts 1;
BA_ "GenSigStartValue" SG_ 166 ReMotActCurBkp 8191;
BA_ "GenSigSendType" SG_ 529 SecOCMAC1 1;
BA_ "GenSigSendType" SG_ 529 SecOCMAC2 1;
BA_ "GenSigSendType" SG_ 529 SecOCMAC3 1;
BA_ "GenSigSendType" SG_ 529 SecOCResetCnt 1;
BA_ "GenSigSendType" SG_ 529 SecOCTripCnt 1;
BA_ "GenSigSendType" SG_ 938 TBOXSupChrgnReq 1;
BA_ "GenSigSendType" SG_ 1305 UDB17BMS 1;
BA_ "GenSigSendType" SG_ 1296 UDB17VCCD 1;
BA_ "GenSigSendType" SG_ 1305 UDB18BMS 1;
BA_ "GenSigSendType" SG_ 1296 UDB18VCCD 1;
BA_ "GenSigSendType" SG_ 1305 UDB19BMS 1;
BA_ "GenSigSendType" SG_ 1296 UDB19VCCD 1;
BA_ "GenSigSendType" SG_ 1305 UDB20BMS 1;
BA_ "GenSigSendType" SG_ 1296 UDB20VCCD 1;
BA_ "GenSigSendType" SG_ 1305 UDB21BMS 1;
BA_ "GenSigSendType" SG_ 1296 UDB21VCCD 1;
BA_ "GenSigSendType" SG_ 1305 UDB22BMS 1;
BA_ "GenSigSendType" SG_ 1296 UDB22VCCD 1;
BA_ "GenSigSendType" SG_ 1305 UDB23BMS 1;
BA_ "GenSigSendType" SG_ 1296 UDB23VCCD 1;
BA_ "GenSigSendType" SG_ 1305 UDB24BMS 1;
BA_ "GenSigSendType" SG_ 1296 UDB24VCCD 1;
BA_ "GenSigSendType" SG_ 1305 UDB25BMS 1;
BA_ "GenSigSendType" SG_ 1296 UDB25VCCD 1;
BA_ "GenSigSendType" SG_ 1305 UDB26BMS 1;
BA_ "GenSigSendType" SG_ 1296 UDB26VCCD 1;
BA_ "GenSigSendType" SG_ 1305 UDB27BMS 1;
BA_ "GenSigSendType" SG_ 1296 UDB27VCCD 1;
BA_ "GenSigSendType" SG_ 1305 UDB28BMS 1;
BA_ "GenSigSendType" SG_ 1296 UDB28VCCD 1;
BA_ "GenSigSendType" SG_ 1305 UDB29BMS 1;
BA_ "GenSigSendType" SG_ 1296 UDB29VCCD 1;
BA_ "GenSigSendType" SG_ 1305 UDB30BMS 1;
BA_ "GenSigSendType" SG_ 1296 UDB30VCCD 1;
BA_ "GenSigSendType" SG_ 1305 UDB31BMS 1;
BA_ "GenSigSendType" SG_ 1296 UDB31VCCD 1;
BA_ "GenSigSendType" SG_ 1305 UDB32BMS 1;
BA_ "GenSigSendType" SG_ 1296 UDB32VCCD 1;
BA_ "GenSigSendType" SG_ 1305 UDB33BMS 1;
BA_ "GenSigSendType" SG_ 1296 UDB33VCCD 1;
BA_ "GenSigSendType" SG_ 1305 UDB34BMS 1;
BA_ "GenSigSendType" SG_ 1296 UDB34VCCD 1;
BA_ "GenSigSendType" SG_ 1305 UDB35BMS 1;
BA_ "GenSigSendType" SG_ 1296 UDB35VCCD 1;
BA_ "GenSigSendType" SG_ 1305 UDB36BMS 1;
BA_ "GenSigSendType" SG_ 1296 UDB36VCCD 1;
BA_ "GenSigSendType" SG_ 1305 UDB37BMS 1;
BA_ "GenSigSendType" SG_ 1296 UDB37VCCD 1;
BA_ "GenSigSendType" SG_ 1305 UDB38BMS 1;
BA_ "GenSigSendType" SG_ 1296 UDB38VCCD 1;
BA_ "GenSigSendType" SG_ 1305 UDB39BMS 1;
BA_ "GenSigSendType" SG_ 1296 UDB39VCCD 1;
BA_ "GenSigSendType" SG_ 1305 UDB40BMS 1;
BA_ "GenSigSendType" SG_ 1296 UDB40VCCD 1;
BA_ "GenSigSendType" SG_ 1305 UDB41BMS 1;
BA_ "GenSigSendType" SG_ 1296 UDB41VCCD 1;
BA_ "GenSigSendType" SG_ 1305 UDB42BMS 1;
BA_ "GenSigSendType" SG_ 1296 UDB42VCCD 1;
BA_ "GenSigSendType" SG_ 1305 UDB43BMS 1;
BA_ "GenSigSendType" SG_ 1296 UDB43VCCD 1;
BA_ "GenSigSendType" SG_ 1305 UDB44BMS 1;
BA_ "GenSigSendType" SG_ 1296 UDB44VCCD 1;
BA_ "GenSigSendType" SG_ 1305 UDB45BMS 1;
BA_ "GenSigSendType" SG_ 1296 UDB45VCCD 1;
BA_ "GenSigSendType" SG_ 1305 UDB46BMS 1;
BA_ "GenSigSendType" SG_ 1296 UDB46VCCD 1;
BA_ "GenSigSendType" SG_ 1305 UDB47BMS 1;
BA_ "GenSigSendType" SG_ 1296 UDB47VCCD 1;
BA_ "GenSigSendType" SG_ 1296 UDB49VCCD 1;
BA_ "GenSigSendType" SG_ 1296 UDB50VCCD 1;
BA_ "GenSigSendType" SG_ 1296 UDB51VCCD 1;
BA_ "GenSigSendType" SG_ 1296 UDB52VCCD 1;
BA_ "GenSigSendType" SG_ 1296 UDB53VCCD 1;
BA_ "GenSigStartValue" SG_ 624 VCCDHvBattSOCRSMSCode 1;
BA_ "GenSigStartValue" SG_ 1008 VCCDHvBattSOHRSMSCode 1;
BA_ "GenSigStartValue" SG_ 1008 VCCDHvBattTempRSMSCode 1;
BA_ "GenSigSendType" SG_ 1296 VCCDPtCanfdActiveWakeup 1;
BA_ "GenSigSendType" SG_ 1296 VCCDPtCanfdNodeAddress 1;
BA_ "GenSigSendType" SG_ 1296 VCCDPtCanfdRepeatMsgReq 1;
BA_ "GenSigSendType" SG_ 1296 VCCDPtCanfdRepeatMsgSt 1;
BA_ "GenSigSendType" SG_ 2047 VCCDPtFuncDiagReq 1;
BA_ "GenSigSendType" SG_ 1844 VCCDToBMSDiagReq 1;
BA_ "GenSigStartValue" SG_ 624 VCUChrgnSoCLimSp 100;
BA_ "GenSigStartValue" SG_ 624 VCUDchrgnSoCLimSp 20;
BA_ "GenSigStartValue" SG_ 144 VCUFrntEmTqRdy 1;
BA_ "GenSigStartValue" SG_ 144 VCUReEmTqRdy 1;
BA_ "GenSigStartValue" SG_ 624 VCUTiToChrgnStat 4095;
BA_ "GenSigSendType" SG_ 325 VCUVSR11 1;
BA_ "GenSigSendType" SG_ 325 VCUVSR12 1;
BA_ "GenSigSendType" SG_ 325 VCUVSR13 1;
BA_ "GenSigSendType" SG_ 325 VCUVSR14 1;
BA_ "GenSigSendType" SG_ 325 VCUVSR15 1;
BA_ "GenSigSendType" SG_ 325 VCUVSR16 1;
BA_ "GenSigSendType" SG_ 325 VCUVSR17 1;
BA_ "GenSigSendType" SG_ 325 VCUVSR18 1;
BA_ "GenSigSendType" SG_ 325 VCUVSR19 1;
BA_ "GenSigSendType" SG_ 327 VCUVSR21 1;
BA_ "GenSigSendType" SG_ 327 VCUVSR22 1;
BA_ "GenSigSendType" SG_ 327 VCUVSR23 1;
BA_ "GenSigSendType" SG_ 327 VCUVSR24 1;
BA_ "GenSigSendType" SG_ 327 VCUVSR25 1;
BA_ "GenSigSendType" SG_ 327 VCUVSR26 1;
BA_ "GenSigSendType" SG_ 327 VCUVSR27 1;
BA_ "GenSigSendType" SG_ 327 VCUVSR28 1;
BA_ "GenSigSendType" SG_ 327 VCUVSR29 1;
BA_ "GenSigSendType" SG_ 135 VehCfgPrmBlkIDBytePosn1 1;
BA_ "GenSigStartValue" SG_ 135 VehCfgPrmBlkIDBytePosn1 1;
BA_ "GenSigSendType" SG_ 135 VehCfgPrmCCPBytePosn2 1;
BA_ "GenSigSendType" SG_ 135 VehCfgPrmCCPBytePosn3 1;
BA_ "GenSigSendType" SG_ 135 VehCfgPrmCCPBytePosn4 1;
BA_ "GenSigSendType" SG_ 135 VehCfgPrmCCPBytePosn5 1;
BA_ "GenSigSendType" SG_ 135 VehCfgPrmCCPBytePosn6 1;
BA_ "GenSigSendType" SG_ 135 VehCfgPrmCCPBytePosn7 1;
BA_ "GenSigSendType" SG_ 135 VehCfgPrmCCPBytePosn8 1;
VAL_ 145 BMSChrgrCntctSts 0 "Init" 1 "Both_Open" 2 "Pos_Close" 3 "Neg_Close" 4 "Both_Close";
VAL_ 145 ChrgnNotAvlForFault 0 "Available_No_fault" 1 "AC_Charging_Not_Avl" 2 "DC_Charging_Not_Avl" 3 "Both_ACandDC_Not_Avl";
VAL_ 145 ChrgnNotAvlForT 0 "Init" 1 "Available" 2 "Not_Available";
VAL_ 145 DCChrgrConnectnSts 0 "Disconnected" 1 "ConnectedAActive" 2 "ConnectedANotActive" 3 "Fault" 4 "Not_determined";
VAL_ 145 DchaNotAvlForFlt 0 "Available(No_fault)" 1 "AC_Discharging_Not_Avl" 2 "DC_Discharging_Not_Avl" 3 "Both_AC&DC_Not_Avl";
VAL_ 145 HvBattActBusU 16383 "Invalid";
VAL_ 145 HvBattActCur 65535 "Invalid";
VAL_ 145 HvBattActPackU 16383 "Invalid";
VAL_ 145 HvBattaftcoolgReq 0 "Not_Request" 1 "Request";
VAL_ 145 HvBattBkdheatgReq 0 "Not_Request" 1 "Request";
VAL_ 145 HvBattDrtSts 0 "No_derating" 1 "Derating";
VAL_ 145 HvBattFltLvlIndcn 0 "No_Fault" 1 "Fault_LV0_DTCOnly" 2 "Fault_LV1_PowerLimited" 3 "Fault_LV2_Limphome" 4 "Fault_LV3_Poweroffwithdelay" 5 "Fault_LV4_Poweroff";
VAL_ 145 HvBattModSts 0 "Init" 1 "Standby" 2 "Precharge" 3 "HV_On" 4 "Emergency_Off" 5 "Direct_Heating" 6 "Integrity_test" 7 "Service_mode" 8 "After_Run" 9 "Preheating" 10 "Warming";
VAL_ 145 HvBattOverHeatWarn 0 "No_Warn" 1 "Warn";
VAL_ 145 HvBattThermModReq 0 "HvBattThermaMod_Idle" 1 "HvBattThermaMod_Balancing" 2 "HvBattThermaMod_Cooling" 3 "HvBattThermaMod_Heating" 4 "Not_used" 5 "HvBattThermaMod_Passive_Cooling" 6 "HvBattThermaMod_Direct_Heating";
VAL_ 145 HvBattUkl30LowWarn 0 "Not_Warn" 1 "Warn";
VAL_ 145 HvBattWrmgReq 0 "Not_Request" 1 "Request";
VAL_ 145 HVOffReq 0 "No_request" 1 "Request";
VAL_ 145 MainCntctCtrlFlg 0 "Open" 1 "Close";
VAL_ 145 MainCntctInhbn 0 "Normal" 1 "Inhibited";
VAL_ 145 MainCntctSts 0 "Open" 1 "Close" 2 "Not_determined";
VAL_ 145 MainNegCntctSts 0 "Open" 1 "Close" 2 "Not_determined";
VAL_ 145 MainPosCntctSts 0 "Open" 1 "Close" 2 "Not_determined";
VAL_ 145 OverChargeCurrFatalFault 0 "No_fault" 1 "Fault";
VAL_ 145 OverDischargeCurrFatalFault 0 "No_fault" 1 "Fault";
VAL_ 145 PrechrgnCntctSts 0 "Open" 1 "Close" 2 "Not_determined";
VAL_ 148 CrsPwmSts 0 "No_Crash" 1 "Crash" 2 "Not_determined";
VAL_ 148 GaCMDAfeComErrFault 0 "No_fault" 1 "Fault";
VAL_ 148 GaCMDCellVoltOpenWireLv1F 0 "No_fault" 1 "Fault";
VAL_ 148 GaCMDCellVoltOpenWireLv2F 0 "No_fault" 1 "Fault";
VAL_ 148 GaCMDCellVoltSamplingChipFault 0 "No_fault" 1 "Fault";
VAL_ 148 GaCMDModltempOpenWireLv1F 0 "No_fault" 1 "Fault";
VAL_ 148 GaCMDModltempOpenWireLv2F 0 "No_fault" 1 "Fault";
VAL_ 148 GaCMDModlTempSamplingChipFault 0 "No_fault" 1 "Fault";
VAL_ 148 GaCVTAfeCellVoltOORFault 0 "No_fault" 1 "Fault";
VAL_ 148 GeBCVBatteryOverVoltageFault 0 "No_fault" 1 "Fault";
VAL_ 148 GeBCVBatteryUnderVoltageFault 0 "No_fault" 1 "Fault";
VAL_ 148 GeBCVBatteryVoltageOoRFault 0 "No_fault" 1 "Fault";
VAL_ 148 GeBCVDCFuseOLFault 0 "No_fault" 1 "Fault";
VAL_ 148 GeBCVDCFuseOoRFault 0 "No_fault" 1 "Fault";
VAL_ 148 GeBCVHVADCComDiagFault 0 "No_fault" 1 "Fault";
VAL_ 148 GeBCVMainDriveFuseOLFault 0 "No_fault" 1 "Fault";
VAL_ 148 GeBCVMainDriveFuseOoRFault 0 "No_fault" 1 "Fault";
VAL_ 148 GeBCVPackVoltageMismatchFault 0 "No_fault" 1 "Fault";
VAL_ 148 GeBCVShuntADCSpiComFault 0 "No_fault" 1 "Fault";
VAL_ 148 GeBCVShunttempHighFault 0 "No_fault" 1 "Fault";
VAL_ 148 GeBCVShunttempLowFault 0 "No_fault" 1 "Fault";
VAL_ 148 GeBCVVdncGpknOoRFault 0 "No_fault" 1 "Fault";
VAL_ 148 GeBCVVdpcGpknOoRFault 0 "No_fault" 1 "Fault";
VAL_ 148 GeBCVVmncGpknOoRFault 0 "No_fault" 1 "Fault";
VAL_ 148 GeBCVVmpcGpknOoRFault 0 "No_fault" 1 "Fault";
VAL_ 148 GeBMMKL30CLowVoltageFault 0 "No_fault" 1 "Fault";
VAL_ 148 GeBMMKL30CUnderVoltageFault 0 "No_fault" 1 "Fault";
VAL_ 148 GeBMMKL30CVoltSrcMaxFault 0 "No_fault" 1 "Fault";
VAL_ 148 GeBMMKL30CVoltSrcMinFault 0 "No_fault" 1 "Fault";
VAL_ 148 GeBMMKL30VoltSrcMaxFault 0 "No_fault" 1 "Fault";
VAL_ 148 GeBMMKL30VoltSrcMinFault 0 "No_fault" 1 "Fault";
VAL_ 148 GeCMDAfeDietempMsgCheckFailFault 0 "No_fault" 1 "Fault";
VAL_ 148 GeCMDAfeDietempMsgTimeoutFault 0 "No_fault" 1 "Fault";
VAL_ 148 GeCMDCellBaltempMsgCheckFailF 0 "No_fault" 1 "Fault";
VAL_ 148 GeCMDDaisyChainComSuspendFault 0 "No_fault" 1 "Fault";
VAL_ 148 GeCRSVehicleCrashFault 0 "No_fault" 1 "Fault";
VAL_ 148 GeCTDDCFuseBlownFault 0 "No_fault" 1 "Fault";
VAL_ 148 GeCTDDNCStuckcloseFault 0 "No_fault" 1 "Fault";
VAL_ 148 GeCTDDNCStuckopenFault 0 "No_fault" 1 "Fault";
VAL_ 148 GeCTDDPCStuckcloseFault 0 "No_fault" 1 "Fault";
VAL_ 148 GeCTDDPCStuckopenFault 0 "No_fault" 1 "Fault";
VAL_ 148 GeCTDMDFuseBlownFault 0 "No_fault" 1 "Fault";
VAL_ 148 GeCTDMNCStuckcloseFault 0 "No_fault" 1 "Fault";
VAL_ 148 GeCTDMNCStuckopenFault 0 "No_fault" 1 "Fault";
VAL_ 148 GeCTDMPCStuckcloseFault 0 "No_fault" 1 "Fault";
VAL_ 148 GeCTDMPCStuckopenFault 0 "No_fault" 1 "Fault";
VAL_ 148 GeCTDMPRStuckopenFault 0 "No_fault" 1 "Fault";
VAL_ 148 GeCTDPrechargeBusShortFault 0 "No_fault" 1 "Fault";
VAL_ 148 GeCTDPrechargeTimeoutFault 0 "No_fault" 1 "Fault";
VAL_ 148 GeCTSPrechargeOverTimesFault 0 "No_fault" 1 "Fault";
VAL_ 148 GeCVTCellOverVoltL1Fault 0 "No_fault" 1 "Fault";
VAL_ 148 GeCVTCellOverVoltL2Fault 0 "No_fault" 1 "Fault";
VAL_ 148 GeCVTCellOverVoltL3Fault 0 "No_fault" 1 "Fault";
VAL_ 148 GeCVTCellOverVoltL4Fault 0 "No_fault" 1 "Fault";
VAL_ 148 GeCVTCellUnderVoltL1Fault 0 "No_fault" 1 "Fault";
VAL_ 148 GeCVTCellUnderVoltL2Fault 0 "No_fault" 1 "Fault";
VAL_ 148 GeCVTCellUnderVoltL3Fault 0 "No_fault" 1 "Fault";
VAL_ 148 GeCVTCellUnderVoltL4Fault 0 "No_fault" 1 "Fault";
VAL_ 148 GeCVTCellVoltOverDeviationL1F 0 "No_fault" 1 "Fault";
VAL_ 148 GeCVTCellVoltOverDeviationL2F 0 "No_fault" 1 "Fault";
VAL_ 148 GeDCCAPlusVoltageOoRFault 0 "No_fault" 1 "Fault";
VAL_ 148 GeDCCCC2VoltageAbnormalFault 0 "No_fault" 1 "Fault";
VAL_ 148 GeDCCConnectortempHighFault 0 "No_fault" 1 "Fault";
VAL_ 148 GeDCCConnectortempHighWarningF 0 "No_fault" 1 "Fault";
VAL_ 148 GeHVILVIL2CircuitOpenFault 0 "No_fault" 1 "Fault";
VAL_ 148 GePFCPyroFuseCloseFault 0 "No_fault" 1 "Fault";
VAL_ 148 GePFCPyroFuseOpenFault 0 "No_fault" 1 "Fault";
VAL_ 148 GeSOFDischargeOverCurrentLv1F 0 "No_fault" 1 "Fault";
VAL_ 148 GeSOFDischargeOverCurrentLv2F 0 "No_fault" 1 "Fault";
VAL_ 148 GeSOFDischargeOverCurrentLv3F 0 "No_fault" 1 "Fault";
VAL_ 148 GeSOFDischargeOverCurrentLv4F 0 "No_fault" 1 "Fault";
VAL_ 148 GeSOFDischargeOverCurrentLv5F 0 "No_fault" 1 "Fault";
VAL_ 148 GeSOFRegenChargeOverCurrentLv1F 0 "No_fault" 1 "Fault";
VAL_ 148 GeSOFRegenChargeOverCurrentLv2F 0 "No_fault" 1 "Fault";
VAL_ 148 GeSOFRegenChargeOverCurrentLv3F 0 "No_fault" 1 "Fault";
VAL_ 148 GeSOFRegenChargeOverCurrentLv4F 0 "No_fault" 1 "Fault";
VAL_ 148 GeSOFRegenChargeOverCurrentLv5F 0 "No_fault" 1 "Fault";
VAL_ 148 GeTHMCoolFlowMismatchFault 0 "No_fault" 1 "Fault";
VAL_ 148 GeTHMCoolSysFault 0 "No_fault" 1 "Fault";
VAL_ 148 GeTHMHeatFlowMismatchFault 0 "No_fault" 1 "Fault";
VAL_ 148 GeTHMInlettempHighFault 0 "No_fault" 1 "Fault";
VAL_ 148 GeTHMInlettempLowFault 0 "No_fault" 1 "Fault";
VAL_ 148 GeTHRThermalRunAwayFault 0 "No_fault" 1 "Fault";
VAL_ 148 GeVRXPTCANBusOffFault 0 "No_fault" 1 "Fault";
VAL_ 148 GeVRXVCCD090TimeOutFault 0 "No_fault" 1 "Fault";
VAL_ 148 GeVRXVCCD271TimeOutFault 0 "No_fault" 1 "Fault";
VAL_ 148 HvBattDNCHSDEna 0 "Not_enabled" 1 "Enabled";
VAL_ 148 HvBattDNCLSDEna 0 "Not_enabled" 1 "Enabled";
VAL_ 148 HvBattDPCHSDEna 0 "Not_enabled" 1 "Enabled";
VAL_ 148 HvBattDPCLSDEna 0 "Not_enabled" 1 "Enabled";
VAL_ 148 HvBattInsulGndSwtSt 0 "Open" 1 "Close";
VAL_ 148 HvBattInsulNegSwtSt 0 "Open" 1 "Close";
VAL_ 148 HvBattInsulPosSwtSt 0 "Open" 1 "Close";
VAL_ 148 HvBattMNCHSDEna 0 "Not_enabled" 1 "Enabled";
VAL_ 148 HvBattMNCLSDEna 0 "Not_enabled" 1 "Enabled";
VAL_ 148 HvBattMPCHSDEna 0 "Not_enabled" 1 "Enabled";
VAL_ 148 HvBattMPCLSDEna 0 "Not_enabled" 1 "Enabled";
VAL_ 148 HvBattMPRHSDEna 0 "Not_enabled" 1 "Enabled";
VAL_ 148 HvBattMPRLSDEna 0 "Not_enabled" 1 "Enabled";
VAL_ 148 PyroFuseSts 0 "Normal" 1 "Fuse_broken";
VAL_ 159 HvBattCSR21 0 "Not_Blocked" 1 "Blocked";
VAL_ 159 HvBattCSR22 0 "No_Fault" 1 "Fault";
VAL_ 159 HvBattCSR23 0 "Not_Enable" 1 "Enable";
VAL_ 159 HvBattCSR24 0 "Not_active" 1 "Active";
VAL_ 1305 BMSPtCanfdActiveWakeup 0 "passive_wakeup" 1 "active_Wakeup";
VAL_ 1305 BMSPtCanfdRepeatMsgReq 0 "Repeat_Message_State_not_requested" 1 "Repeat_Message_State_requested";
VAL_ 1305 BMSPtCanfdRepeatMsgSt 0 "Not_in_Repeat_Message_State" 1 "In_Repeat_Message_State";
VAL_ 306 DCDCFltLvlIndcn 0 "No_fault" 1 "Fault_LV0_DTCOnly" 2 "Fault_LV1_Recoverable" 3 "Fault_LV2_Not_Recoverable";
VAL_ 306 DCDCModSts 0 "Init" 1 "Standby" 2 "Ready" 3 "Power_conversion_HV_to_LV_Buck" 4 "Power_conversion_LV_to_HV_Boost" 5 "After_Run" 6 "Failure" 7 "Active_discharge";
VAL_ 320 OBCAcCurActL1 2047 "Invalid";
VAL_ 320 OBCAcCurActL2 2047 "Invalid";
VAL_ 320 OBCAcCurActL3 2047 "Invalid";
VAL_ 320 OBCAcU1Frq 127 "Invalid";
VAL_ 320 OBCAcU2Frq 127 "Invalid";
VAL_ 320 OBCAcU3Frq 127 "Invalid";
VAL_ 320 OBCAcUActL1 1023 "Invalid";
VAL_ 320 OBCAcUActL2 1023 "Invalid";
VAL_ 320 OBCAcUActL3 1023 "Invalid";
VAL_ 320 OBCCcConnectnSts 0 "Disconnected" 1 "Half_connected" 2 "Connected_Charging" 3 "Connected_V2L" 4 "Connected_V2V" 5 "Fault" 6 "Not_determined";
VAL_ 320 OBCCcR 1023 "Invalid";
VAL_ 320 OBCCpSts 0 "Cp_state_NOK" 1 "Cp_state_OK";
VAL_ 320 OBCCpU 127 "Invalid";
VAL_ 320 OBCElockDrvU 510 "Invalid";
VAL_ 320 OBCELockSts 0 "Not_determined" 1 "Unlocked" 2 "Locked";
VAL_ 320 OBCFltLvlIndcn 0 "No_fault" 1 "Fault_LV0_DTCOnly" 2 "Fault_LV1_Recoverable" 3 "Fault_LV2_Not_Recoverable";
VAL_ 320 OBCHeatgStrtCmplFlg 0 "No_Finished" 1 "Finished";
VAL_ 320 OBCHvDcCurAct 2047 "Invalid";
VAL_ 320 OBCHvDcUAct 1023 "Invalid";
VAL_ 320 OBCModSts 0 "Init" 1 "Standby" 2 "Ready" 3 "Charging" 4 "Discharging" 5 "Heating" 6 "After_Run" 7 "Failure";
VAL_ 320 OBCPFCoutCurAct 2047 "Invalid";
VAL_ 320 OBCPFCoutVoltAct 1023 "Invalid";
VAL_ 320 OBCS2Sts 0 "Open" 1 "Closed";
VAL_ 320 OBCV2xS1Sts 0 "Constant_voltage_output" 1 "PWM_output";
VAL_ 320 OBCV2xS4Sts 0 "Sense_status" 1 "Output_status";
VAL_ 655 CCUTCooltInlet 255 "Invalid";
VAL_ 655 DCDCActT 255 "Invalid";
VAL_ 655 DCDCCurActHV 511 "Invalid";
VAL_ 655 DCDCCurActLV 4095 "Invalid";
VAL_ 655 DCDCDrtSts 0 "No_derating" 1 "Derating";
VAL_ 655 DCDCFltFlg 0 "No_fault" 1 "Fault";
VAL_ 655 DCDCModFltRSMS 0 "no_fault" 1 "level_1_fault" 2 "level_2_fault" 3 "level_3_fault";
VAL_ 655 DCDCSRMosT 255 "Invalid";
VAL_ 655 DCDCTOverFltRSMS 0 "no_fault" 1 "level_1_fault" 2 "level_2_fault" 3 "level_3_fault";
VAL_ 655 DCDCUActHV 4095 "Invalid";
VAL_ 655 DCDCUActLV 32767 "Invalid";
VAL_ 655 FltDCDCCTSampleWarn 0 "No_fault" 1 "Fault";
VAL_ 655 FltDCDCFSFlipFlopSlfChkErr 0 "No_fault" 1 "Fault";
VAL_ 655 FltDCDCFSOringLockSlfChkErr 0 "No_fault" 1 "Fault";
VAL_ 655 FltDCDCFSOringSlfChkErr 0 "No_fault" 1 "Fault";
VAL_ 655 FltDCDCFSOVPCircuitSlfChkErr 0 "No_fault" 1 "Fault";
VAL_ 655 FltDCDCHvdcUSelfChkErr 0 "No_fault" 1 "Fault";
VAL_ 655 FltDCDCLvCurSelfChkErr 0 "No_fault" 1 "Fault";
VAL_ 655 OBCActT 255 "Invalid";
VAL_ 655 OBCACVoltSts 0 "Not_available" 1 "single_phase" 2 "three_phase" 3 "three_phase_loss_L1" 4 "three_phase_loss_L2" 5 "three_phase_loss_L3";
VAL_ 655 OBCChrgnPortTL1 255 "Invalid";
VAL_ 655 OBCChrgnPortTL2 255 "Invalid";
VAL_ 655 OBCChrgnPortTL3 255 "Invalid";
VAL_ 655 OBCChrgnPortTN 255 "Invalid";
VAL_ 655 OBCDrtSts 0 "No_derating" 1 "Derating";
VAL_ 655 OBCMagMaxT 255 "Invalid";
VAL_ 655 OBCPFCMosT 255 "Invalid";
VAL_ 677 EVSEFltFlg 0 "No_fault" 1 "Fault";
VAL_ 677 FltEVSECpDutyAbnorm 0 "No_fault" 1 "Fault";
VAL_ 677 FltOBCRealTiSelfChkAcAglLockErr 0 "No_fault" 1 "Fault";
VAL_ 677 FltOBCRealTiSelfChkAcCurErr 0 "No_fault" 1 "Fault";
VAL_ 677 FltOBCRealTiSelfChkAcUCurBiasErr 0 "No_fault" 1 "Fault";
VAL_ 677 FltOBCRealTiSelfChkAcUErr 0 "No_fault" 1 "Fault";
VAL_ 677 FltOBCRealTiSelfChkDcCurErr 0 "No_fault" 1 "Fault";
VAL_ 677 FltOBCRealTiSelfChkDcUErr 0 "No_fault" 1 "Fault";
VAL_ 677 FltOBCRealTiSelfChkLcCurBiasErr 0 "No_fault" 1 "Fault";
VAL_ 677 FltOBCRealTiSelfChkLcUErr 0 "No_fault" 1 "Fault";
VAL_ 677 FltOBCRealTiSelfChkPfcDrvErr 0 "No_fault" 1 "Fault";
VAL_ 677 FltOBCRealTiSelfChkV2LAcUErr 0 "No_fault" 1 "Fault";
VAL_ 677 FltOBCRealTiSelfChkV2LDcUErr 0 "No_fault" 1 "Fault";
VAL_ 677 OBCFltFlg 0 "No_fault" 1 "Fault";
VAL_ 847 OBCV2LOverLoad 0 "No_warning" 1 "Warning" 2 "Overload";
VAL_ 847 OBCWakeupRsn 0 "Passive_wakeup" 1 "Active_wakeup";
VAL_ 943 DrtDCDCCooltAbnorm 0 "No_derating" 1 "Derating";
VAL_ 943 DrtDCDCHvdcAbnorm 0 "No_derating" 1 "Derating";
VAL_ 943 DrtElockUnlck 0 "No_derating" 1 "Derating";
VAL_ 943 DrtEVSEAcPhaLoss 0 "No_derating" 1 "Derating";
VAL_ 943 DrtEVSEAcUAbnorm 0 "No_derating" 1 "Derating";
VAL_ 943 DrtInletOverT 0 "No_Derating" 1 "Derating";
VAL_ 943 DrtInletSnsrErr 0 "No_derating" 1 "Derating";
VAL_ 943 DrtOBCCooltTAbnorm 0 "No_derating" 1 "Derating";
VAL_ 943 DrtOBCHvdcUAbnorm 0 "No_derating" 1 "Derating";
VAL_ 943 FltActvDchaTiOut 0 "No_fault" 1 "Fault";
VAL_ 943 FltBattSocRawCrcChkFail 0 "No_fault" 1 "Fault";
VAL_ 943 FltBattSocRawRolCntChkFail 0 "No_fault" 1 "Fault";
VAL_ 943 FltBattURawCrcChkFail 0 "No_fault" 1 "Fault";
VAL_ 943 FltBattURawRolCntChkFail 0 "No_fault" 1 "Fault";
VAL_ 943 FltCCUMcuErr 0 "No_fault" 1 "Fault";
VAL_ 943 FltCrashFail 0 "No_fault" 1 "Fault";
VAL_ 943 FltDCChrgrCrcChkFail 0 "No_fault" 1 "Fault";
VAL_ 943 FltDCChrgrRolCntChkFail 0 "No_fault" 1 "Fault";
VAL_ 943 FltDCDCAmbTAbnorm 0 "No_fault" 1 "Fault";
VAL_ 943 FltDCDCBoostCurAbnorm 0 "No_fault" 1 "Fault";
VAL_ 943 fltDCDCCooltAbnorm 0 "No_fault" 1 "Fault";
VAL_ 943 FltDCDCDspErr 0 "No_fault" 1 "Fault";
VAL_ 943 fltDCDCEcapError 0 "No_fault" 1 "Fault";
VAL_ 943 FltDCDCHvdcCurAbnorm 0 "No_fault" 1 "Fault";
VAL_ 943 FltDCDCHvdcOVP 0 "No_fault" 1 "Fault";
VAL_ 943 FltDCDCHvdcUVP 0 "No_fault" 1 "Fault";
VAL_ 943 FltDCDCInnerCANAbnorm 0 "No_fault" 1 "Fault";
VAL_ 943 FltDCDCLvccOVP 0 "No_fault" 1 "Fault";
VAL_ 943 FltDCDCLvccUVP 0 "No_fault" 1 "Fault";
VAL_ 943 FltDCDCLvCurReverse 0 "No_fault" 1 "Fault";
VAL_ 943 FltDCDCLvdcCurAbnorm 0 "No_fault" 1 "Fault";
VAL_ 943 FltDCDCLvdcOVP 0 "No_fault" 1 "Fault";
VAL_ 943 FltDCDCLvdcShort 0 "No_fault" 1 "Fault";
VAL_ 943 FltDCDCLvdcSrMosTAbnorm 0 "No_fault" 1 "Fault";
VAL_ 943 FltDCDCLvdcUoverHW 0 "No_fault" 1 "Fault";
VAL_ 943 FltDCDCLvdcUVP 0 "No_fault" 1 "Fault";
VAL_ 943 fltDCDCLvTerminalOpen 0 "No_fault" 1 "Fault";
VAL_ 943 FltDCDCLvUSelfChkErr 0 "No_fault" 1 "Fault";
VAL_ 943 FltDCDCOringMosTAbnorm 0 "No_fault" 1 "Fault";
VAL_ 943 FltDCDCPrechrgFail 0 "No_Fault" 1 "Fault";
VAL_ 943 FltDCDCSigReqCrcChkFail 0 "No_fault" 1 "Fault";
VAL_ 943 FltDCDCSigReqRolCntChkFail 0 "No_fault" 1 "Fault";
VAL_ 943 FltDCDCStartFail 0 "No_fault" 1 "Fault";
VAL_ 943 FltElockDrvErr 0 "No_fault" 1 "Fault";
VAL_ 943 FltElockFbErr 0 "No_fault" 1 "Fault";
VAL_ 943 FltEVSEAcCurAbnorm 0 "No_fault" 1 "Fault";
VAL_ 943 FltEVSEAcFrqAbnorm 0 "No_fault" 1 "Fault";
VAL_ 943 FltEVSEAcOverU 0 "No_fault" 1 "Fault";
VAL_ 943 FltEVSEAcPhaAglUnbal 0 "No_fault" 1 "Fault";
VAL_ 943 FltEVSEAcPhaUUnbal 0 "No_fault" 1 "Fault";
VAL_ 943 FltEVSEAcUnderU 0 "No_fault" 1 "Fault";
VAL_ 943 FltEVSECpFrqAbnorm 0 "No_fault" 1 "Fault";
VAL_ 943 FltEVSECpUAbnorm 0 "No_fault" 1 "Fault";
VAL_ 943 FltEVSEUkwnCcR 0 "No_fault" 1 "Fault";
VAL_ 943 FltinletOverT 0 "No_fault" 1 "Fault";
VAL_ 943 FltLcMosTAbnorm 0 "No_fault" 1 "Fault";
VAL_ 943 FltMainCntctStsCrcChkFail 0 "No_fault" 1 "Fault";
VAL_ 943 FltMainCntctStsRolCntChkFail 0 "No_fault" 1 "Fault";
VAL_ 943 FltOBCCooltAbnorm 0 "No_fault" 1 "Fault";
VAL_ 943 FltOBCCooltSensAbnorm 0 "No_fault" 1 "Fault";
VAL_ 943 FltOBCDrivSupOVP 0 "No_fault" 1 "Fault";
VAL_ 943 FltOBCDrivSupUVP 0 "No_fault" 1 "Fault";
VAL_ 943 FltOBCDspErr 0 "No_fault" 1 "Fault";
VAL_ 943 FltOBCHvdcCurAbnorm 0 "No_fault" 1 "Fault";
VAL_ 943 FltOBCHvdcEcapComErr 0 "No_fault" 1 "Fault";
VAL_ 943 FltOBCHvdcOVP 0 "No_fault" 1 "Fault";
VAL_ 943 FltOBCHvdcShoCirc 0 "No_fault" 1 "Fault";
VAL_ 943 FltOBCHvdcUVP 0 "No_fault" 1 "Fault";
VAL_ 943 FltOBCInnerCanLos 0 "No_fault" 1 "Fault";
VAL_ 943 FltOBCKL30Ovp 0 "No_fault" 1 "Fault";
VAL_ 943 FltOBCKL30Uvp 0 "No_fault" 1 "Fault";
VAL_ 943 FltOBCLcDrvErr 0 "No_fault" 1 "Fault";
VAL_ 943 FltOBCLcOverCur 0 "No_fault" 1 "Fault";
VAL_ 943 FltOBCModRespTiOut 0 "No_fault" 1 "Fault";
VAL_ 943 FltOBCMosTsensErr 0 "No_fault" 1 "Fault";
VAL_ 943 FltOBCPcbTAbnorm 0 "No_fault" 1 "Fault";
VAL_ 943 FltOBCPfcBusPreChrgFaild 0 "No_fault" 1 "Fault";
VAL_ 943 FltOBCPfcHwErr 0 "No_fault" 1 "Fault";
VAL_ 943 FltOBCPfcOVP 0 "No_fault" 1 "Fault";
VAL_ 943 FltOBCPfcUVP 0 "No_fault" 1 "Fault";
VAL_ 943 FltOBCPtCanAcuLos 0 "No_fault" 1 "Fault";
VAL_ 943 FltOBCPtCanBcsLos 0 "No_fault" 1 "Fault";
VAL_ 943 FltOBCPtCanBmdmLos 0 "No_fault" 1 "Fault";
VAL_ 943 FltOBCPtCanBmsLos 0 "No_fault" 1 "Fault";
VAL_ 943 FltOBCPtCanBusOff 0 "No_fault" 1 "Fault";
VAL_ 943 FltOBCPtCanTboxLos 0 "No_fault" 1 "Fault";
VAL_ 943 FltOBCPtCanTDcdLos 0 "No_fault" 1 "Fault";
VAL_ 943 FltOBCPtCanVcuLos 0 "No_fault" 1 "Fault";
VAL_ 943 FltOBCPvccOVP 0 "No_fault" 1 "Fault";
VAL_ 943 FltOBCPvccUVP 0 "No_fault" 1 "Fault";
VAL_ 943 FltOBCRealTiSelfChkAcFrqErr 0 "No_fault" 1 "Fault";
VAL_ 943 FltOBCSigAcuCrcChkFail 0 "No_fault" 1 "Fault";
VAL_ 943 FltOBCSigAcuRolCntChkFail 0 "No_fault" 1 "Fault";
VAL_ 943 FltOBCSigChrgnCrcChkFail 0 "No_fault" 1 "Fault";
VAL_ 943 FltOBCSigChrgnRolCntChkFail 0 "No_fault" 1 "Fault";
VAL_ 943 FltOBCSigReqCrcChkFail 0 "No_fault" 1 "Fault";
VAL_ 943 FltOBCSigReqRolCntChkFail 0 "No_fault" 1 "Fault";
VAL_ 943 FltOBCSvccOVP 0 "No_fault" 1 "Fault";
VAL_ 943 FltOBCSvccUVP 0 "No_fault" 1 "Fault";
VAL_ 943 FltOBCV2xCpoutAbnorm 0 "No_fault" 1 "Fault";
VAL_ 943 FltOBCV2xHwErrOutpNoResp 0 "No_fault" 1 "Fault";
VAL_ 943 FltOBCV2xInpCurAbnorm 0 "No_fault" 1 "Fault";
VAL_ 943 FltOBCV2xInpOVP 0 "No_fault" 1 "Fault";
VAL_ 943 FltOBCV2xInpUVP 0 "No_fault" 1 "Fault";
VAL_ 943 FltOBCV2xOutpCurAbnorm 0 "No_fault" 1 "Fault";
VAL_ 943 FltOBCV2xOutpFrqAbnorm 0 "No_fault" 1 "Fault";
VAL_ 943 FltOBCV2xOutpIsolnErr 0 "No_fault" 1 "Fault";
VAL_ 943 FltOBCV2xOutpOVP 0 "No_fault" 1 "Fault";
VAL_ 943 FltOBCV2xOutpShrCirc 0 "No_fault" 1 "Fault";
VAL_ 943 FltOBCV2xOutpUVP 0 "No_fault" 1 "Fault";
VAL_ 943 FltOBCV2xPfcBusUnderU 0 "No_fault" 1 "Fault";
VAL_ 943 FltPfcMosTAbnorm 0 "No_fault" 1 "Fault";
VAL_ 943 FltPwrModCrcChkFail 0 "No_fault" 1 "Fault";
VAL_ 943 FltPwrModRolCntChkFail 0 "No_fault" 1 "Fault";
VAL_ 943 FltS2RespFail 0 "No_fault" 1 "Fault";
VAL_ 943 FltVCUActGearCrcChkFail 0 "No_fault" 1 "Fault";
VAL_ 943 FltVCUActGearRolCntChkFail 0 "No_fault" 1 "Fault";
VAL_ 943 FltWhlStsCrcChkFail 0 "No_fault" 1 "Fault";
VAL_ 943 FltWhlStsRolCntChkFail 0 "No_fault" 1 "Fault";
VAL_ 1009 FltCCUSleepErr 0 "No_Fault" 1 "Fault";
VAL_ 1009 FltCCUWakeAbnormal 0 "No_Fault" 1 "Fault";
VAL_ 1009 FltDCDCC5VAbnorm 0 "No_Fault" 1 "Fault";
VAL_ 1009 FltDCDCCooltSenAbnorm 0 "No_Fault" 1 "Fault";
VAL_ 1009 FltDCDCHvdcCurLmtOverCur 0 "No_Fault" 1 "Fault";
VAL_ 1009 FltDCDCHwFault 0 "No_Fault" 1 "Fault";
VAL_ 1009 FltDCDCInnerCanBusOff 0 "No_Fault" 1 "Fault";
VAL_ 1009 FltDCDCInnerCanE2Eerr 0 "No_Fault" 1 "Fault";
VAL_ 1009 fltDCDCModReqError 0 "No_fault" 1 "Fault";
VAL_ 1009 fltHVBusResAbnormal 0 "No_fault" 1 "Fault";
VAL_ 1009 FltOBCHWFault 0 "No_Fault" 1 "Fault";
VAL_ 1009 FltOBCInnerCanBusOff 0 "No_Fault" 1 "Fault";
VAL_ 1009 FltOBCInnerCanE2Eerr 0 "No_Fault" 1 "Fault";
VAL_ 849 ImpctEvntSts 0 "Normal" 1 "Crash";
VAL_ 849 ImpctEvntType1 0 "No_crash" 1 "Front_crash";
VAL_ 849 ImpctEvntType2 0 "No_crash" 1 "LeftSide_crash";
VAL_ 849 ImpctEvntType3 0 "No_crash" 1 "RightSide_crash";
VAL_ 849 ImpctEvntType4 0 "No_crash" 1 "Rear_crash";
VAL_ 849 ImpctEvntType5 0 "No_crash" 1 "Roll_Over";
VAL_ 849 ImpctEvntType6 0 "No_crash" 1 "EPP";
VAL_ 849 ImpctEvntType7 0 "No_Front_crash-high" 1 "Front_crash-high";
VAL_ 179 VehSpdVld 0 "Invalid" 1 "Valid";
VAL_ 179 WhlDirFrntLe 0 "Undefined" 1 "Standstill" 2 "Forward" 3 "Backward";
VAL_ 179 WhlDirFrntLeVld 0 "Invalid" 1 "Valid";
VAL_ 179 WhlDirFrntRi 0 "Undefined" 1 "Standstill" 2 "Forward" 3 "Backward";
VAL_ 179 WhlDirFrntRiVld 0 "Invalid" 1 "Valid";
VAL_ 179 WhlDirReLe 0 "Undefined" 1 "Standstill" 2 "Forward" 3 "Backward";
VAL_ 179 WhlDirReLeVld 0 "Invalid" 1 "Valid";
VAL_ 179 WhlDirReRi 0 "Undefined" 1 "Standstill" 2 "Forward" 3 "Backward";
VAL_ 179 WhlDirReRiVld 0 "Invalid" 1 "Valid";
VAL_ 179 WhlSpdEdgeFrntLeVld 0 "Invalid" 1 "Valid";
VAL_ 179 WhlSpdEdgeFrntRiVld 0 "Invalid" 1 "Valid";
VAL_ 179 WhlSpdEdgeReLeVld 0 "Invalid" 1 "Valid";
VAL_ 179 WhlSpdEdgeReRiVld 0 "Invalid" 1 "Valid";
VAL_ 179 WhlSpdFrntLeVld 0 "Invalid" 1 "Valid";
VAL_ 179 WhlSpdFrntRiVld 0 "Invalid" 1 "Valid";
VAL_ 179 WhlSpdReLeVld 0 "Invalid" 1 "Valid";
VAL_ 179 WhlSpdReRiVld 0 "Invalid" 1 "Valid";
VAL_ 641 FrntMotIndHeatgSts 0 "Not_available" 1 "Available";
VAL_ 287 VCUBoosterCntctReq 0 "Open" 1 "Close";
VAL_ 287 VCUBoosterOutpCntctReq 0 "Open" 1 "Close";
VAL_ 287 VCUStrtSecForLoSoc 0 "Not_active" 1 "active";
VAL_ 304 VCUChrgnPauseReq 0 "Start" 1 "Pause";
VAL_ 304 VCUDischrgnProcFlg 0 "False" 1 "True";
VAL_ 448 AmbTEstimdVld 0 "Not_Valid" 1 "Valid";
VAL_ 448 CooltTankLvlLo 0 "False" 1 "True";
VAL_ 448 CooltTankLvlLoVld 0 "Not_Valid" 1 "Valid";
VAL_ 448 FrntIncarTEstimdVld 0 "Not_Valid" 1 "Valid";
VAL_ 448 HvBattThermReqFb 0 "Idle" 1 "Balance" 2 "Cooling" 3 "Heating" 4 "Fault" 5 "Passive_Cooling" 6 "Direct_Heating";
VAL_ 448 VCUHvBattbkdHeatgEna 0 "False" 1 "True";
VAL_ 560 VCUAuxChrgnModSts 0 "Standby" 1 "Work";
VAL_ 631 CmprSt 0 "Idle" 1 "Working";
VAL_ 631 HvchSt 0 "Idle" 1 "Working";
VAL_ 631 VCUbkHeatEgySrcEna 0 "Init" 1 "EVSE" 2 "HvBatt";
VAL_ 631 VCUHVExtPortConnectnTypInfo 0 "Non_connected" 1 "AC_Half_connected" 2 "AC_charger_conneccted" 3 "DC_charger_connected" 4 "Wireless_charger_connected" 5 "V2L_connected" 6 "V2V_connected" 7 "Multi_connection" 8 "Charger_connected_with_fault" 9 "DC_Half_connected";
VAL_ 644 AmbTRawVld 0 "Not_Valid" 1 "Valid";
VAL_ 644 VCUDCChrgnAdapSet 0 "Disable" 1 "Enable";
VAL_ 739 TmHvDirHeatReq 0 "No_Request" 1 "Request";
VAL_ 739 VCUChrgnModSts 0 "Not_in_charging" 1 "In_preparation" 2 "Charging_in_progress" 3 "Charging_done" 4 "Charging_fault" 5 "Driving_charging" 6 "Charging_stop" 7 "Booking_charging_waiting" 8 "Preheating_in_process" 9 "Warming_in_progress";
VAL_ 739 VCUTrigChrgnRecordEvent 0 "Not_Active" 1 "Active";
VAL_ 841 CanHvchActvDchaReq 0 "Not_Active" 1 "Active";
VAL_ 841 CanHvchEna 0 "Not_Enable" 1 "Enable";
VAL_ 841 CanHvchSysMod 0 "Default" 1 "HP_Mode" 2 "Undefined" 3 "Undefined";
VAL_ 884 HvchSts 0 "Off" 1 "TemporaryLock" 2 "OverheatLock" 3 "PermanentLock" 4 "Operation" 5 "Production_Mode" 6 "Post_Production_Mode" 7 "ActiveDischarge";
VAL_ 896 VCUBookChrgnSts 0 "StartCharging" 1 "BookCharging" 2 "StopCharging";
VAL_ 144 CarModSts 0 "Normal" 1 "Fcy" 2 "Trsnp" 3 "Showroom" 4 "Dyno" 5 "TestDrv" 6 "Service" 7 "Reserved3";
VAL_ 144 PwrModSts 0 "OFF" 1 "Awake" 2 "ACC" 3 "RUN";
VAL_ 144 PwrModVld 0 "Valid" 1 "NotValid";
VAL_ 144 VCUAccrPedlRatVld 0 "invalid" 1 "valid";
VAL_ 144 VCUActDrvMod 0 "Comfort_Mode" 1 "Sport_Mode" 2 "Individual_Mode1" 3 "Individual_Mode2" 4 "Individual_Mode3" 5 "Wet_Mode" 6 "Mountain_Mode" 7 "Battle_Mode" 8 "Extreme_Eco_mode" 9 "Sport_plus_mode" 10 "Off_road_Mode" 11 "ECO_Mode" 12 "Standard_Mode" 13 "AntMtnsick_Mode";
VAL_ 144 VCUActGearLvr 0 "P_Park_gear" 1 "R_Reverse_gear" 2 "N_Neutral_gear" 3 "D_Drive_gear";
VAL_ 144 VCUActGearLvrVld 0 "Invalid" 1 "Valid";
VAL_ 144 VCUDrvOffFcnLim 0 "Normal;" 1 "PowerLimited_Fault.";
VAL_ 144 VCUFrntEmTqRdy 0 "Not_ready" 1 "Ready";
VAL_ 144 VCUGearLvrAvail 0 "Not_Available" 1 "Available";
VAL_ 144 VCUPrkgBtnPsd 0 "Not_Active" 1 "active";
VAL_ 144 VCUPtRdyFlg 0 "not_active" 1 "active";
VAL_ 144 VCUReEmTqRdy 0 "Not_ready" 1 "Ready";
VAL_ 144 VCUStsModCst 0 "OPedl_No_RgL1" 1 "OPedl_No_RgL2" 2 "OPedl_No_RgL3" 3 "OPedl_No_RgL4" 4 "OPedl_No_RgL5" 5 "OPedl_No_ADASactive" 6 "OPedl_No_RoadGradientInhbit" 7 "OPedl_No_PowerDown" 16 "OPedl_Stop_RgL1" 17 "OPedl_Stop_RgL2" 18 "OPedl_Stop_RgL3" 19 "OPedl_Stop_RgL4" 20 "OPedl_Stop_RgL5" 21 "OPedl_Crp_RgL1" 22 "OPedl_Crp_RgL2" 23 "OPedl_Crp_RgL3" 24 "OPedl_Crp_RgL4" 25 "OPedl_Crp_RgL5" 26 "OPedl_FW_RgL1" 27 "OPedl_FW_RgL2" 28 "OPedl_FW_RgL3" 29 "OPedl_FW_RgL4" 30 "OPedl_FW_RgL5";
VAL_ 144 VCUTarGearLvr 0 "P_Park_gear" 1 "R_Reverse_gear" 2 "N_Neutral_gear" 3 "D_Drive_gear";
VAL_ 144 VCUTarGearLvrVld 0 "Invalid" 1 "Valid";
VAL_ 144 VCUVirtAccrPedlVld 0 "Invalid" 1 "Valid";
VAL_ 151 VCUChrgnModReqToHvBatt 0 "No_Charge_Req" 1 "AC_Charging" 2 "DC_Charging" 3 "Wireless_Charging" 4 "V2L" 5 "V2V";
VAL_ 151 VCUDCDCModReq 0 "Init" 1 "Standby" 2 "Active_Discharge" 3 "Buck_mode_request" 4 "Boost_mode_request";
VAL_ 151 VCUHvOffKeyReq 0 "Disable" 1 "Enable";
VAL_ 151 VCUModReqToHvBatt 0 "No_Req" 1 "HV_Off" 3 "HV_On" 4 "Emergency_off" 5 "Direct_Heating" 6 "Preheating_Req" 7 "Warming_Req";
VAL_ 151 VCUOBCELockReq 0 "No_request" 1 "Unlock" 2 "Lock";
VAL_ 151 VCUOBCModReq 1 "Standby" 3 "Charging" 4 "Discharging" 5 "Heating";
VAL_ 151 VCUOBCS2Req 0 "Open" 1 "Close";
VAL_ 465 BoosterS1CntctSts 0 "Open" 1 "Close" 2 "Not_determined";
VAL_ 465 BoosterS6CntctSts 0 "Open" 1 "Close" 2 "Not_determined";
VAL_ 465 BoosterS7CntctSts 0 "Open" 1 "Close" 2 "Not_determined";
VAL_ 643 BoosterS1CntctFlt 0 "No_fault" 1 "Stuck_close" 2 "Stuck_open" 3 "Contact_control_fault";
VAL_ 643 ReMotIndHeatgSts 0 "Not_available" 1 "Available";
VAL_ 166 ReMotModStsBkp 0 "Init" 1 "Standby" 2 "Ready" 3 "Torque_Control" 4 "Speed_Control" 5 "Buck_mode" 6 "Booster_Charge" 7 "Booster_Voltage_Control" 8 "Booster_discharge" 9 "Active_Discharge" 10 "Direct_Heating" 11 "Booster_discharge_finished" 12 "OffsetCal" 13 "Failure" 14 "After_Run" 15 "Buck_Control";
VAL_ 846 CanHvchSts 0 "Off" 1 "TemporaryLock" 2 "OverheatLock" 3 "PermanentLock" 4 "Operation" 5 "Production_Mode" 6 "Post_Production_Mode" 7 "ActiveDischarge";
VAL_ 263 DateTiDay 0 "init";
VAL_ 263 DateTiHr 24 "Invalid";
VAL_ 263 DateTiMilsec 0 "0" 999 "999" 1000 "invalid";
VAL_ 263 DateTiMins 60 "Invalid";
VAL_ 263 DateTiMth 0 "Invalid";
VAL_ 263 DateTiSec 60 "Invalid";
VAL_ 263 DateTiYr 255 "Invalid";
VAL_ 624 DcChrgnCmptFlg 0 "Disable" 1 "Enable";
VAL_ 624 DCDsentryModSts 0 "Switch_off" 1 "Switch_on" 2 "Standby1" 3 "Standby2" 4 "Alert" 5 "Alarm" 6 "SentryVideoSaving1" 7 "SentryVideoSaving2";
VAL_ 624 HvBattPheatgForChrgnEnb 0 "False" 1 "Ture";
VAL_ 624 VCCDHvBattChrgnCurrVld 0 "Invalid" 1 "Valid";
VAL_ 624 VCCDHvBattModelVld 0 "Invalid" 1 "Valid";
VAL_ 624 VCCDHvBattPulseTiCurrVld 0 "Invalid" 1 "Valid";
VAL_ 624 VCCDHvBattSOCVldRSMS 0 "Invalid" 1 "Valid";
VAL_ 624 VCUBookDefdTiChrgnSts 0 "OFF" 1 "ON" 2 "Not_avaliable";
VAL_ 624 VCUBookDepartrHeatgSts 0 "OFF" 1 "ON" 2 "Not_avaliable";
VAL_ 624 VCUBookDepartrRepTypSts 0 "Everyday_repeat;" 1 "Weekday_repeat" 2 "Not_available";
VAL_ 624 VCUBookPassHeatgEna 0 "False" 1 "True";
VAL_ 624 VCUSOCToChrgnStat 101 "无效值";
VAL_ 624 VCUThermalStorageReq 0 "Init" 1 "Request" 2 "No_Request";
VAL_ 624 VCUTiToChrgnStat 4095 "无效值";
VAL_ 624 XCDFBSplyFlg 0 "Inactive" 1 "Active";
VAL_ 722 SentrymodeLVPwrCtrlSts 0 "非仅哨兵唤醒场景" 1 "仅哨兵唤醒场景";
VAL_ 722 SetMgrVCUActDrvMod 0 "Comfort_Mode" 1 "Sport_Mode" 2 "Individual_Mode1" 3 "Individual_Mode2" 4 "Individual_Mode3" 5 "Wet_Mode" 6 "Mountain_Mode" 7 "Battle_Mode" 8 "Extreme_Eco_mode" 9 "Sport_plus_Mode" 10 "Off_road_Mode" 11 "ECO_Mode" 12 "Standard_Mode" 13 "AntMtnsick_Mode";
VAL_ 914 TotOdoAcrt 16777215 "Invaild";
VAL_ 938 DCDBattHlthMngtFcnSwt 0 "No_command" 1 "Disable_Command" 2 "Enable_Command";
VAL_ 938 DCDNavRutChgSts 0 "Dischange" 1 "Change";
VAL_ 938 TBOXSupChrgnReq 0 "No_Command" 1 "Request";
VAL_ 1008 HigtAmbTAfTomwValSoa 0 "Invalid" 1 "Valid";
VAL_ 1008 HigtAmbTTomwValSoa 0 "Invalid" 1 "Valid";
VAL_ 1008 LowtAmbTAfTomwValSoa 0 "Invalid" 1 "Valid";
VAL_ 1008 VCCDHvBattCapVldRSMS 0 "Invalid" 1 "Valid";
VAL_ 1008 VCCDHvBattResVldRSMS 0 "Invalid" 1 "Valid";
VAL_ 1008 VCCDHvBattTempVldRSMS 0 "Invalid" 1 "Valid";
VAL_ 664 IVFWModSts 0 "Off" 1 "Cool" 2 "Heat" 3 "Reserved";
VAL_ 664 LockgCenLockSts 0 "Not_defined" 1 "Unlocked" 2 "Locked" 3 "Partially_unlocked";
VAL_ 1296 VCCDPtCanfdActiveWakeup 0 "passive_wakeup" 1 "active_Wakeup";
VAL_ 1296 VCCDPtCanfdRepeatMsgReq 0 "not_requested" 1 "requested";
VAL_ 1296 VCCDPtCanfdRepeatMsgSt 0 "Not_in_Repeat_Message_State" 1 "In_Repeat_Message_State";
SIG_GROUP_ 562 BattIRawSigGrp 1 : BattIRaw BattIRawSigGrpChks BattIRawSigGrpCntr;
SIG_GROUP_ 579 BattSocRawSigGrp 1 : BattSocRaw BattSocRawSigGrpChks BattSocRawSigGrpCntr;
SIG_GROUP_ 664 BattSohSigGrp 1 : BattSoh BattSohSigGrpChks BattSohSigGrpCntr;
SIG_GROUP_ 664 BattTRawSigGrp 1 : BattTRaw BattTRawSigGrpChks BattTRawSigGrpCntr;
SIG_GROUP_ 579 BattURawSigGrp 1 : BattURaw BattURawSigGrpChks BattURawSigGrpCntr;
SIG_GROUP_ 166 BoostChrgnInpSigGrp 1 : BoostChrgnInpCur BoostChrgnInpSigGrpChks BoostChrgnInpSigGrpCntr BoostChrgnInpU;
SIG_GROUP_ 643 BoostChrgnOutpSigGrp 1 : BoostChrgnOutpCur BoostChrgnOutpSigGrpChks BoostChrgnOutpSigGrpCntr BoostChrgnOutpU;
SIG_GROUP_ 465 BoosterCntctStsSigGrp 1 : BoosterCntctStsSigGrpChks BoosterCntctStsSigGrpCntr BoosterS1CntctSts BoosterS6CntctSts BoosterS7CntctSts;
SIG_GROUP_ 145 BootChrgnOutpReqSigGrp 1 : BoostChrgnOutpCurReq BoostChrgnOutpReqSigGrpChks BoostChrgnOutpReqSigGrpCntr BoostChrgnOutpUReq;
SIG_GROUP_ 841 CanHvchEnaSigGrp 1 : CanHvchEna CanHvchEnaSigGrpChks CanHvchEnaSigGrpCntr;
SIG_GROUP_ 145 DCChrgrSigGrp 1 : ChrgnNotAvlForFault ChrgnNotAvlForT DCChrgrConnectnSts DCChrgrSigGrpChks DCChrgrSigGrpCntr DchaNotAvlForFlt;
SIG_GROUP_ 655 DCDCActHVSigGrp 1 : DCDCActHVSigGrpChks DCDCActHVSigGrpCntr DCDCCurActHV DCDCUActHV;
SIG_GROUP_ 306 DCDCSigGrp 1 : DCDCCurAvlMaxLV DCDCFltLvlIndcn DCDCModSts DCDCSigGrpChks DCDCSigGrpCntr;
SIG_GROUP_ 148 HvbattCrsPwmStsSigGrp 1 : CrsPwmSts HvbattCrsPwmStsSigGrpChks HvbattCrsPwmStsSigGrpCntr;
SIG_GROUP_ 145 HvBattSigGrp 1 : HvBattActBusU HvBattActCur HvBattActPackU HvBattFltLvlIndcn HvBattMaxPwrChrgn HvBattMaxPwrDchrgn HvBattOverHeatWarn HvBattSigGrpChks HvBattSigGrpCntr HVOffReq MainNegCntctSts MainPosCntctSts;
SIG_GROUP_ 849 ImpctEvntStsSigGrp 1 : ImpctEvntSts ImpctEvntStsSigGrpChks ImpctEvntStsSigGrpCntr;
SIG_GROUP_ 849 ImpctEvntTypeSigGrp 1 : ImpctEvntType1 ImpctEvntType2 ImpctEvntType3 ImpctEvntType4 ImpctEvntType5 ImpctEvntType6 ImpctEvntType7 ImpctEvntTypeSigGrpChks ImpctEvntTypeSigGrpCntr;
SIG_GROUP_ 145 MainCntctStsSigGrp 1 : MainCntctCtrlFlg MainCntctSts MainCntctStsSigGrpChks MainCntctStsSigGrpCntr;
SIG_GROUP_ 655 OBCChrgnPortSigGrp 1 : OBCChrgnPortSigGrpChks OBCChrgnPortSigGrpCntr OBCChrgnPortTL1 OBCChrgnPortTL2 OBCChrgnPortTL3 OBCChrgnPortTN;
SIG_GROUP_ 320 OBCHvDcSigGrp 1 : OBCChrgnPwrMax OBCHvDcCurAct OBCHvDcSigGrpChks OBCHvDcSigGrpCntr OBCHvDcUAct;
SIG_GROUP_ 320 OBCSigGrp 1 : OBCCcConnectnSts OBCCpDutyFrq OBCCpSts OBCCpU OBCELockSts OBCFltLvlIndcn OBCS2Sts OBCSigGrpChks OBCSigGrpCntr;
SIG_GROUP_ 144 PwrModSigGrp 1 : PwrModSigGrpChks PwrModSigGrpCntr PwrModSts PwrModVld;
SIG_GROUP_ 166 ReMotModStsBkpSigGrp 1 : ReMotModStsBkp ReMotModStsBkpChks ReMotModStsBkpCntr;
SIG_GROUP_ 182 SCUAccrSnsr 1 : AccrSnsrAzFrntLe AccrSnsrAzFrntRi AccrSnsrAzRe SCUAccrSnsrChks SCUAccrSnsrCntr;
SIG_GROUP_ 144 VCUActGearSigGrp 1 : VCUActGearLvr VCUActGearLvrVld VCUActGearSigGrpChks VCUActGearSigGrpCntr;
SIG_GROUP_ 896 VCUBookChrgnStsSigGrp 1 : VCUBookChrgnSts VCUBookChrgnStsSigGrpChks VCUBookChrgnStsSigGrpCntr;
SIG_GROUP_ 287 VCUBoosterCntctReqSigGrp 1 : VCUBoosterCntctReq VCUBoosterCntctReqSigGrpChks VCUBoosterCntctReqSigGrpCntr;
SIG_GROUP_ 560 VCUCalcdActAuxPwrSigGrp 1 : VCUCalcdActAuxPwr VCUCalcdActAuxPwrSigGrpChks VCUCalcdActAuxPwrSigGrpCntr;
SIG_GROUP_ 151 VCUDCDCReqSigGrp 1 : VCUDCDCHVCurLim VCUDCDCLVCurLim VCUDCDCModReq VCUDCDCReqSigGrpChks VCUDCDCReqSigGrpCntr VCUDCDCULVSp;
SIG_GROUP_ 144 VcuInpSigGrp 1 : VCUAccrPedlRat VCUAccrPedlRatVld VCUDrvOffFcnLim VCUFrntEmTqRdy VCUGearLvrAvail VcuInpSigGrpChks VcuInpSigGrpCntr VCUPrkgBtnPsd VCUReEmTqRdy VCURgnTqCorrnFac VCUShifterMoveFlg VCUStsModCst VCUTarGearLvr VCUTarGearLvrVld VCUVirtAccrPedl VCUVirtAccrPedlVld;
SIG_GROUP_ 631 VCUOBCChrgnReqSigGrp 1 : VCUOBCChrgnCurReq VCUOBCChrgnReqSigGrpChks VCUOBCChrgnReqSigGrpCntr VCUOBCChrgnUReq;
SIG_GROUP_ 151 VCUOBCReqSigGrp 1 : VCUOBCELockReq VCUOBCModReq VCUOBCReqSigGrpChks VCUOBCReqSigGrpCntr VCUOBCS2Req;
SIG_GROUP_ 151 VCUReqToHvBattSigGrp 1 : VCUChrgnModReqToHvBatt VCUHvOffKeyReq VCUModReqToHvBatt VCUReqToHvBattSigGrpChks VCUReqToHvBattSigGrpCntr;
SIG_GROUP_ 135 VehCfgPrm 1 : VehCfgPrmBlkIDBytePosn1 VehCfgPrmCCPBytePosn2 VehCfgPrmCCPBytePosn3 VehCfgPrmCCPBytePosn4 VehCfgPrmCCPBytePosn5 VehCfgPrmCCPBytePosn6 VehCfgPrmCCPBytePosn7 VehCfgPrmCCPBytePosn8;
SIG_GROUP_ 179 WhlStsSigGrp 1 : VehSpd VehSpdVld WhlDirFrntLe WhlDirFrntLeVld WhlDirFrntRi WhlDirFrntRiVld WhlDirReLe WhlDirReLeVld WhlDirReRi WhlDirReRiVld WhlDstTiStampFrntLe WhlDstTiStampFrntRi WhlDstTiStampReLe WhlDstTiStampReRi WhlSpdEdgeFrntLe WhlSpdEdgeFrntLeVld WhlSpdEdgeFrntRi WhlSpdEdgeFrntRiVld WhlSpdEdgeReLe WhlSpdEdgeReLeVld WhlSpdEdgeReRi WhlSpdEdgeReRiVld WhlSpdFrntLe WhlSpdFrntLeVld WhlSpdFrntRi WhlSpdFrntRiVld WhlSpdReLe WhlSpdReLeVld WhlSpdReRi WhlSpdReRiVld WhlStsSigGrpChks WhlStsSigGrpCntr;
